VERSION "HINBNNNYNNNNNNNNNNNNNNNNNNNNNNNNNNNNNNNNNN/4/%%%/4/'%**4NNN///"

NS_ :

BS_:

BU_: dummy ZBE VVT1 VGSG SZL_LWS SM_FA SM_BF SHD RDC PGS PDC MRSZ LDM Kombi JBBF IHx FZD FRMFA_ALC FRMFA FFP EPS EKP EHC EGS_SSG Diagnosetool_PT_CAN Diagnosetool_K_CAN_System DWA DSC_DXC DME1_DDE1 CVM_V CID_V CCC_MASK_RAD CAS BMW_Tester1 AHM AFS_RP AFS ACC_Sensor RDU EBS RP_ECU_TVB
VAL_TABLE_ Wertetabelle_ST_GR_GRB 12 "8. Gang" 11 "7. Gang" 10 "6. Gang" 9 "5. Gang" 8 "4. Gang" 7 "3. Gang" 6 "2. Gang" 5 "1. Gang" 4 "Reserve" 3 "P" 2 "R" 1 "N" 0 "Reserve" ;

BO_ 3221225472 VECTOR__INDEPENDENT_SIG_MSG: 0 Vector__XXX
 SG_ ST_MDRV_DSC : 0|3@1+ (1,0) [0|0] "" Vector__XXX
 SG_ NeuesSignal_870 : 0|8@1+ (1,0) [0|0] "" Vector__XXX
 SG_ ST_INFT_ECBA : 0|3@1+ (1,0) [0|0] "" Vector__XXX
 SG_ ST_RCPT_ECBA : 0|2@1+ (1,0) [0|0] "" Vector__XXX
 SG_ ST_ECBA_SWO : 0|2@1+ (1,0) [0|0] "" Vector__XXX

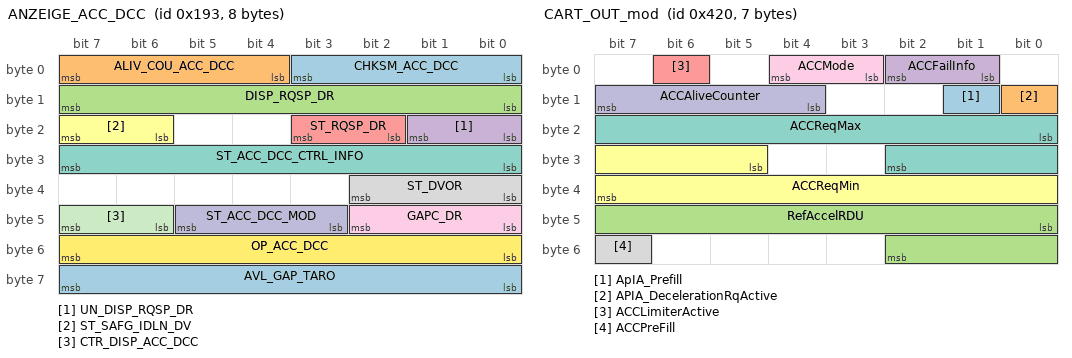
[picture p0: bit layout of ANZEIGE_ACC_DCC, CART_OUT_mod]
BO_ 403 ANZEIGE_ACC_DCC: 8 RDU
 SG_ CHKSM_ACC_DCC : 0|4@1+ (1,0) [0|0] "" Vector__XXX
 SG_ ALIV_COU_ACC_DCC : 4|4@1+ (1,0) [0|0] "" Vector__XXX
 SG_ DISP_RQSP_DR : 8|8@1+ (1,0) [0|250] "-" Vector__XXX
 SG_ UN_DISP_RQSP_DR : 16|2@1+ (1,0) [0|0] "" Vector__XXX
 SG_ ST_RQSP_DR : 18|2@1+ (1,0) [0|0] "" Vector__XXX
 SG_ ST_SAFG_IDLN_DV : 22|2@1+ (1,0) [0|0] "" Vector__XXX
 SG_ ST_ACC_DCC_CTRL_INFO : 24|8@1+ (1,0) [0|0] "" Vector__XXX
 SG_ ST_DVOR : 32|3@1+ (1,0) [0|0] "" Vector__XXX
 SG_ GAPC_DR : 40|3@1+ (1,0) [0|0] "" Vector__XXX
 SG_ ST_ACC_DCC_MOD : 43|3@1+ (1,0) [0|0] "" Vector__XXX
 SG_ CTR_DISP_ACC_DCC : 46|2@1+ (1,0) [0|0] "" Vector__XXX
 SG_ OP_ACC_DCC : 48|8@1+ (1,0) [0|0] "" Vector__XXX
 SG_ AVL_GAP_TARO : 56|8@1+ (1,0) [0|255] "" Vector__XXX

BO_ 1056 CART_OUT_mod: 7 RDU
 SG_ ApIA_Prefill : 9|1@0- (1,0) [0|0] "" Vector__XXX
 SG_ APIA_DecelerationRqActive : 8|1@0+ (1,0) [0|0] "" Vector__XXX
 SG_ RefAccelRDU : 40|11@1+ (0.01,-10.23) [-10.23|10.23] "m/s²" Vector__XXX
 SG_ ACCFailInfo : 1|2@1+ (1,0) [0|0] "" Vector__XXX
 SG_ ACCLimiterActive : 6|1@0+ (1,0) [0|1] "-" Vector__XXX
 SG_ ACCReqMin : 29|11@1+ (0.01,-10.23) [-10.23|10.23] "m/s²" Vector__XXX
 SG_ ACCReqMax : 16|11@1+ (0.01,-10.23) [-10.23|10.23] "m/s²" Vector__XXX
 SG_ ACCPreFill : 55|1@1+ (1,0) [0|1] "" Vector__XXX
 SG_ ACCMode : 3|2@1+ (1,0) [0|3] "" Vector__XXX
 SG_ ACCAliveCounter : 12|4@1+ (1,0) [0|15] "" Vector__XXX

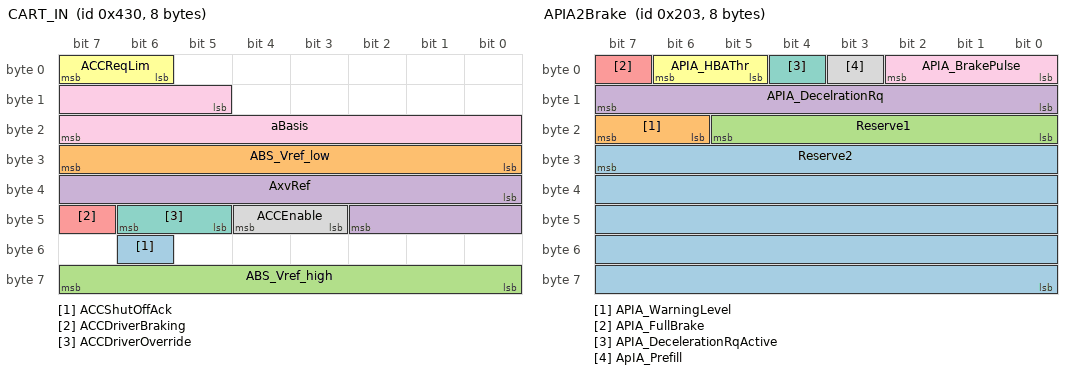
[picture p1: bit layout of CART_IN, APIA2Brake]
BO_ 1072 CART_IN: 8 EBS
 SG_ ACCShutOffAck : 54|1@1+ (1,0) [0|1] "" Vector__XXX
 SG_ ABS_Vref_low : 24|8@1+ (0.01,0) [0|0] "km/h" Vector__XXX
 SG_ ABS_Vref_high : 56|8@1- (0.01,0) [0|0] "km/h" Vector__XXX
 SG_ AxvRef : 32|11@1+ (0.01,-10.23) [-10.23|10.23] "m/s²"  RDU
 SG_ ACCDriverBraking : 47|1@1+ (1,0) [0|1] ""  RDU
 SG_ ACCReqLim : 6|2@1+ (1,0) [0|3] ""  RDU
 SG_ ACCDriverOverride : 45|2@1+ (1,0) [0|3] ""  RDU
 SG_ ACCEnable : 43|2@1+ (1,0) [0|3] ""  RDU
 SG_ aBasis : 13|11@1+ (0.01,-10.23) [-10.23|10.23] "m/s2"  RDU

BO_ 515 APIA2Brake: 8 RP_ECU_TVB
 SG_ Reserve2 : 31|40@0- (1,0) [0|0] "" Vector__XXX
 SG_ APIA_WarningLevel : 23|2@0+ (1,0) [0|0] "" Vector__XXX
 SG_ Reserve1 : 21|6@0- (1,0) [0|0] "" Vector__XXX
 SG_ APIA_DecelrationRq : 15|8@0+ (0.5,0) [0|127.5] "bar" Vector__XXX
 SG_ APIA_FullBrake : 7|1@0- (1,0) [0|0] "" Vector__XXX
 SG_ APIA_HBAThr : 6|2@0- (1,0) [0|0] "" Vector__XXX
 SG_ APIA_DecelerationRqActive : 4|1@0+ (1,0) [0|0] "" Vector__XXX
 SG_ ApIA_Prefill : 3|1@0- (1,0) [0|0] "" Vector__XXX
 SG_ APIA_BrakePulse : 2|3@0- (1,0) [0|0] "" Vector__XXX

BO_ 921 STAT_MDRIVE: 5 dummy
 SG_ ST_MDRV_DSC : 10|3@1+ (1,0) [0|0] "" Vector__XXX
 SG_ ST_MDRV : 8|2@1+ (1,0) [0|0] "" Vector__XXX
 SG_ ALIV_ST_MDRV : 4|4@1+ (1,0) [0|0] "" Vector__XXX
 SG_ CHKSM_ST_MDRV : 0|4@1+ (1,0) [0|0] "" Vector__XXX

BO_ 1777 Diag_Tester1: 8 BMW_Tester1
 SG_ TPCI : 8|8@1+ (1,0) [0|0] ""  VGSG,JBBF,FRMFA_ALC,EPS,EKP,EGS_SSG,DSC_DXC,DME1_DDE1,BMW_Tester1,AFS,ACC_Sensor
 SG_ TA : 0|8@1+ (1,0) [0|0] ""  VGSG,JBBF,FRMFA_ALC,EPS,EKP,EGS_SSG,DSC_DXC,DME1_DDE1,BMW_Tester1,AFS,ACC_Sensor
 SG_ Byte8 : 56|8@1+ (1,0) [0|0] ""  VGSG,JBBF,FRMFA_ALC,EPS,EKP,EGS_SSG,DSC_DXC,DME1_DDE1,BMW_Tester1,AFS,ACC_Sensor
 SG_ Byte7 : 48|8@1+ (1,0) [0|0] ""  VGSG,JBBF,FRMFA_ALC,EPS,EKP,EGS_SSG,DSC_DXC,DME1_DDE1,BMW_Tester1,AFS,ACC_Sensor
 SG_ Byte6 : 40|8@1+ (1,0) [0|0] ""  VGSG,JBBF,FRMFA_ALC,EPS,EKP,EGS_SSG,DSC_DXC,DME1_DDE1,BMW_Tester1,AFS,ACC_Sensor
 SG_ Byte5 : 32|8@1+ (1,0) [0|0] ""  VGSG,JBBF,FRMFA_ALC,EPS,EKP,EGS_SSG,DSC_DXC,DME1_DDE1,BMW_Tester1,AFS,ACC_Sensor
 SG_ Byte4 : 24|8@1+ (1,0) [0|0] ""  VGSG,JBBF,FRMFA_ALC,EPS,EKP,EGS_SSG,DSC_DXC,DME1_DDE1,BMW_Tester1,AFS,ACC_Sensor
 SG_ Byte3 : 16|8@1+ (1,0) [0|0] ""  VGSG,JBBF,FRMFA_ALC,EPS,EKP,EGS_SSG,DSC_DXC,DME1_DDE1,BMW_Tester1,AFS,ACC_Sensor

BO_ 1650 Diag_FRMFA_ALC: 8 FRMFA_ALC
 SG_ TPCI : 8|8@1+ (1,0) [0|0] ""  BMW_Tester1
 SG_ TA : 0|8@1+ (1,0) [0|0] ""  BMW_Tester1
 SG_ Byte8 : 56|8@1+ (1,0) [0|0] ""  BMW_Tester1
 SG_ Byte7 : 48|8@1+ (1,0) [0|0] ""  BMW_Tester1
 SG_ Byte6 : 40|8@1+ (1,0) [0|0] ""  BMW_Tester1
 SG_ Byte5 : 32|8@1+ (1,0) [0|0] ""  BMW_Tester1
 SG_ Byte4 : 24|8@1+ (1,0) [0|0] ""  BMW_Tester1
 SG_ Byte3 : 16|8@1+ (1,0) [0|0] ""  BMW_Tester1

BO_ 1584 Diag_EPS: 8 EPS
 SG_ TPCI : 8|8@1+ (1,0) [0|0] ""  BMW_Tester1
 SG_ TA : 0|8@1+ (1,0) [0|0] ""  BMW_Tester1
 SG_ Byte8 : 56|8@1+ (1,0) [0|0] ""  BMW_Tester1
 SG_ Byte7 : 48|8@1+ (1,0) [0|0] ""  BMW_Tester1
 SG_ Byte6 : 40|8@1+ (1,0) [0|0] ""  BMW_Tester1
 SG_ Byte5 : 32|8@1+ (1,0) [0|0] ""  BMW_Tester1
 SG_ Byte4 : 24|8@1+ (1,0) [0|0] ""  BMW_Tester1
 SG_ Byte3 : 16|8@1+ (1,0) [0|0] ""  BMW_Tester1

BO_ 1577 Diag_DSC_DXC: 8 DSC_DXC
 SG_ TPCI : 8|8@1+ (1,0) [0|0] ""  BMW_Tester1
 SG_ TA : 0|8@1+ (1,0) [0|0] ""  BMW_Tester1
 SG_ Byte8 : 56|8@1+ (1,0) [0|0] ""  BMW_Tester1
 SG_ Byte7 : 48|8@1+ (1,0) [0|0] ""  BMW_Tester1
 SG_ Byte6 : 40|8@1+ (1,0) [0|0] ""  BMW_Tester1
 SG_ Byte5 : 32|8@1+ (1,0) [0|0] ""  BMW_Tester1
 SG_ Byte4 : 24|8@1+ (1,0) [0|0] ""  BMW_Tester1
 SG_ Byte3 : 16|8@1+ (1,0) [0|0] ""  BMW_Tester1

BO_ 1569 Diag_ACC_Sensor: 8 ACC_Sensor
 SG_ TPCI : 8|8@1+ (1,0) [0|0] ""  BMW_Tester1
 SG_ TA : 0|8@1+ (1,0) [0|0] ""  BMW_Tester1
 SG_ Byte8 : 56|8@1+ (1,0) [0|0] ""  BMW_Tester1
 SG_ Byte7 : 48|8@1+ (1,0) [0|0] ""  BMW_Tester1
 SG_ Byte6 : 40|8@1+ (1,0) [0|0] ""  BMW_Tester1
 SG_ Byte5 : 32|8@1+ (1,0) [0|0] ""  BMW_Tester1
 SG_ Byte4 : 24|8@1+ (1,0) [0|0] ""  BMW_Tester1
 SG_ Byte3 : 16|8@1+ (1,0) [0|0] ""  BMW_Tester1

BO_ 1565 Diag_FFP: 8 FFP
 SG_ TPCI : 8|8@1+ (1,0) [0|0] ""  ACC_Sensor,AFS,BMW_Tester1,DME1_DDE1,DSC_DXC,EGS_SSG,EKP,EPS,FRMFA_ALC,JBBF,VGSG
 SG_ TA : 0|8@1+ (1,0) [0|0] ""  ACC_Sensor,AFS,BMW_Tester1,DME1_DDE1,DSC_DXC,EGS_SSG,EKP,EPS,FRMFA_ALC,JBBF,VGSG
 SG_ Byte8 : 56|8@1+ (1,0) [0|0] ""  ACC_Sensor,AFS,BMW_Tester1,DME1_DDE1,DSC_DXC,EGS_SSG,EKP,EPS,FRMFA_ALC,JBBF,VGSG
 SG_ Byte7 : 48|8@1+ (1,0) [0|0] ""  ACC_Sensor,AFS,BMW_Tester1,DME1_DDE1,DSC_DXC,EGS_SSG,EKP,EPS,FRMFA_ALC,JBBF,VGSG
 SG_ Byte6 : 40|8@1+ (1,0) [0|0] ""  ACC_Sensor,AFS,BMW_Tester1,DME1_DDE1,DSC_DXC,EGS_SSG,EKP,EPS,FRMFA_ALC,JBBF,VGSG
 SG_ Byte5 : 32|8@1+ (1,0) [0|0] ""  ACC_Sensor,AFS,BMW_Tester1,DME1_DDE1,DSC_DXC,EGS_SSG,EKP,EPS,FRMFA_ALC,JBBF,VGSG
 SG_ Byte4 : 24|8@1+ (1,0) [0|0] ""  ACC_Sensor,AFS,BMW_Tester1,DME1_DDE1,DSC_DXC,EGS_SSG,EKP,EPS,FRMFA_ALC,JBBF,VGSG
 SG_ Byte3 : 16|8@1+ (1,0) [0|0] ""  ACC_Sensor,AFS,BMW_Tester1,DME1_DDE1,DSC_DXC,EGS_SSG,EKP,EPS,FRMFA_ALC,JBBF,VGSG

BO_ 1564 Diag_LDM: 8 LDM
 SG_ TPCI : 8|8@1+ (1,0) [0|0] ""  VGSG,JBBF,FRMFA_ALC,EPS,EKP,EGS_SSG,DSC_DXC,DME1_DDE1,BMW_Tester1,AFS,ACC_Sensor
 SG_ TA : 0|8@1+ (1,0) [0|0] ""  VGSG,JBBF,FRMFA_ALC,EPS,EKP,EGS_SSG,DSC_DXC,DME1_DDE1,BMW_Tester1,AFS,ACC_Sensor
 SG_ Byte8 : 56|8@1+ (1,0) [0|0] ""  VGSG,JBBF,FRMFA_ALC,EPS,EKP,EGS_SSG,DSC_DXC,DME1_DDE1,BMW_Tester1,AFS,ACC_Sensor
 SG_ Byte7 : 48|8@1+ (1,0) [0|0] ""  VGSG,JBBF,FRMFA_ALC,EPS,EKP,EGS_SSG,DSC_DXC,DME1_DDE1,BMW_Tester1,AFS,ACC_Sensor
 SG_ Byte6 : 40|8@1+ (1,0) [0|0] ""  VGSG,JBBF,FRMFA_ALC,EPS,EKP,EGS_SSG,DSC_DXC,DME1_DDE1,BMW_Tester1,AFS,ACC_Sensor
 SG_ Byte5 : 32|8@1+ (1,0) [0|0] ""  VGSG,JBBF,FRMFA_ALC,EPS,EKP,EGS_SSG,DSC_DXC,DME1_DDE1,BMW_Tester1,AFS,ACC_Sensor
 SG_ Byte4 : 24|8@1+ (1,0) [0|0] ""  VGSG,JBBF,FRMFA_ALC,EPS,EKP,EGS_SSG,DSC_DXC,DME1_DDE1,BMW_Tester1,AFS,ACC_Sensor
 SG_ Byte3 : 16|8@1+ (1,0) [0|0] ""  VGSG,JBBF,FRMFA_ALC,EPS,EKP,EGS_SSG,DSC_DXC,DME1_DDE1,BMW_Tester1,AFS,ACC_Sensor

BO_ 1561 Diag_VGSG: 8 VGSG
 SG_ TPCI : 8|8@1+ (1,0) [0|0] ""  BMW_Tester1
 SG_ TA : 0|8@1+ (1,0) [0|0] ""  BMW_Tester1
 SG_ Byte8 : 56|8@1+ (1,0) [0|0] ""  BMW_Tester1
 SG_ Byte7 : 48|8@1+ (1,0) [0|0] ""  BMW_Tester1
 SG_ Byte6 : 40|8@1+ (1,0) [0|0] ""  BMW_Tester1
 SG_ Byte5 : 32|8@1+ (1,0) [0|0] ""  BMW_Tester1
 SG_ Byte4 : 24|8@1+ (1,0) [0|0] ""  BMW_Tester1
 SG_ Byte3 : 16|8@1+ (1,0) [0|0] ""  BMW_Tester1

BO_ 1560 Diag_EGS_SSG: 8 EGS_SSG
 SG_ TPCI : 8|8@1+ (1,0) [0|0] ""  BMW_Tester1
 SG_ TA : 0|8@1+ (1,0) [0|0] ""  BMW_Tester1
 SG_ Byte8 : 56|8@1+ (1,0) [0|0] ""  BMW_Tester1
 SG_ Byte7 : 48|8@1+ (1,0) [0|0] ""  BMW_Tester1
 SG_ Byte6 : 40|8@1+ (1,0) [0|0] ""  BMW_Tester1
 SG_ Byte5 : 32|8@1+ (1,0) [0|0] ""  BMW_Tester1
 SG_ Byte4 : 24|8@1+ (1,0) [0|0] ""  BMW_Tester1
 SG_ Byte3 : 16|8@1+ (1,0) [0|0] ""  BMW_Tester1

BO_ 1559 Diag_EKP: 8 EKP
 SG_ TPCI : 8|8@1+ (1,0) [0|0] ""  BMW_Tester1
 SG_ TA : 0|8@1+ (1,0) [0|0] ""  BMW_Tester1
 SG_ Byte8 : 56|8@1+ (1,0) [0|0] ""  BMW_Tester1
 SG_ Byte7 : 48|8@1+ (1,0) [0|0] ""  BMW_Tester1
 SG_ Byte6 : 40|8@1+ (1,0) [0|0] ""  BMW_Tester1
 SG_ Byte5 : 32|8@1+ (1,0) [0|0] ""  BMW_Tester1
 SG_ Byte4 : 24|8@1+ (1,0) [0|0] ""  BMW_Tester1
 SG_ Byte3 : 16|8@1+ (1,0) [0|0] ""  BMW_Tester1

BO_ 1558 Diag_AFS: 8 AFS
 SG_ TPCI : 8|8@1+ (1,0) [0|0] ""  BMW_Tester1
 SG_ TA : 0|8@1+ (1,0) [0|0] ""  BMW_Tester1
 SG_ Byte8 : 56|8@1+ (1,0) [0|0] ""  BMW_Tester1
 SG_ Byte7 : 48|8@1+ (1,0) [0|0] ""  BMW_Tester1
 SG_ Byte6 : 40|8@1+ (1,0) [0|0] ""  BMW_Tester1
 SG_ Byte5 : 32|8@1+ (1,0) [0|0] ""  BMW_Tester1
 SG_ Byte4 : 24|8@1+ (1,0) [0|0] ""  BMW_Tester1
 SG_ Byte3 : 16|8@1+ (1,0) [0|0] ""  BMW_Tester1

BO_ 1554 Diag_DME1_DDE1: 8 DME1_DDE1
 SG_ TPCI : 8|8@1+ (1,0) [0|0] ""  BMW_Tester1
 SG_ TA : 0|8@1+ (1,0) [0|0] ""  BMW_Tester1
 SG_ Byte8 : 56|8@1+ (1,0) [0|0] ""  BMW_Tester1
 SG_ Byte7 : 48|8@1+ (1,0) [0|0] ""  BMW_Tester1
 SG_ Byte6 : 40|8@1+ (1,0) [0|0] ""  BMW_Tester1
 SG_ Byte5 : 32|8@1+ (1,0) [0|0] ""  BMW_Tester1
 SG_ Byte4 : 24|8@1+ (1,0) [0|0] ""  BMW_Tester1
 SG_ Byte3 : 16|8@1+ (1,0) [0|0] ""  BMW_Tester1

BO_ 1536 Diag_JBBF: 8 JBBF
 SG_ TPCI : 8|8@1+ (1,0) [0|0] ""  VGSG,JBBF,FRMFA_ALC,EPS,EKP,EGS_SSG,DSC_DXC,DME1_DDE1,BMW_Tester1,AFS,ACC_Sensor
 SG_ TA : 0|8@1+ (1,0) [0|0] ""  VGSG,JBBF,FRMFA_ALC,EPS,EKP,EGS_SSG,DSC_DXC,DME1_DDE1,BMW_Tester1,AFS,ACC_Sensor
 SG_ Byte8 : 56|8@1+ (1,0) [0|0] ""  VGSG,JBBF,FRMFA_ALC,EPS,EKP,EGS_SSG,DSC_DXC,DME1_DDE1,BMW_Tester1,AFS,ACC_Sensor
 SG_ Byte7 : 48|8@1+ (1,0) [0|0] ""  VGSG,JBBF,FRMFA_ALC,EPS,EKP,EGS_SSG,DSC_DXC,DME1_DDE1,BMW_Tester1,AFS,ACC_Sensor
 SG_ Byte6 : 40|8@1+ (1,0) [0|0] ""  VGSG,JBBF,FRMFA_ALC,EPS,EKP,EGS_SSG,DSC_DXC,DME1_DDE1,BMW_Tester1,AFS,ACC_Sensor
 SG_ Byte5 : 32|8@1+ (1,0) [0|0] ""  VGSG,JBBF,FRMFA_ALC,EPS,EKP,EGS_SSG,DSC_DXC,DME1_DDE1,BMW_Tester1,AFS,ACC_Sensor
 SG_ Byte4 : 24|8@1+ (1,0) [0|0] ""  VGSG,JBBF,FRMFA_ALC,EPS,EKP,EGS_SSG,DSC_DXC,DME1_DDE1,BMW_Tester1,AFS,ACC_Sensor
 SG_ Byte3 : 16|8@1+ (1,0) [0|0] ""  VGSG,JBBF,FRMFA_ALC,EPS,EKP,EGS_SSG,DSC_DXC,DME1_DDE1,BMW_Tester1,AFS,ACC_Sensor

BO_ 1504 Rq_Test: 8 FRMFA_ALC
 SG_ ID2 : 0|8@1+ (1,0) [0|0] ""  VGSG,JBBF,EPS,EKP,EGS_SSG,DSC_DXC,DME1_DDE1,AFS,ACC_Sensor
 SG_ Byte7 : 56|8@1+ (1,0) [0|0] ""  VGSG,JBBF,EPS,EKP,EGS_SSG,DSC_DXC,DME1_DDE1,AFS,ACC_Sensor
 SG_ Byte6 : 48|8@1+ (1,0) [0|0] ""  VGSG,JBBF,EPS,EKP,EGS_SSG,DSC_DXC,DME1_DDE1,AFS,ACC_Sensor
 SG_ Byte5 : 40|8@1+ (1,0) [0|0] ""  VGSG,JBBF,EPS,EKP,EGS_SSG,DSC_DXC,DME1_DDE1,AFS,ACC_Sensor
 SG_ Byte4 : 32|8@1+ (1,0) [0|0] ""  VGSG,JBBF,EPS,EKP,EGS_SSG,DSC_DXC,DME1_DDE1,AFS,ACC_Sensor
 SG_ Byte3 : 24|8@1+ (1,0) [0|0] ""  VGSG,JBBF,EPS,EKP,EGS_SSG,DSC_DXC,DME1_DDE1,AFS,ACC_Sensor
 SG_ Byte2 : 16|8@1+ (1,0) [0|0] ""  VGSG,JBBF,EPS,EKP,EGS_SSG,DSC_DXC,DME1_DDE1,AFS,ACC_Sensor
 SG_ Byte1 : 8|8@1+ (1,0) [0|0] ""  VGSG,JBBF,EPS,EKP,EGS_SSG,DSC_DXC,DME1_DDE1,AFS,ACC_Sensor

BO_ 1456 Rq_EPS: 8 EPS
 SG_ ID2 : 0|8@1+ (1,0) [0|0] ""  VGSG,JBBF,FRMFA_ALC,EKP,EGS_SSG,DSC_DXC,DME1_DDE1,AFS,ACC_Sensor
 SG_ Byte7 : 56|8@1+ (1,0) [0|0] ""  VGSG,JBBF,FRMFA_ALC,EKP,EGS_SSG,DSC_DXC,DME1_DDE1,AFS,ACC_Sensor
 SG_ Byte6 : 48|8@1+ (1,0) [0|0] ""  VGSG,JBBF,FRMFA_ALC,EKP,EGS_SSG,DSC_DXC,DME1_DDE1,AFS,ACC_Sensor
 SG_ Byte5 : 40|8@1+ (1,0) [0|0] ""  VGSG,JBBF,FRMFA_ALC,EKP,EGS_SSG,DSC_DXC,DME1_DDE1,AFS,ACC_Sensor
 SG_ Byte4 : 32|8@1+ (1,0) [0|0] ""  VGSG,JBBF,FRMFA_ALC,EKP,EGS_SSG,DSC_DXC,DME1_DDE1,AFS,ACC_Sensor
 SG_ Byte3 : 24|8@1+ (1,0) [0|0] ""  VGSG,JBBF,FRMFA_ALC,EKP,EGS_SSG,DSC_DXC,DME1_DDE1,AFS,ACC_Sensor
 SG_ Byte2 : 16|8@1+ (1,0) [0|0] ""  VGSG,JBBF,FRMFA_ALC,EKP,EGS_SSG,DSC_DXC,DME1_DDE1,AFS,ACC_Sensor
 SG_ Byte1 : 8|8@1+ (1,0) [0|0] ""  VGSG,JBBF,FRMFA_ALC,EKP,EGS_SSG,DSC_DXC,DME1_DDE1,AFS,ACC_Sensor

BO_ 1449 Rq_DSC_DXC: 8 DSC_DXC
 SG_ ID2 : 0|8@1+ (1,0) [0|0] ""  VGSG,JBBF,FRMFA_ALC,EPS,EKP,EGS_SSG,DME1_DDE1,AFS,ACC_Sensor
 SG_ Byte7 : 56|8@1+ (1,0) [0|0] ""  VGSG,JBBF,FRMFA_ALC,EPS,EKP,EGS_SSG,DME1_DDE1,AFS,ACC_Sensor
 SG_ Byte6 : 48|8@1+ (1,0) [0|0] ""  VGSG,JBBF,FRMFA_ALC,EPS,EKP,EGS_SSG,DME1_DDE1,AFS,ACC_Sensor
 SG_ Byte5 : 40|8@1+ (1,0) [0|0] ""  VGSG,JBBF,FRMFA_ALC,EPS,EKP,EGS_SSG,DME1_DDE1,AFS,ACC_Sensor
 SG_ Byte4 : 32|8@1+ (1,0) [0|0] ""  VGSG,JBBF,FRMFA_ALC,EPS,EKP,EGS_SSG,DME1_DDE1,AFS,ACC_Sensor
 SG_ Byte3 : 24|8@1+ (1,0) [0|0] ""  VGSG,JBBF,FRMFA_ALC,EPS,EKP,EGS_SSG,DME1_DDE1,AFS,ACC_Sensor
 SG_ Byte2 : 16|8@1+ (1,0) [0|0] ""  VGSG,JBBF,FRMFA_ALC,EPS,EKP,EGS_SSG,DME1_DDE1,AFS,ACC_Sensor
 SG_ Byte1 : 8|8@1+ (1,0) [0|0] ""  VGSG,JBBF,FRMFA_ALC,EPS,EKP,EGS_SSG,DME1_DDE1,AFS,ACC_Sensor

BO_ 1441 Rq_ACC_Sensor: 8 ACC_Sensor
 SG_ ID2 : 0|8@1+ (1,0) [0|0] ""  VGSG,JBBF,FRMFA_ALC,EPS,EKP,EGS_SSG,DSC_DXC,DME1_DDE1,AFS
 SG_ Byte7 : 56|8@1+ (1,0) [0|0] ""  VGSG,JBBF,FRMFA_ALC,EPS,EKP,EGS_SSG,DSC_DXC,DME1_DDE1,AFS
 SG_ Byte6 : 48|8@1+ (1,0) [0|0] ""  VGSG,JBBF,FRMFA_ALC,EPS,EKP,EGS_SSG,DSC_DXC,DME1_DDE1,AFS
 SG_ Byte5 : 40|8@1+ (1,0) [0|0] ""  VGSG,JBBF,FRMFA_ALC,EPS,EKP,EGS_SSG,DSC_DXC,DME1_DDE1,AFS
 SG_ Byte4 : 32|8@1+ (1,0) [0|0] ""  VGSG,JBBF,FRMFA_ALC,EPS,EKP,EGS_SSG,DSC_DXC,DME1_DDE1,AFS
 SG_ Byte3 : 24|8@1+ (1,0) [0|0] ""  VGSG,JBBF,FRMFA_ALC,EPS,EKP,EGS_SSG,DSC_DXC,DME1_DDE1,AFS
 SG_ Byte2 : 16|8@1+ (1,0) [0|0] ""  VGSG,JBBF,FRMFA_ALC,EPS,EKP,EGS_SSG,DSC_DXC,DME1_DDE1,AFS
 SG_ Byte1 : 8|8@1+ (1,0) [0|0] ""  VGSG,JBBF,FRMFA_ALC,EPS,EKP,EGS_SSG,DSC_DXC,DME1_DDE1,AFS

BO_ 1437 Rq_FFP: 8 FFP
 SG_ ID2 : 0|8@1+ (1,0) [0|0] ""  ACC_Sensor,AFS,DME1_DDE1,DSC_DXC,EGS_SSG,EKP,EPS,FRMFA_ALC,JBBF,VGSG
 SG_ Byte7 : 56|8@1+ (1,0) [0|0] ""  ACC_Sensor,AFS,DME1_DDE1,DSC_DXC,EGS_SSG,EKP,EPS,FRMFA_ALC,JBBF,VGSG
 SG_ Byte6 : 48|8@1+ (1,0) [0|0] ""  ACC_Sensor,AFS,DME1_DDE1,DSC_DXC,EGS_SSG,EKP,EPS,FRMFA_ALC,JBBF,VGSG
 SG_ Byte5 : 40|8@1+ (1,0) [0|0] ""  ACC_Sensor,AFS,DME1_DDE1,DSC_DXC,EGS_SSG,EKP,EPS,FRMFA_ALC,JBBF,VGSG
 SG_ Byte4 : 32|8@1+ (1,0) [0|0] ""  ACC_Sensor,AFS,DME1_DDE1,DSC_DXC,EGS_SSG,EKP,EPS,FRMFA_ALC,JBBF,VGSG
 SG_ Byte3 : 24|8@1+ (1,0) [0|0] ""  ACC_Sensor,AFS,DME1_DDE1,DSC_DXC,EGS_SSG,EKP,EPS,FRMFA_ALC,JBBF,VGSG
 SG_ Byte2 : 16|8@1+ (1,0) [0|0] ""  ACC_Sensor,AFS,DME1_DDE1,DSC_DXC,EGS_SSG,EKP,EPS,FRMFA_ALC,JBBF,VGSG
 SG_ Byte1 : 8|8@1+ (1,0) [0|0] ""  ACC_Sensor,AFS,DME1_DDE1,DSC_DXC,EGS_SSG,EKP,EPS,FRMFA_ALC,JBBF,VGSG

BO_ 1436 Rq_LDM: 8 LDM
 SG_ ID2 : 0|8@1+ (1,0) [0|0] ""  VGSG,JBBF,FRMFA_ALC,EPS,EKP,EGS_SSG,DSC_DXC,DME1_DDE1,AFS,ACC_Sensor
 SG_ Byte7 : 56|8@1+ (1,0) [0|0] ""  VGSG,JBBF,FRMFA_ALC,EPS,EKP,EGS_SSG,DSC_DXC,DME1_DDE1,AFS,ACC_Sensor
 SG_ Byte6 : 48|8@1+ (1,0) [0|0] ""  VGSG,JBBF,FRMFA_ALC,EPS,EKP,EGS_SSG,DSC_DXC,DME1_DDE1,AFS,ACC_Sensor
 SG_ Byte5 : 40|8@1+ (1,0) [0|0] ""  VGSG,JBBF,FRMFA_ALC,EPS,EKP,EGS_SSG,DSC_DXC,DME1_DDE1,AFS,ACC_Sensor
 SG_ Byte4 : 32|8@1+ (1,0) [0|0] ""  VGSG,JBBF,FRMFA_ALC,EPS,EKP,EGS_SSG,DSC_DXC,DME1_DDE1,AFS,ACC_Sensor
 SG_ Byte3 : 24|8@1+ (1,0) [0|0] ""  VGSG,JBBF,FRMFA_ALC,EPS,EKP,EGS_SSG,DSC_DXC,DME1_DDE1,AFS,ACC_Sensor
 SG_ Byte2 : 16|8@1+ (1,0) [0|0] ""  VGSG,JBBF,FRMFA_ALC,EPS,EKP,EGS_SSG,DSC_DXC,DME1_DDE1,AFS,ACC_Sensor
 SG_ Byte1 : 8|8@1+ (1,0) [0|0] ""  VGSG,JBBF,FRMFA_ALC,EPS,EKP,EGS_SSG,DSC_DXC,DME1_DDE1,AFS,ACC_Sensor

BO_ 1433 Rq_VGSG: 8 VGSG
 SG_ ID2 : 0|8@1+ (1,0) [0|0] ""  JBBF,FRMFA_ALC,EPS,EKP,EGS_SSG,DSC_DXC,DME1_DDE1,AFS,ACC_Sensor
 SG_ Byte7 : 56|8@1+ (1,0) [0|0] ""  JBBF,FRMFA_ALC,EPS,EKP,EGS_SSG,DSC_DXC,DME1_DDE1,AFS,ACC_Sensor
 SG_ Byte6 : 48|8@1+ (1,0) [0|0] ""  JBBF,FRMFA_ALC,EPS,EKP,EGS_SSG,DSC_DXC,DME1_DDE1,AFS,ACC_Sensor
 SG_ Byte5 : 40|8@1+ (1,0) [0|0] ""  JBBF,FRMFA_ALC,EPS,EKP,EGS_SSG,DSC_DXC,DME1_DDE1,AFS,ACC_Sensor
 SG_ Byte4 : 32|8@1+ (1,0) [0|0] ""  JBBF,FRMFA_ALC,EPS,EKP,EGS_SSG,DSC_DXC,DME1_DDE1,AFS,ACC_Sensor
 SG_ Byte3 : 24|8@1+ (1,0) [0|0] ""  JBBF,FRMFA_ALC,EPS,EKP,EGS_SSG,DSC_DXC,DME1_DDE1,AFS,ACC_Sensor
 SG_ Byte2 : 16|8@1+ (1,0) [0|0] ""  JBBF,FRMFA_ALC,EPS,EKP,EGS_SSG,DSC_DXC,DME1_DDE1,AFS,ACC_Sensor
 SG_ Byte1 : 8|8@1+ (1,0) [0|0] ""  JBBF,FRMFA_ALC,EPS,EKP,EGS_SSG,DSC_DXC,DME1_DDE1,AFS,ACC_Sensor

BO_ 1432 Rq_EGS_SSG: 8 EGS_SSG
 SG_ ID2 : 0|8@1+ (1,0) [0|0] ""  VGSG,JBBF,FRMFA_ALC,EPS,EKP,DSC_DXC,DME1_DDE1,AFS,ACC_Sensor
 SG_ Byte7 : 56|8@1+ (1,0) [0|0] ""  VGSG,JBBF,FRMFA_ALC,EPS,EKP,DSC_DXC,DME1_DDE1,AFS,ACC_Sensor
 SG_ Byte6 : 48|8@1+ (1,0) [0|0] ""  VGSG,JBBF,FRMFA_ALC,EPS,EKP,DSC_DXC,DME1_DDE1,AFS,ACC_Sensor
 SG_ Byte5 : 40|8@1+ (1,0) [0|0] ""  VGSG,JBBF,FRMFA_ALC,EPS,EKP,DSC_DXC,DME1_DDE1,AFS,ACC_Sensor
 SG_ Byte4 : 32|8@1+ (1,0) [0|0] ""  VGSG,JBBF,FRMFA_ALC,EPS,EKP,DSC_DXC,DME1_DDE1,AFS,ACC_Sensor
 SG_ Byte3 : 24|8@1+ (1,0) [0|0] ""  VGSG,JBBF,FRMFA_ALC,EPS,EKP,DSC_DXC,DME1_DDE1,AFS,ACC_Sensor
 SG_ Byte2 : 16|8@1+ (1,0) [0|0] ""  VGSG,JBBF,FRMFA_ALC,EPS,EKP,DSC_DXC,DME1_DDE1,AFS,ACC_Sensor
 SG_ Byte1 : 8|8@1+ (1,0) [0|0] ""  VGSG,JBBF,FRMFA_ALC,EPS,EKP,DSC_DXC,DME1_DDE1,AFS,ACC_Sensor

BO_ 1431 Rq_EKP: 8 EKP
 SG_ ID2 : 0|8@1+ (1,0) [0|0] ""  VGSG,JBBF,FRMFA_ALC,EPS,EGS_SSG,DSC_DXC,DME1_DDE1,AFS,ACC_Sensor
 SG_ Byte7 : 56|8@1+ (1,0) [0|0] ""  VGSG,JBBF,FRMFA_ALC,EPS,EGS_SSG,DSC_DXC,DME1_DDE1,AFS,ACC_Sensor
 SG_ Byte6 : 48|8@1+ (1,0) [0|0] ""  VGSG,JBBF,FRMFA_ALC,EPS,EGS_SSG,DSC_DXC,DME1_DDE1,AFS,ACC_Sensor
 SG_ Byte5 : 40|8@1+ (1,0) [0|0] ""  VGSG,JBBF,FRMFA_ALC,EPS,EGS_SSG,DSC_DXC,DME1_DDE1,AFS,ACC_Sensor
 SG_ Byte4 : 32|8@1+ (1,0) [0|0] ""  VGSG,JBBF,FRMFA_ALC,EPS,EGS_SSG,DSC_DXC,DME1_DDE1,AFS,ACC_Sensor
 SG_ Byte3 : 24|8@1+ (1,0) [0|0] ""  VGSG,JBBF,FRMFA_ALC,EPS,EGS_SSG,DSC_DXC,DME1_DDE1,AFS,ACC_Sensor
 SG_ Byte2 : 16|8@1+ (1,0) [0|0] ""  VGSG,JBBF,FRMFA_ALC,EPS,EGS_SSG,DSC_DXC,DME1_DDE1,AFS,ACC_Sensor
 SG_ Byte1 : 8|8@1+ (1,0) [0|0] ""  VGSG,JBBF,FRMFA_ALC,EPS,EGS_SSG,DSC_DXC,DME1_DDE1,AFS,ACC_Sensor

BO_ 1430 Rq_AFS: 8 AFS
 SG_ ID2 : 0|8@1+ (1,0) [0|0] ""  VGSG,JBBF,FRMFA_ALC,EPS,EKP,EGS_SSG,DSC_DXC,DME1_DDE1,ACC_Sensor
 SG_ Byte7 : 56|8@1+ (1,0) [0|0] ""  VGSG,JBBF,FRMFA_ALC,EPS,EKP,EGS_SSG,DSC_DXC,DME1_DDE1,ACC_Sensor
 SG_ Byte6 : 48|8@1+ (1,0) [0|0] ""  VGSG,JBBF,FRMFA_ALC,EPS,EKP,EGS_SSG,DSC_DXC,DME1_DDE1,ACC_Sensor
 SG_ Byte5 : 40|8@1+ (1,0) [0|0] ""  VGSG,JBBF,FRMFA_ALC,EPS,EKP,EGS_SSG,DSC_DXC,DME1_DDE1,ACC_Sensor
 SG_ Byte4 : 32|8@1+ (1,0) [0|0] ""  VGSG,JBBF,FRMFA_ALC,EPS,EKP,EGS_SSG,DSC_DXC,DME1_DDE1,ACC_Sensor
 SG_ Byte3 : 24|8@1+ (1,0) [0|0] ""  VGSG,JBBF,FRMFA_ALC,EPS,EKP,EGS_SSG,DSC_DXC,DME1_DDE1,ACC_Sensor
 SG_ Byte2 : 16|8@1+ (1,0) [0|0] ""  VGSG,JBBF,FRMFA_ALC,EPS,EKP,EGS_SSG,DSC_DXC,DME1_DDE1,ACC_Sensor
 SG_ Byte1 : 8|8@1+ (1,0) [0|0] ""  VGSG,JBBF,FRMFA_ALC,EPS,EKP,EGS_SSG,DSC_DXC,DME1_DDE1,ACC_Sensor

BO_ 1426 Rq_DME1_DDE1: 8 DME1_DDE1
 SG_ ID2 : 0|8@1+ (1,0) [0|0] ""  VGSG,JBBF,FRMFA_ALC,EPS,EKP,EGS_SSG,DSC_DXC,AFS,ACC_Sensor
 SG_ Byte7 : 56|8@1+ (1,0) [0|0] ""  VGSG,JBBF,FRMFA_ALC,EPS,EKP,EGS_SSG,DSC_DXC,AFS,ACC_Sensor
 SG_ Byte6 : 48|8@1+ (1,0) [0|0] ""  VGSG,JBBF,FRMFA_ALC,EPS,EKP,EGS_SSG,DSC_DXC,AFS,ACC_Sensor
 SG_ Byte5 : 40|8@1+ (1,0) [0|0] ""  VGSG,JBBF,FRMFA_ALC,EPS,EKP,EGS_SSG,DSC_DXC,AFS,ACC_Sensor
 SG_ Byte4 : 32|8@1+ (1,0) [0|0] ""  VGSG,JBBF,FRMFA_ALC,EPS,EKP,EGS_SSG,DSC_DXC,AFS,ACC_Sensor
 SG_ Byte3 : 24|8@1+ (1,0) [0|0] ""  VGSG,JBBF,FRMFA_ALC,EPS,EKP,EGS_SSG,DSC_DXC,AFS,ACC_Sensor
 SG_ Byte2 : 16|8@1+ (1,0) [0|0] ""  VGSG,JBBF,FRMFA_ALC,EPS,EKP,EGS_SSG,DSC_DXC,AFS,ACC_Sensor
 SG_ Byte1 : 8|8@1+ (1,0) [0|0] ""  VGSG,JBBF,FRMFA_ALC,EPS,EKP,EGS_SSG,DSC_DXC,AFS,ACC_Sensor

BO_ 1408 Rq_JBBF: 8 JBBF
 SG_ ID2 : 0|8@1+ (1,0) [0|0] ""  VGSG,JBBF,FRMFA_ALC,EPS,EKP,EGS_SSG,DSC_DXC,DME1_DDE1,AFS,ACC_Sensor
 SG_ Byte7 : 56|8@1+ (1,0) [0|0] ""  VGSG,JBBF,FRMFA_ALC,EPS,EKP,EGS_SSG,DSC_DXC,DME1_DDE1,AFS,ACC_Sensor
 SG_ Byte6 : 48|8@1+ (1,0) [0|0] ""  VGSG,JBBF,FRMFA_ALC,EPS,EKP,EGS_SSG,DSC_DXC,DME1_DDE1,AFS,ACC_Sensor
 SG_ Byte5 : 40|8@1+ (1,0) [0|0] ""  VGSG,JBBF,FRMFA_ALC,EPS,EKP,EGS_SSG,DSC_DXC,DME1_DDE1,AFS,ACC_Sensor
 SG_ Byte4 : 32|8@1+ (1,0) [0|0] ""  VGSG,JBBF,FRMFA_ALC,EPS,EKP,EGS_SSG,DSC_DXC,DME1_DDE1,AFS,ACC_Sensor
 SG_ Byte3 : 24|8@1+ (1,0) [0|0] ""  VGSG,JBBF,FRMFA_ALC,EPS,EKP,EGS_SSG,DSC_DXC,DME1_DDE1,AFS,ACC_Sensor
 SG_ Byte2 : 16|8@1+ (1,0) [0|0] ""  VGSG,JBBF,FRMFA_ALC,EPS,EKP,EGS_SSG,DSC_DXC,DME1_DDE1,AFS,ACC_Sensor
 SG_ Byte1 : 8|8@1+ (1,0) [0|0] ""  VGSG,JBBF,FRMFA_ALC,EPS,EKP,EGS_SSG,DSC_DXC,DME1_DDE1,AFS,ACC_Sensor

BO_ 1266 NM_FRMFA_ALC: 8 FRMFA_ALC
 SG_ NMPDU : 8|8@1+ (1,0) [0|0] ""  ACC_Sensor,AFS,DME1_DDE1,DSC_DXC,EGS_SSG,EKP,EPS,JBBF,VGSG
 SG_ Destination : 0|6@1+ (1,0) [0|0] ""  ACC_Sensor,AFS,DME1_DDE1,DSC_DXC,EGS_SSG,EKP,EPS,JBBF,VGSG
 SG_ Byte4 : 24|8@1+ (1,0) [0|0] ""  ACC_Sensor,AFS,DME1_DDE1,DSC_DXC,EGS_SSG,EKP,EPS,JBBF,VGSG
 SG_ Byte3 : 16|8@1+ (1,0) [0|0] ""  ACC_Sensor,AFS,DME1_DDE1,DSC_DXC,EGS_SSG,EKP,EPS,JBBF,VGSG

BO_ 1200 NM_EPS: 8 EPS
 SG_ NMPDU : 8|8@1+ (1,0) [0|0] ""  ACC_Sensor,AFS,DME1_DDE1,DSC_DXC,EGS_SSG,EKP,FRMFA_ALC,JBBF,VGSG
 SG_ Destination : 0|6@1+ (1,0) [0|0] ""  ACC_Sensor,AFS,DME1_DDE1,DSC_DXC,EGS_SSG,EKP,FRMFA_ALC,JBBF,VGSG
 SG_ Byte4 : 24|8@1+ (1,0) [0|0] ""  ACC_Sensor,AFS,DME1_DDE1,DSC_DXC,EGS_SSG,EKP,FRMFA_ALC,JBBF,VGSG
 SG_ Byte3 : 16|8@1+ (1,0) [0|0] ""  ACC_Sensor,AFS,DME1_DDE1,DSC_DXC,EGS_SSG,EKP,FRMFA_ALC,JBBF,VGSG

BO_ 1193 NM_DSC_DXC: 8 DSC_DXC
 SG_ NMPDU : 8|8@1+ (1,0) [0|0] ""  ACC_Sensor,AFS,DME1_DDE1,EGS_SSG,EKP,EPS,FRMFA_ALC,JBBF,VGSG
 SG_ Destination : 0|6@1+ (1,0) [0|0] ""  ACC_Sensor,AFS,DME1_DDE1,EGS_SSG,EKP,EPS,FRMFA_ALC,JBBF,VGSG
 SG_ Byte4 : 24|8@1+ (1,0) [0|0] ""  ACC_Sensor,AFS,DME1_DDE1,EGS_SSG,EKP,EPS,FRMFA_ALC,JBBF,VGSG
 SG_ Byte3 : 16|8@1+ (1,0) [0|0] ""  ACC_Sensor,AFS,DME1_DDE1,EGS_SSG,EKP,EPS,FRMFA_ALC,JBBF,VGSG

BO_ 1185 NM_ACC_Sensor: 8 ACC_Sensor
 SG_ NMPDU : 8|8@1+ (1,0) [0|0] ""  AFS,DME1_DDE1,DSC_DXC,EGS_SSG,EKP,EPS,FRMFA_ALC,JBBF,VGSG
 SG_ Destination : 0|6@1+ (1,0) [0|0] ""  AFS,DME1_DDE1,DSC_DXC,EGS_SSG,EKP,EPS,FRMFA_ALC,JBBF,VGSG
 SG_ Byte4 : 24|8@1+ (1,0) [0|0] ""  AFS,DME1_DDE1,DSC_DXC,EGS_SSG,EKP,EPS,FRMFA_ALC,JBBF,VGSG
 SG_ Byte3 : 16|8@1+ (1,0) [0|0] ""  AFS,DME1_DDE1,DSC_DXC,EGS_SSG,EKP,EPS,FRMFA_ALC,JBBF,VGSG

BO_ 1181 NM_FFP: 8 FFP
 SG_ NMPDU : 8|8@1+ (1,0) [0|0] ""  ACC_Sensor,AFS,DME1_DDE1,DSC_DXC,EGS_SSG,EKP,EPS,FRMFA_ALC,JBBF,VGSG
 SG_ Destination : 0|6@1+ (1,0) [0|0] ""  ACC_Sensor,AFS,DME1_DDE1,DSC_DXC,EGS_SSG,EKP,EPS,FRMFA_ALC,JBBF,VGSG
 SG_ Byte4 : 24|8@1+ (1,0) [0|0] ""  ACC_Sensor,AFS,DME1_DDE1,DSC_DXC,EGS_SSG,EKP,EPS,FRMFA_ALC,JBBF,VGSG
 SG_ Byte3 : 16|8@1+ (1,0) [0|0] ""  ACC_Sensor,AFS,DME1_DDE1,DSC_DXC,EGS_SSG,EKP,EPS,FRMFA_ALC,JBBF,VGSG

BO_ 1180 NM_LDM: 8 LDM
 SG_ NMPDU : 8|8@1+ (1,0) [0|0] ""  VGSG,JBBF,FRMFA_ALC,EPS,EKP,EGS_SSG,DSC_DXC,DME1_DDE1,AFS,ACC_Sensor
 SG_ Destination : 0|6@1+ (1,0) [0|0] ""  VGSG,JBBF,FRMFA_ALC,EPS,EKP,EGS_SSG,DSC_DXC,DME1_DDE1,AFS,ACC_Sensor
 SG_ Byte4 : 24|8@1+ (1,0) [0|0] ""  VGSG,JBBF,FRMFA_ALC,EPS,EKP,EGS_SSG,DSC_DXC,DME1_DDE1,AFS,ACC_Sensor
 SG_ Byte3 : 16|8@1+ (1,0) [0|0] ""  VGSG,JBBF,FRMFA_ALC,EPS,EKP,EGS_SSG,DSC_DXC,DME1_DDE1,AFS,ACC_Sensor

BO_ 1177 NM_VGSG: 8 VGSG
 SG_ NMPDU : 8|8@1+ (1,0) [0|0] ""  ACC_Sensor,AFS,DME1_DDE1,DSC_DXC,EGS_SSG,EKP,EPS,FRMFA_ALC,JBBF
 SG_ Destination : 0|6@1+ (1,0) [0|0] ""  ACC_Sensor,AFS,DME1_DDE1,DSC_DXC,EGS_SSG,EKP,EPS,FRMFA_ALC,JBBF
 SG_ Byte4 : 24|8@1+ (1,0) [0|0] ""  ACC_Sensor,AFS,DME1_DDE1,DSC_DXC,EGS_SSG,EKP,EPS,FRMFA_ALC,JBBF
 SG_ Byte3 : 16|8@1+ (1,0) [0|0] ""  ACC_Sensor,AFS,DME1_DDE1,DSC_DXC,EGS_SSG,EKP,EPS,FRMFA_ALC,JBBF

BO_ 1176 NM_EGS_SSG: 8 EGS_SSG
 SG_ NMPDU : 8|8@1+ (1,0) [0|0] ""  ACC_Sensor,AFS,DME1_DDE1,DSC_DXC,EKP,EPS,FRMFA_ALC,JBBF,VGSG
 SG_ Destination : 0|6@1+ (1,0) [0|0] ""  ACC_Sensor,AFS,DME1_DDE1,DSC_DXC,EKP,EPS,FRMFA_ALC,JBBF,VGSG
 SG_ Byte4 : 24|8@1+ (1,0) [0|0] ""  ACC_Sensor,AFS,DME1_DDE1,DSC_DXC,EKP,EPS,FRMFA_ALC,JBBF,VGSG
 SG_ Byte3 : 16|8@1+ (1,0) [0|0] ""  ACC_Sensor,AFS,DME1_DDE1,DSC_DXC,EKP,EPS,FRMFA_ALC,JBBF,VGSG

BO_ 1175 NM_EKP: 8 EKP
 SG_ NMPDU : 8|8@1+ (1,0) [0|0] ""  ACC_Sensor,AFS,DME1_DDE1,DSC_DXC,EGS_SSG,EPS,FRMFA_ALC,JBBF,VGSG
 SG_ Destination : 0|6@1+ (1,0) [0|0] ""  ACC_Sensor,AFS,DME1_DDE1,DSC_DXC,EGS_SSG,EPS,FRMFA_ALC,JBBF,VGSG
 SG_ Byte4 : 24|8@1+ (1,0) [0|0] ""  ACC_Sensor,AFS,DME1_DDE1,DSC_DXC,EGS_SSG,EPS,FRMFA_ALC,JBBF,VGSG
 SG_ Byte3 : 16|8@1+ (1,0) [0|0] ""  ACC_Sensor,AFS,DME1_DDE1,DSC_DXC,EGS_SSG,EPS,FRMFA_ALC,JBBF,VGSG

BO_ 1174 NM_AFS: 8 AFS
 SG_ NMPDU : 8|8@1+ (1,0) [0|0] ""  ACC_Sensor,DME1_DDE1,DSC_DXC,EGS_SSG,EKP,EPS,FRMFA_ALC,JBBF,VGSG
 SG_ Destination : 0|6@1+ (1,0) [0|0] ""  ACC_Sensor,DME1_DDE1,DSC_DXC,EGS_SSG,EKP,EPS,FRMFA_ALC,JBBF,VGSG
 SG_ Byte4 : 24|8@1+ (1,0) [0|0] ""  ACC_Sensor,DME1_DDE1,DSC_DXC,EGS_SSG,EKP,EPS,FRMFA_ALC,JBBF,VGSG
 SG_ Byte3 : 16|8@1+ (1,0) [0|0] ""  ACC_Sensor,DME1_DDE1,DSC_DXC,EGS_SSG,EKP,EPS,FRMFA_ALC,JBBF,VGSG

BO_ 1170 NM_DME1_DDE1: 8 DME1_DDE1
 SG_ NMPDU : 8|8@1+ (1,0) [0|0] ""  ACC_Sensor,AFS,DSC_DXC,EGS_SSG,EKP,EPS,FRMFA_ALC,JBBF,VGSG
 SG_ Destination : 0|6@1+ (1,0) [0|0] ""  ACC_Sensor,AFS,DSC_DXC,EGS_SSG,EKP,EPS,FRMFA_ALC,JBBF,VGSG
 SG_ Byte4 : 24|8@1+ (1,0) [0|0] ""  ACC_Sensor,AFS,DSC_DXC,EGS_SSG,EKP,EPS,FRMFA_ALC,JBBF,VGSG
 SG_ Byte3 : 16|8@1+ (1,0) [0|0] ""  ACC_Sensor,AFS,DSC_DXC,EGS_SSG,EKP,EPS,FRMFA_ALC,JBBF,VGSG

BO_ 1152 NM_JBBF: 8 JBBF
 SG_ NMPDU : 8|8@1+ (1,0) [0|0] ""  ACC_Sensor,AFS,DME1_DDE1,DSC_DXC,EGS_SSG,EKP,EPS,FRMFA_ALC,JBBF,VGSG
 SG_ Destination : 0|6@1+ (1,0) [0|0] ""  ACC_Sensor,AFS,DME1_DDE1,DSC_DXC,EGS_SSG,EKP,EPS,FRMFA_ALC,JBBF,VGSG
 SG_ Byte4 : 24|8@1+ (1,0) [0|0] ""  ACC_Sensor,AFS,DME1_DDE1,DSC_DXC,EGS_SSG,EKP,EPS,FRMFA_ALC,JBBF,VGSG
 SG_ Byte3 : 16|8@1+ (1,0) [0|0] ""  ACC_Sensor,AFS,DME1_DDE1,DSC_DXC,EGS_SSG,EKP,EPS,FRMFA_ALC,JBBF,VGSG

BO_ 1003 MRKR_3: 8 Diagnosetool_PT_CAN
 SG_ ST_MRK_3 : 24|4@1+ (1,0) [0|0] ""  Diagnosetool_K_CAN_System
 SG_ NO_MRK_3 : 0|16@1+ (1,0) [0|0] ""  Diagnosetool_K_CAN_System
 SG_ MUX_3 : 28|4@1+ (1,0) [0|0] ""  Diagnosetool_K_CAN_System
 SG_ IDX_MRK_3 : 16|8@1+ (1,0) [0|0] ""  Diagnosetool_K_CAN_System
 SG_ CAN_ID_3 : 32|16@1+ (1,0) [0|0] ""  Diagnosetool_K_CAN_System

BO_ 1002 MRKR_2: 8 Diagnosetool_K_CAN_System
 SG_ ST_MRK_2 : 24|4@1+ (1,0) [0|0] ""  Diagnosetool_PT_CAN
 SG_ NO_TAB_GW : 40|24@1+ (1,0) [0|0] ""  Diagnosetool_PT_CAN
 SG_ NO_MRK_2 : 0|16@1+ (1,0) [0|0] ""  Diagnosetool_PT_CAN
 SG_ MULT : 28|4@1+ (1,0) [0|0] ""  Diagnosetool_PT_CAN
 SG_ IDX_MRK_2 : 16|8@1+ (1,0) [0|0] ""  Diagnosetool_PT_CAN
 SG_ CAN_ID_2 : 40|16@1+ (1,0) [0|0] ""  Diagnosetool_PT_CAN

BO_ 1001 MRKR: 8 dummy
 SG_ ST_MRK_1 : 24|4@1+ (1,0) [0|0] ""  Diagnosetool_PT_CAN,Diagnosetool_K_CAN_System
 SG_ NO_MRK_1 : 0|16@1+ (1,0) [0|0] ""  Diagnosetool_PT_CAN,Diagnosetool_K_CAN_System
 SG_ MUX_1 : 28|4@1+ (1,0) [0|0] ""  Diagnosetool_PT_CAN,Diagnosetool_K_CAN_System
 SG_ IDX_MRK_1 : 16|8@1+ (1,0) [0|0] ""  Diagnosetool_PT_CAN,Diagnosetool_K_CAN_System
 SG_ CAN_ID_1 : 32|16@1+ (1,0) [0|0] ""  Diagnosetool_PT_CAN,Diagnosetool_K_CAN_System

BO_ 987 ST_MEM_POS_CKM: 2 SM_FA
 SG_ ST_AD_SEAT_STCO_EXMI_CKM : 0|3@1+ (1,0) [0|0] ""  CCC_MASK_RAD

BO_ 958 FLLUPT_GPWSUP: 2 CAS
 SG_ FLLUPT_GPWSUP : 0|12@1+ (10,0) [0|0] "s"  JBBF,IHx,CID_V,CCC_MASK_RAD

BO_ 957 STAT_COS_SWO: 2 FRMFA
 SG_ ST_KL_VA : 0|2@1+ (1,0) [0|0] ""  FZD,FRMFA,CID_V

BO_ 949 STAT_WV: 2 JBBF
 SG_ ST_WV : 0|4@1+ (1,0) [0|0] ""  DME1_DDE1
 SG_ ST_APE_WV : 4|4@1+ (10,0) [0|0] "%"  DME1_DDE1

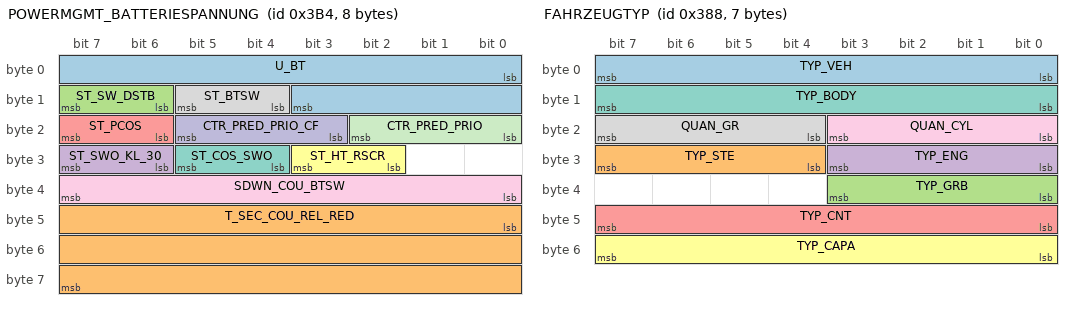
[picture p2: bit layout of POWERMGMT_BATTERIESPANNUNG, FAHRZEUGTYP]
BO_ 948 POWERMGMT_BATTERIESPANNUNG: 8 DME1_DDE1
 SG_ U_BT : 0|12@1+ (15,0) [0|0] "mV"  PGS,PDC,MRSZ,Kombi,JBBF,IHx,FRMFA,CID_V,CCC_MASK_RAD,CAS,AHM
 SG_ T_SEC_COU_REL_RED : 40|24@1+ (1,0) [0|0] "s"  ZBE,DME1_DDE1,CID_V
 SG_ ST_SW_DSTB : 14|2@1+ (1,0) [0|0] ""  Kombi,DWA,CID_V,CAS
 SG_ ST_SWO_KL_30 : 30|2@1+ (1,0) [0|0] ""  DME1_DDE1,CID_V
 SG_ ST_PCOS : 22|2@1+ (1,0) [0|0] ""  FRMFA,CCC_MASK_RAD,AHM
 SG_ ST_HT_RSCR : 26|2@1+ (1,0) [0|0] "" Vector__XXX
 SG_ ST_COS_SWO : 28|2@1+ (1,0) [0|0] "" Vector__XXX
 SG_ ST_BTSW : 12|2@1+ (1,0) [0|0] ""  Kombi,EHC,DWA,DME1_DDE1,CID_V,CAS
 SG_ SDWN_COU_BTSW : 32|8@1+ (1,0) [0|0] "s"  DME1_DDE1,CID_V,CAS
 SG_ CTR_PRED_PRIO_CF : 19|3@1+ (1,0) [0|0] "" Vector__XXX
 SG_ CTR_PRED_PRIO : 16|3@1+ (1,0) [0|0] ""  JBBF

BO_ 947 POWERMGMT_CTR_COS: 6 DME1_DDE1
 SG_ ULEV : 0|4@1+ (1,0) [0|0] "" Vector__XXX
 SG_ SLCTN_SPCOS : 4|4@1+ (1,0) [0|0] ""  IHx
 SG_ RQ_PCOS : 40|2@1+ (1,0) [0|0] ""  IHx,FRMFA,DWA,CCC_MASK_RAD,AHM
 SG_ CTR_PWR_SPCOS : 8|8@1+ (0.5,0) [0|0] "%"  IHx
 SG_ CTR_PWR_COS : 16|16@1+ (1,0) [0|0] ""  SM_FA,SM_BF,JBBF,IHx,FRMFA
 SG_ CTR_PCOS : 42|2@1+ (1,0) [0|0] ""  JBBF,IHx,CCC_MASK_RAD
 SG_ CTR_CBR : 32|8@1+ (1,0) [0|0] ""  CAS

BO_ 944 STAT_GANG_RUECKWAERTS: 2 FRMFA
 SG_ ST_GR_BAC : 0|2@1+ (1,0) [0|0] ""  PDC,LDM,JBBF,FZD,FRMFA,DSC_DXC,DME1_DDE1,CCC_MASK_RAD

BO_ 924 EBA_REQUEST: 8 CCC_MASK_RAD
 SG_ ST_EBA_MOD : 8|2@1+ (1,0) [0|0] ""  SHD,PDC,FZD,CAS
 SG_ ID2_EBA_DT_RQ : 0|8@1+ (1,0) [0|0] ""  SHD,PDC,FZD,CAS

BO_ 920 BEDIENUNG_FAHRWERK: 2 CCC_MASK_RAD
 SG_ OP_TPCT : 4|2@1+ (1,0) [0|0] ""  RDC,LDM,DSC_DXC
 SG_ OP_RADA_ACC : 8|2@1+ (1,0) [0|0] ""  LDM
 SG_ OP_MOD_TRCT_DSC : 10|3@1+ (1,0) [0|0] ""  LDM,DSC_DXC
 SG_ OP_EDCK_PRG_CFSP : 2|2@1+ (1,0) [0|0] ""  LDM
 SG_ OP_CFFU_EMF : 6|2@1+ (1,0) [0|0] ""  LDM

BO_ 917 CODIERUNG_PM: 5 CAS
 SG_ QC_VEH : 8|8@1+ (1,0) [0|0] "mA"  DME1_DDE1
 SG_ I_SC_MIN_VEH : 16|8@1+ (10,0) [0|0] "A"  DME1_DDE1
 SG_ I_SC_MAX_VEH : 24|8@1+ (10,0) [0|0] "A"  DME1_DDE1
 SG_ CLAS_BT : 0|8@1+ (1,0) [0|0] ""  DME1_DDE1

BO_ 910 RPM_STA: 2 DME1_DDE1
 SG_ RPM_ENG_STA : 0|16@1+ (0.25,0) [0|0] "1/min" Vector__XXX

BO_ 904 FAHRZEUGTYP: 7 CAS
 SG_ TYP_VEH : 0|8@1+ (1,0) [0|0] ""  RDC,LDM,Kombi,DWA,DSC_DXC,CCC_MASK_RAD
 SG_ TYP_STE : 28|4@1+ (1,0) [0|0] ""  SM_FA,SM_BF,LDM,Kombi,IHx,CCC_MASK_RAD
 SG_ TYP_GRB : 32|4@1+ (1,0) [0|0] ""  LDM,Kombi,DSC_DXC,CCC_MASK_RAD
 SG_ TYP_ENG : 24|4@1+ (1,0) [0|0] ""  LDM,Kombi,DSC_DXC,CCC_MASK_RAD
 SG_ TYP_CNT : 40|8@1+ (1,0) [0|0] ""  RDC,LDM,Kombi,DSC_DXC,CCC_MASK_RAD
 SG_ TYP_CAPA : 48|8@1+ (100,0) [0|0] "ccm"  LDM,DSC_DXC,CCC_MASK_RAD
 SG_ TYP_BODY : 8|8@1+ (1,0) [0|0] ""  LDM,Kombi,DWA,DSC_DXC,CCC_MASK_RAD
 SG_ QUAN_GR : 20|4@1+ (1,0) [0|0] ""  LDM,Kombi,DSC_DXC,CCC_MASK_RAD
 SG_ QUAN_CYL : 16|4@1+ (1,0) [0|0] ""  LDM,Kombi,DSC_DXC,CCC_MASK_RAD

BO_ 897 ELKTR_M_OEL_MESS: 2 DME1_DDE1
 SG_ RECM_RFLV_EOI : 8|4@1+ (1,0) [0|0] ""  Kombi
 SG_ FLLV_EOI : 0|8@1+ (1,0) [0|0] "-"  Kombi

BO_ 896 FAHRGESTELLNUMMER: 7 CAS
 SG_ NO_VECH_7 : 48|8@1+ (1,0) [0|0] ""  VGSG,LDM,Kombi,IHx,DSC_DXC,AFS
 SG_ NO_VECH_6 : 40|8@1+ (1,0) [0|0] ""  VGSG,LDM,Kombi,IHx,DSC_DXC,AFS
 SG_ NO_VECH_5 : 32|8@1+ (1,0) [0|0] ""  VGSG,LDM,Kombi,IHx,DSC_DXC,AFS
 SG_ NO_VECH_4 : 24|8@1+ (1,0) [0|0] ""  VGSG,LDM,Kombi,IHx,DSC_DXC,AFS
 SG_ NO_VECH_3 : 16|8@1+ (1,0) [0|0] ""  VGSG,LDM,Kombi,IHx,DSC_DXC,AFS
 SG_ NO_VECH_2 : 8|8@1+ (1,0) [0|0] ""  VGSG,LDM,Kombi,IHx,DSC_DXC,AFS
 SG_ NO_VECH_1 : 0|8@1+ (1,0) [0|0] ""  VGSG,LDM,Kombi,IHx,DSC_DXC,AFS

BO_ 886 ST_WEAR_DISK: 8 VGSG
 SG_ ST_WEAR_DISK_CLAS_3 : 32|16@1+ (0.01,0) [0|0] "kWh"  DSC_DXC
 SG_ ST_WEAR_DISK_CLAS_2 : 16|16@1+ (0.01,0) [0|0] "kWh"  DSC_DXC
 SG_ ST_WEAR_DISK_CLAS_1 : 0|16@1+ (0.01,0) [0|0] "kWh"  DSC_DXC
 SG_ ST_WEAR_CHAIN : 48|16@1+ (0.1,0) [0|0] "kWh"  DSC_DXC

BO_ 884 RAD_TOLERANZ: 5 DSC_DXC
 SG_ TOMA_WHL_RRH : 24|8@1- (0.1,0) [0|0] "%"  SZL_LWS,LDM,EGS_SSG,DSC_DXC,AFS,ACC_Sensor
 SG_ TOMA_WHL_RLH : 16|8@1- (0.1,0) [0|0] "%"  SZL_LWS,LDM,EGS_SSG,DSC_DXC,AFS,ACC_Sensor
 SG_ TOMA_WHL_FRH : 8|8@1- (0.1,0) [0|0] "%"  SZL_LWS,LDM,EGS_SSG,DSC_DXC,AFS,ACC_Sensor
 SG_ TOMA_WHL_FLH : 0|8@1- (0.1,0) [0|0] "%"  SZL_LWS,LDM,EGS_SSG,DSC_DXC,AFS,ACC_Sensor
 SG_ ST_TOMA : 32|2@1+ (1,0) [0|0] ""  SZL_LWS,LDM,EGS_SSG,DSC_DXC,AFS,ACC_Sensor

BO_ 847 STAT_CT_HABR: 2 JBBF
 SG_ ST_CT_HABR : 0|2@1+ (1,0) [0|0] ""  Kombi,DSC_DXC,CAS

BO_ 846 NAV_SYS_INF: 8 CCC_MASK_RAD
 SG_ ST_VRS_SFTW_NAVI : 24|8@1+ (1,0) [0|0] "" Vector__XXX
 SG_ ST_VRS_MAP_NAVI_MANU : 45|3@1+ (1,0) [0|0] "" Vector__XXX
 SG_ ST_VRS_MAP_NAVI : 40|5@1+ (1,0) [0|0] "" Vector__XXX
 SG_ ST_VRS_HW_NAVI_MANU : 37|3@1+ (1,0) [0|0] "" Vector__XXX
 SG_ ST_VRS_HW_NAVI : 32|5@1+ (1,0) [0|0] "" Vector__XXX
 SG_ ST_OPET_NAVI : 0|24@1+ (10,0) [0|0] "ms" Vector__XXX
 SG_ ST_CNCD_NAVI : 48|16@1+ (1,0) [0|0] "" Vector__XXX

BO_ 844 NAV_GPS2: 8 CCC_MASK_RAD
 SG_ ST_V_HRZTL : 16|16@1- (0.036,0) [0|0] "km/h"  FRMFA
 SG_ ST_QUAL_PO : 40|12@1+ (1,0) [0|0] ""  FRMFA
 SG_ ST_QUAL_GPS : 56|8@1+ (0.5,0) [0|0] "%"  FRMFA
 SG_ ST_HG_NAVI : 0|16@1- (1,0) [0|0] "m"  FRMFA
 SG_ ST_HDG_HRZTL_ABSL : 32|8@1+ (1.5,0) [0|0] "°"  FRMFA

BO_ 842 NAV_GPS1: 8 CCC_MASK_RAD
 SG_ ST_LONG_NAVI : 0|32@1- (1.67638E-007,0) [0|0] "°"  FRMFA
 SG_ ST_LAT_NAVI : 32|32@1- (1.67638E-007,0) [0|0] "°"  FRMFA

BO_ 840 NAV_GRAPH_MATCH: 8 CCC_MASK_RAD
 SG_ ST_MTCH_UNIQ_PO : 24|8@1+ (0.5,0) [0|0] "%" Vector__XXX
 SG_ ST_MTCH_TSTMP : 40|16@1+ (1,0) [0|0] "ms" Vector__XXX
 SG_ ST_MTCH_QUAL : 56|8@1+ (0.5,0) [0|0] "%" Vector__XXX
 SG_ ST_MTCH_PO_REL : 8|8@1+ (1,0) [0|0] "m" Vector__XXX
 SG_ ST_MTCH_IDX_SEG : 16|8@1+ (1,0) [0|0] "" Vector__XXX
 SG_ ST_MTCH_HDG_HRZTL : 0|8@1+ (1.5,0) [0|0] "°" Vector__XXX
 SG_ ST_MTCH_ERR_XPO : 32|8@1+ (1,0) [0|0] "m" Vector__XXX

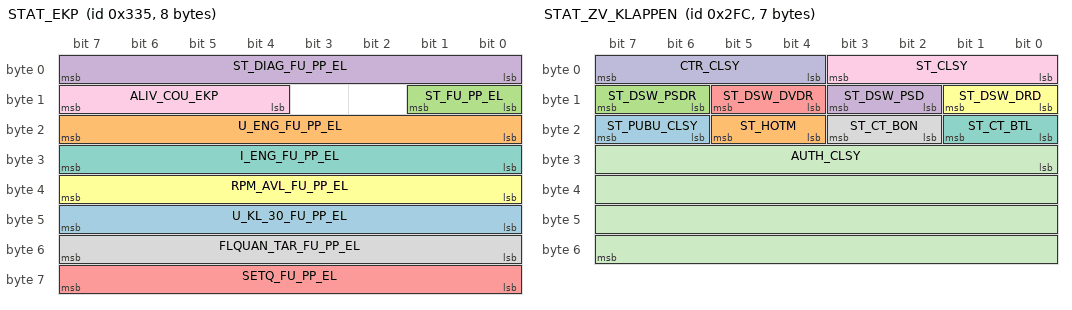
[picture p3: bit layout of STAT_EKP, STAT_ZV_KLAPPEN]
BO_ 821 STAT_EKP: 8 EKP
 SG_ U_KL_30_FU_PP_EL : 40|8@1+ (0.1,0) [0|0] "V"  DME1_DDE1
 SG_ U_ENG_FU_PP_EL : 16|8@1+ (0.1,0) [0|0] "V"  DME1_DDE1
 SG_ ST_FU_PP_EL : 8|2@1+ (1,0) [0|0] ""  DME1_DDE1
 SG_ ST_DIAG_FU_PP_EL : 0|8@1+ (1,0) [0|0] ""  DME1_DDE1
 SG_ SETQ_FU_PP_EL : 56|8@1+ (1,0) [0|0] "%"  DME1_DDE1
 SG_ RPM_AVL_FU_PP_EL : 32|8@1+ (50,0) [0|0] "1/min"  DME1_DDE1
 SG_ I_ENG_FU_PP_EL : 24|8@1+ (0.1,0) [0|0] "A"  DME1_DDE1
 SG_ FLQUAN_TAR_FU_PP_EL : 48|8@1+ (1,0) [0|0] "l/h"  DME1_DDE1
 SG_ ALIV_COU_EKP : 12|4@1+ (1,0) [0|0] ""  Kombi

BO_ 820 POWERMGMT_LADESPANNUNG: 3 dummy
 SG_ TEMP_BT : 16|8@1+ (1,-48) [0|0] "°C"  DME1_DDE1
 SG_ RPM_IDLG_SPEC : 8|2@1+ (1,0) [0|0] ""  DME1_DDE1
 SG_ CTR_GEN_U_TAR : 0|8@1+ (0.025,10.6) [0|0] "V"  DME1_DDE1

BO_ 818 ENGINE_RPM: 2 DME1_DDE1
 SG_ RPM_TEMP_DOM_2 : 8|8@1+ (50,0) [0|0] "1/min"  Kombi
 SG_ RPM_TEMP_DOM_1 : 0|8@1+ (50,0) [0|0] "1/min"  Kombi

BO_ 817 PRGG_CCTR: 5 CCC_MASK_RAD
 SG_ V_PRGG_CCTR_IDX_NO_3 : 28|12@1+ (0.1,0) [0|0] "km/h"  DME1_DDE1
 SG_ V_PRGG_CCTR_IDX_NO_2 : 16|12@1+ (0.1,0) [0|0] "km/h"  DME1_DDE1
 SG_ V_PRGG_CCTR_IDX_NO_1 : 4|12@1+ (0.1,0) [0|0] "km/h"  DME1_DDE1
 SG_ IDX_NO_PRGG_CCTR : 0|4@1+ (1,0) [0|0] ""  DME1_DDE1

BO_ 816 KILOMETERSTAND: 8 Kombi
 SG_ ST_FLLV_FUTA_SPAR : 48|2@1+ (1,0) [0|0] ""  DME1_DDE1,CCC_MASK_RAD
 SG_ ST_FLLV_COL_SPAR : 50|2@1+ (1,0) [0|0] ""  CCC_MASK_RAD
 SG_ RNG : 52|12@1+ (1,0) [0|0] "km"  IHx,DME1_DDE1,CCC_MASK_RAD
 SG_ MILE_KM : 0|24@1+ (1,0) [0|0] "km"  ZBE,VGSG,SM_FA,SM_BF,SHD,RDC,PGS,PDC,MRSZ,LDM,JBBF,IHx,FZD,FRMFA,FFP,EPS,EKP,EHC,EGS_SSG,DWA,DSC_DXC,DME1_DDE1,CVM_V,CID_V,CCC_MASK_RAD,CAS,AHM,AFS,ACC_Sensor
 SG_ FLLV_FUTA_RH : 40|8@1+ (0.5,0) [0|0] "l"  EKP,DME1_DDE1,CCC_MASK_RAD
 SG_ FLLV_FUTA_LH : 32|8@1+ (0.5,0) [0|0] "l"  EKP,DME1_DDE1,CCC_MASK_RAD
 SG_ FLLV_FUTA : 24|8@1+ (1,0) [0|0] "l"  PGS,IHx,DME1_DDE1,CCC_MASK_RAD,CAS

BO_ 813 ANZEIGE_HDC: 3 DSC_DXC
 SG_ V_TAR_HDC : 4|12@1+ (0.1,0) [0|0] "km/h"  Kombi
 SG_ CTR_DISP_V_TAR_HDC : 2|2@1+ (1,0) [0|0] ""  Kombi
 SG_ CTR_DISP_HDC : 0|2@1+ (1,0) [0|0] ""  Kombi,IHx

BO_ 806 DAEMPFERPROGRAMM: 2 dummy
 SG_ ST_EDCK_PRG_CFSP : 0|3@1+ (1,0) [0|0] "" Vector__XXX

BO_ 797 STAT_RPA: 2 DSC_DXC
 SG_ ST_TFIN : 0|3@1+ (1,0) [0|0] ""  LDM,CCC_MASK_RAD
 SG_ ST_BDOW_TYR_TFIN : 3|5@1+ (1,0) [0|0] ""  LDM,CCC_MASK_RAD
 SG_ RCPT_RPA_SET : 8|2@1+ (1,0) [0|0] ""  LDM,Kombi,CCC_MASK_RAD

BO_ 794 BEDIENUNG_HDC: 2 IHx
 SG_ OP_PUBU_HDC : 0|2@1+ (1,0) [0|0] ""  DSC_DXC

BO_ 793 BEDIENUNG_RDC: 2 Kombi
 SG_ OP_PUBU_TPCT : 0|2@1+ (1,0) [0|0] ""  RDC,DSC_DXC

BO_ 790 BEDIENUNG_DSC: 2 JBBF
 SG_ OP_PUBU_DSC : 0|2@1+ (1,0) [0|0] ""  DSC_DXC

BO_ 789 VEH_MOD: 2 dummy
 SG_ MOD_VEH : 8|4@1+ (1,0) [0|0] ""  LDM,Kombi,EGS_SSG,DSC_DXC,DME1_DDE1
 SG_ CHKSM_MOD_VEH : 0|4@1+ (1,0) [0|0] ""  LDM,EGS_SSG,DSC_DXC,DME1_DDE1
 SG_ ALIV_MOD_VEH : 4|4@1+ (1,0) [0|0] ""  LDM,EGS_SSG,DSC_DXC,DME1_DDE1

BO_ 785 REFUELING_VOLUME: 2 Kombi
 SG_ RFV : 0|12@1+ (0.1,0) [0|0] "l"  DME1_DDE1

BO_ 784 A_TEMP_RELATIVZEIT: 7 Kombi
 SG_ T_SEC_COU_REL : 8|32@1+ (1,0) [0|0] "s"  ZBE,VGSG,SM_FA,SM_BF,LDM,JBBF,IHx,FZD,FRMFA,FFP,EPS,EHC,EGS_SSG,DSC_DXC,DME1_DDE1,CID_V,AFS
 SG_ T_DAY_COU_ABSL : 40|16@1+ (1,0) [0|0] ""  JBBF,IHx,FRMFA,DSC_DXC,DME1_DDE1,CAS
 SG_ TEMP_EX : 0|8@1+ (0.5,-40) [0|0] "°C"  ZBE,VGSG,SM_FA,SM_BF,SHD,RDC,PGS,PDC,MRSZ,LDM,Kombi,JBBF,IHx,FZD,FRMFA,FFP,EPS,EKP,EGS_SSG,DWA,DSC_DXC,DME1_DDE1,CVM_V,CID_V,CCC_MASK_RAD,CAS,AFS,ACC_Sensor

BO_ 764 STAT_ZV_KLAPPEN: 7 CAS
 SG_ ST_PUBU_CLSY : 22|2@1+ (1,0) [0|0] ""  PGS
 SG_ ST_HOTM : 20|2@1+ (1,0) [0|0] ""  JBBF,DWA
 SG_ ST_DSW_PSDR : 14|2@1+ (1,0) [0|0] ""  SM_FA,SM_BF,Kombi,JBBF,FRMFA,EHC,DWA
 SG_ ST_DSW_PSD : 10|2@1+ (1,0) [0|0] ""  SM_FA,SM_BF,Kombi,JBBF,FRMFA,EHC,DWA
 SG_ ST_DSW_DVDR : 12|2@1+ (1,0) [0|0] ""  SM_FA,SM_BF,Kombi,JBBF,FRMFA,EHC,DWA
 SG_ ST_DSW_DRD : 8|2@1+ (1,0) [0|0] ""  SM_FA,SM_BF,PGS,Kombi,JBBF,FRMFA,EHC,EGS_SSG,DWA
 SG_ ST_CT_BTL : 16|2@1+ (1,0) [0|0] ""  Kombi,JBBF,IHx,FRMFA,EHC,DWA,CVM_V
 SG_ ST_CT_BON : 18|2@1+ (1,0) [0|0] ""  FRMFA,DWA
 SG_ ST_CLSY : 0|4@1+ (1,0) [0|0] ""  SHD,RDC,Kombi,JBBF,IHx,FZD,FRMFA,EHC,DWA,CCC_MASK_RAD,CAS
 SG_ CTR_CLSY : 4|4@1+ (1,0) [0|0] ""  Kombi,FRMFA,DWA
 SG_ AUTH_CLSY : 24|32@1+ (1,0) [0|0] ""  DWA

BO_ 762 STAT_SITZBELEGUNG_GURT: 5 dummy
 SG_ SW_BLTB_DR : 0|2@1+ (1,0) [0|0] ""  DME1_DDE1
 SG_ CLAS_WGH_SEAT_RRH : 34|3@1+ (1,0) [0|0] ""  CAS
 SG_ CLAS_WGH_SEAT_RLH : 18|3@1+ (1,0) [0|0] ""  CAS
 SG_ CLAS_WGH_SEAT_PS : 10|3@1+ (1,0) [0|0] ""  SM_BF,JBBF,CCC_MASK_RAD,CAS
 SG_ CLAS_WGH_SEAT_DR : 2|3@1+ (1,0) [0|0] ""  SM_FA,LDM,JBBF,DME1_DDE1,CCC_MASK_RAD,CAS

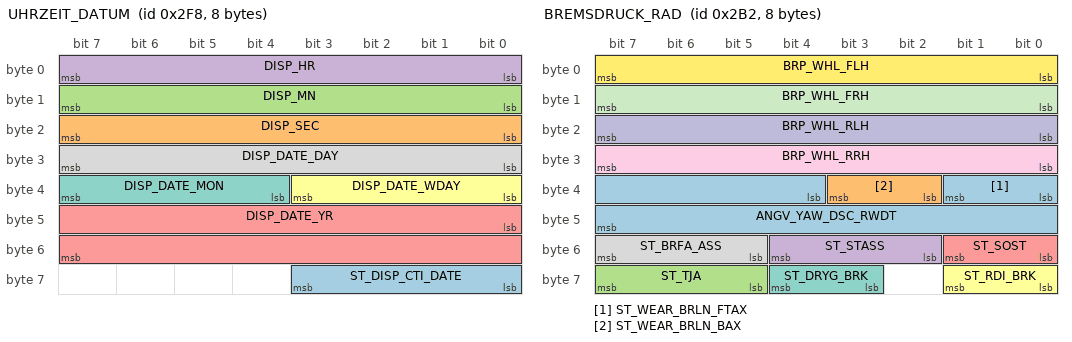
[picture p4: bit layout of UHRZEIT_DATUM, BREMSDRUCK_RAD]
BO_ 760 UHRZEIT_DATUM: 8 Kombi
 SG_ ST_DISP_CTI_DATE : 56|4@1+ (1,0) [0|0] ""  SM_FA,SM_BF,MRSZ,DME1_DDE1,CCC_MASK_RAD
 SG_ DISP_SEC : 16|8@1+ (1,0) [0|0] "s"  SM_FA,SM_BF,MRSZ,DME1_DDE1,CCC_MASK_RAD
 SG_ DISP_MN : 8|8@1+ (1,0) [0|0] "min"  SM_FA,SM_BF,PGS,MRSZ,DWA,DME1_DDE1,CCC_MASK_RAD,CAS
 SG_ DISP_HR : 0|8@1+ (1,0) [0|0] "h"  SM_FA,SM_BF,PGS,MRSZ,DWA,DME1_DDE1,CCC_MASK_RAD,CAS
 SG_ DISP_DATE_YR : 40|16@1+ (1,0) [0|0] ""  SM_FA,SM_BF,PGS,MRSZ,JBBF,DWA,DSC_DXC,DME1_DDE1,CCC_MASK_RAD,CAS
 SG_ DISP_DATE_WDAY : 32|4@1+ (1,0) [0|0] ""  SM_FA,SM_BF,MRSZ,DME1_DDE1,CCC_MASK_RAD
 SG_ DISP_DATE_MON : 36|4@1+ (1,0) [0|0] ""  SM_FA,SM_BF,PGS,MRSZ,JBBF,DWA,DSC_DXC,DME1_DDE1,CCC_MASK_RAD,CAS
 SG_ DISP_DATE_DAY : 24|8@1+ (1,0) [0|0] ""  SM_FA,SM_BF,PGS,MRSZ,JBBF,DWA,DSC_DXC,DME1_DDE1,CCC_MASK_RAD,CAS

BO_ 758 CTR_LICHT: 2 FRMFA
 SG_ CTR_ITLI : 2|2@1+ (1,0) [0|0] ""  FZD,FRMFA,DME1_DDE1
 SG_ CTR_ILUM_PFIE : 0|2@1+ (1,0) [0|0] ""  FRMFA
 SG_ CTR_DIM_ITLI : 10|2@1+ (1,0) [0|0] ""  FZD
 SG_ CTR_DIM_ILUM_PFIE : 8|2@1+ (1,0) [0|0] ""  FRMFA

BO_ 740 STAT_ANHAENGER: 2 AHM
 SG_ ST_TRAI : 0|2@1+ (1,0) [0|0] ""  PDC,LDM,Kombi,FRMFA,EGS_SSG,DSC_DXC,DME1_DDE1,AFS
 SG_ ST_DI_DF_TRAI : 2|3@1+ (1,0) [0|0] ""  FRMFA

BO_ 690 BREMSDRUCK_RAD: 8 DSC_DXC
 SG_ ST_WEAR_BRLN_FTAX : 32|2@1+ (1,0) [0|0] ""  DSC_DXC
 SG_ ST_WEAR_BRLN_BAX : 34|2@1+ (1,0) [0|0] ""  DSC_DXC
 SG_ ST_TJA : 61|3@1+ (1,0) [0|0] ""  LDM,EGS_SSG,DME1_DDE1
 SG_ ST_STASS : 50|3@1+ (1,0) [0|0] ""  LDM,EGS_SSG,DME1_DDE1
 SG_ ST_SOST : 48|2@1+ (1,0) [0|0] ""  LDM,EGS_SSG,DME1_DDE1
 SG_ ST_RDI_BRK : 56|2@1+ (1,0) [0|0] ""  LDM
 SG_ ST_DRYG_BRK : 59|2@1+ (1,0) [0|0] ""  LDM
 SG_ ST_BRFA_ASS : 53|3@1+ (1,0) [0|0] ""  LDM,EGS_SSG,DME1_DDE1
 SG_ BRP_WHL_RRH : 24|8@1+ (1,0) [0|0] "bar"  DSC_DXC,ACC_Sensor
 SG_ BRP_WHL_RLH : 16|8@1+ (1,0) [0|0] "bar"  DSC_DXC,ACC_Sensor
 SG_ BRP_WHL_FRH : 8|8@1+ (1,0) [0|0] "bar"  DSC_DXC,ACC_Sensor
 SG_ BRP_WHL_FLH : 0|8@1+ (1,0) [0|0] "bar"  DSC_DXC,ACC_Sensor
 SG_ ANGV_YAW_DSC_RWDT : 36|12@1- (0.2,0) [0|0] "°/s"  DSC_DXC,ACC_Sensor

BO_ 678 BEDIENUNG_WISCHER: 2 SZL_LWS
 SG_ OP_WISW : 0|8@1+ (1,0) [0|0] ""  JBBF,FZD,FRMFA,CCC_MASK_RAD
 SG_ OP_WIPO : 8|3@1+ (1,0) [0|0] ""  JBBF,FZD

BO_ 634 NAV_GRAPH_SYNC: 8 CCC_MASK_RAD
 SG_ ST_QUAN_PCKGS : 0|8@1+ (1,0) [0|0] "" Vector__XXX
 SG_ MOD_TRNSM_NAVGRPH_SYNC : 32|8@1+ (1,0) [0|0] "" Vector__XXX
 SG_ IDX_SEG_DEL_NAVGRPH : 40|8@1+ (1,0) [0|0] "" Vector__XXX
 SG_ CTR_DEL_NAVGRPH : 48|3@1+ (1,0) [0|0] "" Vector__XXX
 SG_ CRC16_NAVGRPH_SYNC : 16|16@1+ (1,0) [0|0] "" Vector__XXX
 SG_ COU_NAVGRPH_SYNC : 8|8@1+ (1,0) [0|0] "" Vector__XXX

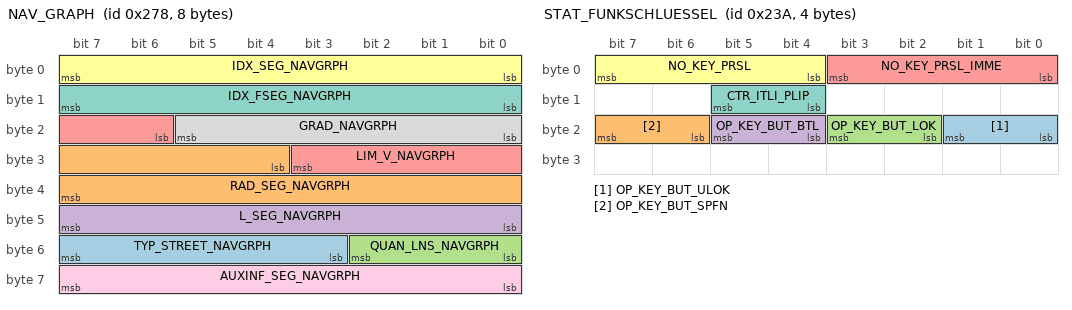
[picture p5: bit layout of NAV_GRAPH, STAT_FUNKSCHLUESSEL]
BO_ 632 NAV_GRAPH: 8 CCC_MASK_RAD
 SG_ TYP_STREET_NAVGRPH : 51|5@1+ (1,0) [0|0] "" Vector__XXX
 SG_ RAD_SEG_NAVGRPH : 28|12@1+ (1,0) [0|0] "" Vector__XXX
 SG_ QUAN_LNS_NAVGRPH : 48|3@1+ (1,0) [0|0] "" Vector__XXX
 SG_ L_SEG_NAVGRPH : 40|8@1+ (1,0) [0|0] "m" Vector__XXX
 SG_ LIM_V_NAVGRPH : 22|6@1+ (1,0) [0|0] "" Vector__XXX
 SG_ IDX_SEG_NAVGRPH : 0|8@1+ (1,0) [0|0] "" Vector__XXX
 SG_ IDX_FSEG_NAVGRPH : 8|8@1+ (1,0) [0|0] "" Vector__XXX
 SG_ GRAD_NAVGRPH : 16|6@1+ (1,0) [0|0] "" Vector__XXX
 SG_ AUXINF_SEG_NAVGRPH : 56|8@1+ (1,0) [0|0] "" Vector__XXX

BO_ 594 STAT_WISCHER: 2 JBBF
 SG_ ST_WI : 4|2@1+ (1,0) [0|0] ""  FZD,DME1_DDE1
 SG_ PO_WIBL : 0|4@1+ (1,0) [0|0] ""  IHx,FZD,DME1_DDE1

BO_ 586 STAT_PDC: 2 PDC
 SG_ ST_PDC_ERR : 2|2@1+ (1,0) [0|0] ""  IHx,CCC_MASK_RAD
 SG_ ST_PDC : 0|2@1+ (1,0) [0|0] ""  IHx,CCC_MASK_RAD
 SG_ ST_ID_FN_ACTVN_PDC : 4|4@1+ (1,0) [0|0] "" Vector__XXX

BO_ 570 STAT_FUNKSCHLUESSEL: 4 CAS
 SG_ OP_KEY_BUT_ULOK : 16|2@1+ (1,0) [0|0] ""  SM_FA,FRMFA,DWA
 SG_ OP_KEY_BUT_SPFN : 22|2@1+ (1,0) [0|0] ""  FRMFA,DWA,CCC_MASK_RAD
 SG_ OP_KEY_BUT_LOK : 18|2@1+ (1,0) [0|0] ""  SM_FA,FRMFA,DWA
 SG_ OP_KEY_BUT_BTL : 20|2@1+ (1,0) [0|0] ""  JBBF,DWA
 SG_ NO_KEY_PRSL_IMME : 0|4@1+ (1,0) [0|0] ""  SM_FA,Kombi,IHx,FZD,FRMFA,DWA,CID_V,CCC_MASK_RAD
 SG_ NO_KEY_PRSL : 4|4@1+ (1,0) [0|0] ""  SM_FA,Kombi,IHx,FZD,FRMFA,DWA,CID_V,CCC_MASK_RAD
 SG_ CTR_ITLI_PLIP : 12|2@1+ (1,0) [0|0] ""  FRMFA

BO_ 550 WISCHERGESCHWINDIGKEIT: 5 FZD
 SG_ V_WI : 24|4@1+ (2,33) [0|0] "Wischhübe/min"  JBBF,DSC_DXC,CCC_MASK_RAD
 SG_ ST_RNSE : 28|4@1+ (1,0) [0|0] ""  JBBF,DSC_DXC
 SG_ INT_RN : 0|8@1+ (0.5,0) [0|0] "%"  SHD,IHx,FZD,DSC_DXC,CCC_MASK_RAD
 SG_ INTM_T : 8|16@1+ (100,0) [0|0] "ms"  JBBF,DSC_DXC
 SG_ CTR_WI_SNS : 34|2@1+ (1,0) [0|0] ""  DSC_DXC

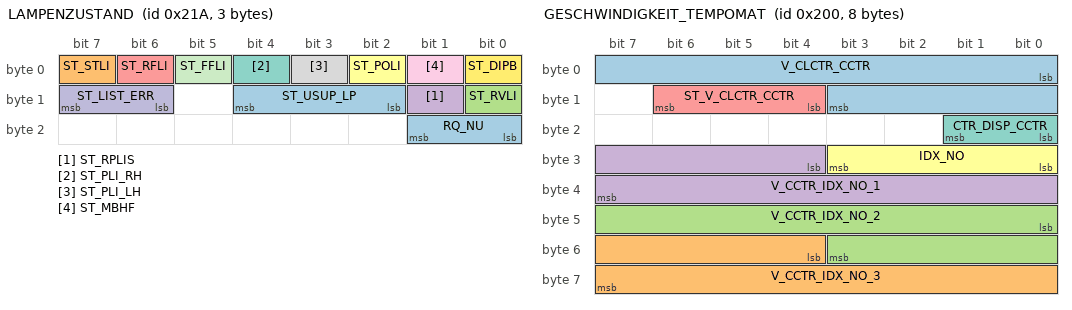
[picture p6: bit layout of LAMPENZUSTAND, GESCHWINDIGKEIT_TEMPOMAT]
BO_ 538 LAMPENZUSTAND: 3 FRMFA
 SG_ ST_USUP_LP : 10|3@1+ (1,0) [0|0] "" Vector__XXX
 SG_ ST_STLI : 7|1@1+ (1,0) [0|0] "" Vector__XXX
 SG_ ST_RVLI : 8|1@1+ (1,0) [0|0] ""  AHM
 SG_ ST_RPLIS : 9|1@1+ (1,0) [0|0] ""  AHM
 SG_ ST_RFLI : 6|1@1+ (1,0) [0|0] ""  Kombi,CCC_MASK_RAD,AHM
 SG_ ST_POLI : 2|1@1+ (1,0) [0|0] ""  Kombi,JBBF,CCC_MASK_RAD,AHM
 SG_ ST_PLI_RH : 4|1@1+ (1,0) [0|0] ""  AHM
 SG_ ST_PLI_LH : 3|1@1+ (1,0) [0|0] ""  AHM
 SG_ ST_MBHF : 1|1@1+ (1,0) [0|0] ""  Kombi,FRMFA,CCC_MASK_RAD
 SG_ ST_LIST_ERR : 14|2@1+ (1,0) [0|0] ""  CCC_MASK_RAD
 SG_ ST_FFLI : 5|1@1+ (1,0) [0|0] ""  Kombi,FRMFA,CCC_MASK_RAD
 SG_ ST_DIPB : 0|1@1+ (1,0) [0|0] ""  FRMFA,DME1_DDE1,CID_V,CCC_MASK_RAD
 SG_ RQ_NU : 16|2@1+ (1,0) [0|0] "" Vector__XXX

BO_ 512 GESCHWINDIGKEIT_TEMPOMAT: 8 DME1_DDE1
 SG_ V_CLCTR_CCTR : 0|12@1+ (0.1,0) [0|0] "km/h"  Kombi,EGS_SSG,CCC_MASK_RAD
 SG_ V_CCTR_IDX_NO_3 : 52|12@1+ (0.1,0) [0|0] "km/h"  Kombi,CCC_MASK_RAD
 SG_ V_CCTR_IDX_NO_2 : 40|12@1+ (0.1,0) [0|0] "km/h"  Kombi,CCC_MASK_RAD
 SG_ V_CCTR_IDX_NO_1 : 28|12@1+ (0.1,0) [0|0] "km/h"  Kombi,CCC_MASK_RAD
 SG_ ST_V_CLCTR_CCTR : 12|3@1+ (1,0) [0|0] ""  Kombi,EGS_SSG,CCC_MASK_RAD
 SG_ IDX_NO : 24|4@1+ (1,0) [0|0] ""  Kombi,CCC_MASK_RAD
 SG_ CTR_DISP_CCTR : 16|2@1+ (1,0) [0|0] ""  Kombi,CCC_MASK_RAD

BO_ 508 STAT_AFS: 2 AFS
 SG_ ST_FN_AFS : 4|4@1+ (1,0) [0|0] ""  DSC_DXC,AFS_RP
 SG_ ALIV_COU_AFS : 0|4@1+ (1,0) [0|0] ""  Kombi,DSC_DXC

BO_ 507 STAT_EPS: 2 EPS
 SG_ ALIV_COU_EPS : 0|4@1+ (1,0) [0|0] ""  Kombi

BO_ 502 BLINKEN: 2 FRMFA
 SG_ ST_IDC_STOP : 8|2@1+ (1,0) [0|0] ""  Kombi,AHM
 SG_ ST_IDC_KI : 10|2@1+ (1,0) [0|0] ""  Kombi
 SG_ ST_IDC : 4|3@1+ (1,0) [0|0] ""  LDM,Kombi,CCC_MASK_RAD,AHM
 SG_ CCLK_IDC : 0|4@1+ (1,0) [0|0] ""  Kombi,AHM

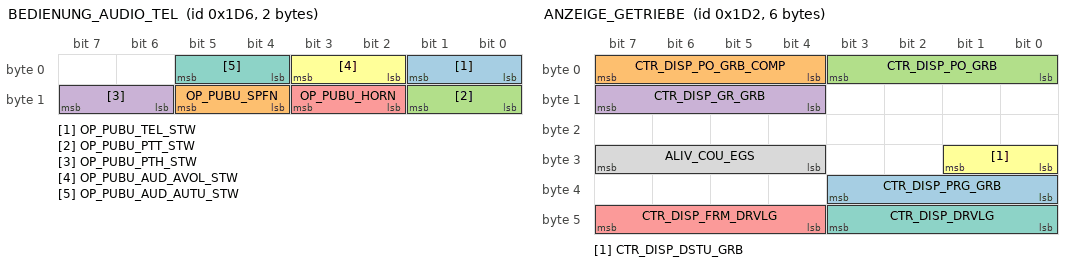
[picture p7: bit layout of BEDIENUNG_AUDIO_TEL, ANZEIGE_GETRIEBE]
BO_ 470 BEDIENUNG_AUDIO_TEL: 2 SZL_LWS
 SG_ OP_PUBU_TEL_STW : 0|2@1+ (1,0) [0|0] ""  Diagnosetool_PT_CAN,Diagnosetool_K_CAN_System,CCC_MASK_RAD
 SG_ OP_PUBU_SPFN : 12|2@1+ (1,0) [0|0] ""  Diagnosetool_PT_CAN,Diagnosetool_K_CAN_System,CCC_MASK_RAD
 SG_ OP_PUBU_PTT_STW : 8|2@1+ (1,0) [0|0] ""  Diagnosetool_PT_CAN,Diagnosetool_K_CAN_System,CCC_MASK_RAD
 SG_ OP_PUBU_PTH_STW : 14|2@1+ (1,0) [0|0] ""  Diagnosetool_PT_CAN,Diagnosetool_K_CAN_System,CCC_MASK_RAD
 SG_ OP_PUBU_HORN : 10|2@1+ (1,0) [0|0] ""  Diagnosetool_PT_CAN,Diagnosetool_K_CAN_System
 SG_ OP_PUBU_AUD_AVOL_STW : 2|2@1+ (1,0) [0|0] ""  Diagnosetool_PT_CAN,Diagnosetool_K_CAN_System,CCC_MASK_RAD
 SG_ OP_PUBU_AUD_AUTU_STW : 4|2@1+ (1,0) [0|0] ""  Diagnosetool_PT_CAN,Diagnosetool_K_CAN_System,CCC_MASK_RAD

BO_ 466 ANZEIGE_GETRIEBE: 6 EGS_SSG
 SG_ CTR_DISP_PRG_GRB : 32|4@1+ (1,0) [0|0] ""  Kombi
 SG_ CTR_DISP_PO_GRB_COMP : 4|4@1+ (1,0) [0|0] ""  Kombi
 SG_ CTR_DISP_PO_GRB : 0|4@1+ (1,0) [0|0] ""  Kombi
 SG_ CTR_DISP_GR_GRB : 12|4@1+ (1,0) [0|0] ""  Kombi
 SG_ CTR_DISP_FRM_DRVLG : 44|4@1+ (1,0) [0|0] "" Vector__XXX
 SG_ CTR_DISP_DSTU_GRB : 24|2@1+ (1,0) [0|0] ""  LDM
 SG_ CTR_DISP_DRVLG : 40|4@1+ (1,0) [0|0] "" Vector__XXX
 SG_ ALIV_COU_EGS : 28|4@1+ (1,0) [0|0] ""  Kombi

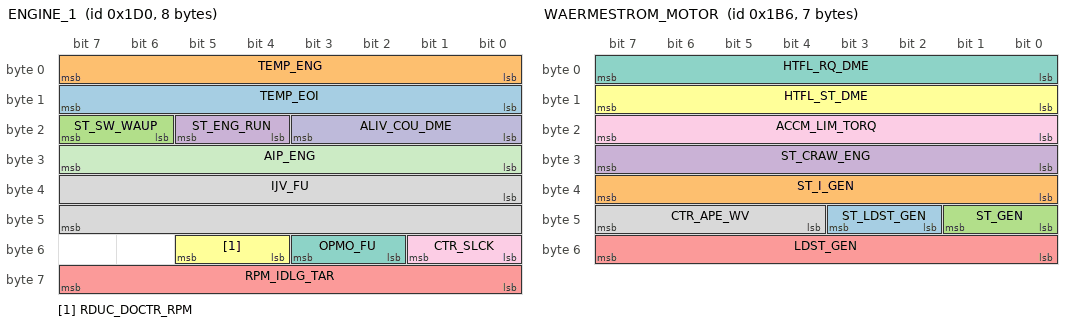
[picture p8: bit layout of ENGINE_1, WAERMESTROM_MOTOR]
BO_ 464 ENGINE_1: 8 DME1_DDE1
 SG_ TEMP_EOI : 8|8@1+ (1,-48) [0|0] "°C"  Kombi,EGS_SSG
 SG_ TEMP_ENG : 0|8@1+ (1,-48) [0|0] "°C"  PGS,Kombi,IHx,EGS_SSG,CAS
 SG_ ST_SW_WAUP : 22|2@1+ (1,0) [0|0] ""  EGS_SSG
 SG_ ST_ENG_RUN : 20|2@1+ (1,0) [0|0] ""  RDC,Kombi,JBBF,IHx,FRMFA,EPS,EHC,DWA,DME1_DDE1,CCC_MASK_RAD,CAS,AFS
 SG_ RPM_IDLG_TAR : 56|8@1+ (5,0) [0|0] "1/min"  EGS_SSG
 SG_ RDUC_DOCTR_RPM : 52|2@1+ (1,0) [0|0] ""  EGS_SSG
 SG_ OPMO_FU : 50|2@1+ (1,0) [0|0] "" Vector__XXX
 SG_ IJV_FU : 32|16@1+ (1,0) [0|0] "µl"  Kombi
 SG_ CTR_SLCK : 48|2@1+ (1,0) [0|0] ""  EGS_SSG
 SG_ ALIV_COU_DME : 16|4@1+ (1,0) [0|0] ""  Kombi,AFS
 SG_ AIP_ENG : 24|8@1+ (2,598) [0|0] "hPa"  EGS_SSG

BO_ 438 WAERMESTROM_MOTOR: 7 DME1_DDE1
 SG_ ST_LDST_GEN : 42|2@1+ (1,0) [0|0] ""  IHx
 SG_ ST_I_GEN : 32|8@1+ (1,0) [0|0] "A"  IHx
 SG_ ST_GEN : 40|2@1+ (1,0) [0|0] ""  IHx
 SG_ ST_CRAW_ENG : 24|8@1+ (1,0) [0|0] "A" Vector__XXX
 SG_ LDST_GEN : 48|8@1+ (1,0) [0|0] "%"  IHx
 SG_ HTFL_ST_DME : 8|8@1+ (1,0) [0|0] ""  IHx
 SG_ HTFL_RQ_DME : 0|8@1+ (1,0) [0|0] ""  IHx
 SG_ CTR_APE_WV : 44|4@1+ (10,0) [0|0] "%"  JBBF,IHx
 SG_ ACCM_LIM_TORQ : 16|8@1+ (0.5,0) [0|0] "Nm"  IHx

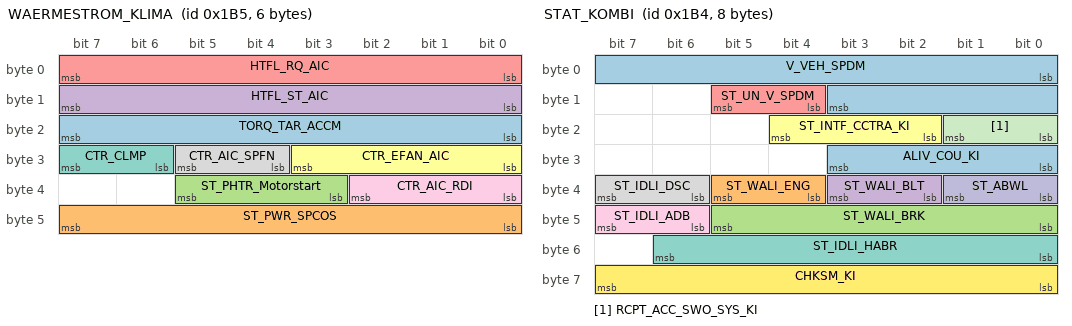
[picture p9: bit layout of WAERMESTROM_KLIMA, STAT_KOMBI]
BO_ 437 WAERMESTROM_KLIMA: 6 IHx
 SG_ TORQ_TAR_ACCM : 16|8@1+ (0.5,0) [0|0] "Nm"  DME1_DDE1
 SG_ ST_PWR_SPCOS : 40|8@1+ (0.5,0) [0|0] "%"  DME1_DDE1
 SG_ ST_PHTR_Motorstart : 35|3@1+ (1,0) [0|0] ""  DME1_DDE1
 SG_ HTFL_ST_AIC : 8|8@1+ (1,0) [0|0] ""  DME1_DDE1
 SG_ HTFL_RQ_AIC : 0|8@1+ (0.5,0) [0|0] "%"  DME1_DDE1
 SG_ CTR_EFAN_AIC : 24|4@1+ (1,0) [0|0] ""  DME1_DDE1
 SG_ CTR_CLMP : 30|2@1+ (1,0) [0|0] ""  DME1_DDE1
 SG_ CTR_AIC_SPFN : 28|2@1+ (1,0) [0|0] ""  DME1_DDE1
 SG_ CTR_AIC_RDI : 32|3@1+ (1,0) [0|0] ""  DME1_DDE1

BO_ 436 STAT_KOMBI: 8 Kombi
 SG_ V_VEH_SPDM : 0|12@1+ (0.1,0) [0|0] "km/h"  LDM,EGS_SSG,DME1_DDE1
 SG_ ST_WALI_ENG : 36|2@1+ (1,0) [0|0] ""  DME1_DDE1
 SG_ ST_WALI_BRK : 40|6@1+ (1,0) [0|0] "" Vector__XXX
 SG_ ST_WALI_BLT : 34|2@1+ (1,0) [0|0] "" Vector__XXX
 SG_ ST_UN_V_SPDM : 12|2@1+ (1,0) [0|0] ""  LDM,DME1_DDE1,CCC_MASK_RAD
 SG_ ST_INTF_CCTRA_KI : 18|3@1+ (1,0) [0|0] ""  LDM,DME1_DDE1
 SG_ ST_IDLI_HABR : 48|7@1+ (1,0) [0|0] ""  LDM,EGS_SSG,DSC_DXC
 SG_ ST_IDLI_DSC : 38|2@1+ (1,0) [0|0] "" Vector__XXX
 SG_ ST_IDLI_ADB : 46|2@1+ (1,0) [0|0] "" Vector__XXX
 SG_ ST_ABWL : 32|2@1+ (1,0) [0|0] ""  MRSZ
 SG_ RCPT_ACC_SWO_SYS_KI : 16|2@1+ (1,0) [0|0] ""  LDM
 SG_ CHKSM_KI : 56|8@1+ (1,0) [0|0] ""  LDM,DSC_DXC
 SG_ ALIV_COU_KI : 24|4@1+ (1,0) [0|0] ""  LDM,DSC_DXC,DME1_DDE1

BO_ 431 ST_HDC: 2 DSC_DXC
 SG_ ST_HDC_FN : 0|4@1+ (1,0) [0|0] ""  LDM,EGS_SSG
 SG_ RQ_SHAF_HDC : 4|3@1+ (1,0) [0|0] ""  LDM,EGS_SSG

BO_ 428 STAT_ARS: 4 dummy
 SG_ TORQ_TAR_ARS : 16|8@1+ (0.5,0) [0|0] "Nm"  DME1_DDE1
 SG_ TORQ_AVL_ARS : 24|8@1+ (0.5,0) [0|0] "Nm"  DME1_DDE1
 SG_ ST_CLCTR_ARS : 12|2@1+ (1,0) [0|0] ""  DME1_DDE1
 SG_ ST_ARS : 0|8@1+ (1,0) [0|0] ""  DSC_DXC
 SG_ ALIV_COU_ARS : 8|4@1+ (1,0) [0|0] ""  DSC_DXC,DME1_DDE1

BO_ 422 WEGSTRECKE: 8 DSC_DXC
 SG_ MILE_INTM_TOMSRM : 48|12@1+ (0.25,0) [0|0] "ms"  Kombi,CCC_MASK_RAD
 SG_ MILE_FRH : 32|16@1+ (1,0) [0|0] ""  CCC_MASK_RAD
 SG_ MILE_FLH : 16|16@1+ (1,0) [0|0] ""  CCC_MASK_RAD
 SG_ MILE : 0|16@1+ (1,0) [0|0] ""  PDC,Kombi,DSC_DXC,CCC_MASK_RAD

BO_ 419 RWDT_LN_ACLN: 2 EGS_SSG
 SG_ RWDT_ACLN_VEH_LN : 0|12@1- (0.00625,0) [0|0] "g" Vector__XXX

BO_ 418 GETRIEBEDATEN_2: 4 EGS_SSG
 SG_ ST_STCLT : 24|3@1+ (1,0) [0|0] ""  DME1_DDE1
 SG_ RQ_BST_RPM_IDLG : 16|8@1+ (8,0) [0|0] "1/min"  DME1_DDE1
 SG_ RPM_GRB_TURB : 0|16@1+ (0.125,0) [0|0] "1/min"  DSC_DXC,DME1_DDE1

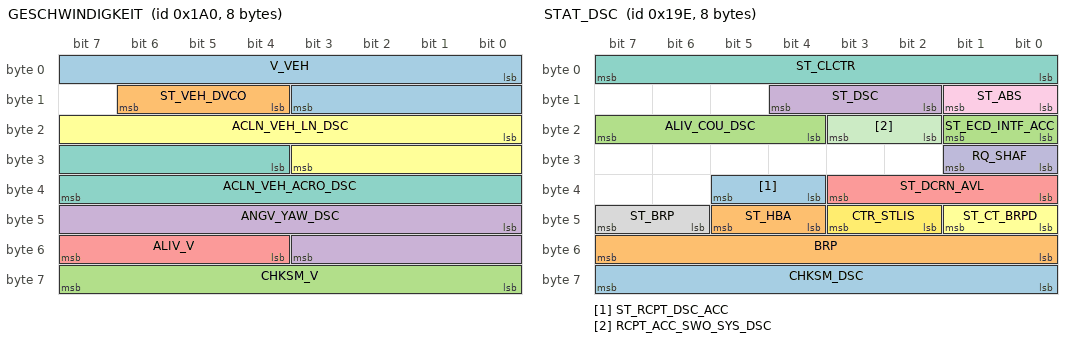
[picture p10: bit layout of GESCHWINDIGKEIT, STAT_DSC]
BO_ 416 GESCHWINDIGKEIT: 8 DSC_DXC
 SG_ V_VEH : 0|12@1+ (0.1,0) [0|0] "km/h"  SM_FA,SM_BF,SHD,RDC,PGS,PDC,MRSZ,LDM,Kombi,JBBF,IHx,FZD,FRMFA_ALC,FRMFA,EPS,EKP,EHC,DSC_DXC,DME1_DDE1,CVM_V,CCC_MASK_RAD,CAS,ACC_Sensor
 SG_ ST_VEH_DVCO : 12|3@1+ (1,0) [0|0] ""  SHD,PDC,MRSZ,LDM,Kombi,JBBF,FZD,FRMFA,EKP,EGS_SSG,DSC_DXC,DME1_DDE1,CVM_V,CCC_MASK_RAD,CAS,AFS,ACC_Sensor
 SG_ CHKSM_V : 56|8@1+ (1,0) [0|0] ""  LDM,DSC_DXC,CCC_MASK_RAD,AFS,ACC_Sensor
 SG_ ANGV_YAW_DSC : 40|12@1- (0.05,0) [0|0] "°/s"  LDM,FRMFA_ALC,EGS_SSG,DSC_DXC,CCC_MASK_RAD,ACC_Sensor
 SG_ ALIV_V : 52|4@1+ (1,0) [0|0] ""  LDM,DSC_DXC,CCC_MASK_RAD,ACC_Sensor
 SG_ ACLN_VEH_LN_DSC : 16|12@1- (0.025,0) [0|0] "m/s²"  LDM,FRMFA,EGS_SSG,DSC_DXC,DME1_DDE1,CCC_MASK_RAD,ACC_Sensor
 SG_ ACLN_VEH_ACRO_DSC : 28|12@1- (0.025,0) [0|0] "m/s²"  SM_FA,SM_BF,LDM,EHC,EGS_SSG,DSC_DXC,DME1_DDE1,CCC_MASK_RAD,ACC_Sensor

BO_ 414 STAT_DSC: 8 DSC_DXC
 SG_ ST_RCPT_DSC_ACC : 36|2@1+ (1,0) [0|0] ""  LDM,DSC_DXC,ACC_Sensor
 SG_ ST_HBA : 44|2@1+ (1,0) [0|0] "" Vector__XXX
 SG_ ST_ECD_INTF_ACC : 16|2@1+ (1,0) [0|0] ""  LDM,ACC_Sensor
 SG_ ST_DSC : 10|3@1+ (1,0) [0|0] ""  LDM,EGS_SSG,DSC_DXC,DME1_DDE1,AFS,ACC_Sensor
 SG_ ST_DCRN_AVL : 32|4@1+ (1,0) [0|0] ""  LDM,DME1_DDE1,ACC_Sensor
 SG_ ST_CT_BRPD : 40|2@1+ (1,0) [0|0] ""  LDM,FRMFA,DSC_DXC,CCC_MASK_RAD,CAS,AHM,AFS,ACC_Sensor
 SG_ ST_CLCTR : 0|8@1+ (1,0) [0|0] ""  LDM,FRMFA,EGS_SSG,DME1_DDE1,CCC_MASK_RAD,AFS,ACC_Sensor
 SG_ ST_BRP : 46|2@1+ (1,0) [0|0] ""  LDM,DSC_DXC,DME1_DDE1,CAS,AFS,ACC_Sensor
 SG_ ST_ABS : 8|2@1+ (1,0) [0|0] ""  DSC_DXC,AFS
 SG_ RQ_SHAF : 24|2@1+ (1,0) [0|0] ""  EGS_SSG
 SG_ RCPT_ACC_SWO_SYS_DSC : 18|2@1+ (1,0) [0|0] ""  DSC_DXC,ACC_Sensor
 SG_ CTR_STLIS : 42|2@1+ (1,0) [0|0] ""  FRMFA
 SG_ CHKSM_DSC : 56|8@1+ (1,0) [0|0] ""  LDM,DSC_DXC,ACC_Sensor
 SG_ BRP : 48|8@1+ (1,0) [0|0] "bar"  EGS_SSG,DSC_DXC,DME1_DDE1,CCC_MASK_RAD,CAS,AFS
 SG_ ALIV_COU_DSC : 20|4@1+ (1,0) [0|0] ""  LDM,Kombi,ACC_Sensor

BO_ 412 CHALLENGE_DME1_CAS: 8 dummy
 SG_ TYP_CHRP_DME1 : 59|3@1+ (1,0) [0|0] ""  CAS
 SG_ ST_ENB_ENG_STA_DME1 : 56|3@1+ (1,0) [0|0] ""  CAS
 SG_ ST_CHRP_DME1C : 48|4@1+ (1,0) [0|0] ""  CAS
 SG_ CTR_CHRP_DME1C : 52|2@1+ (1,0) [0|0] ""  CAS
 SG_ CHRP_DME1C : 0|48@1+ (1,0) [0|0] ""  CAS

BO_ 404 BEDIENUNG_TEMPOMAT: 4 SZL_LWS
 SG_ OP_PUBU_CCTR_ACC : 16|8@1+ (1,0) [0|0] ""  LDM,DME1_DDE1
 SG_ OP_MOD_CHO_CCCA : 26|2@1+ (1,0) [0|0] ""  LDM
 SG_ OP_GAPC_ACC : 24|2@1+ (1,0) [0|0] ""  LDM
 SG_ CHKSM_CCTR : 0|8@1+ (1,0) [0|0] ""  LDM,DME1_DDE1
 SG_ ALIV_CCTR : 8|4@1+ (1,0) [0|0] ""  LDM,DME1_DDE1

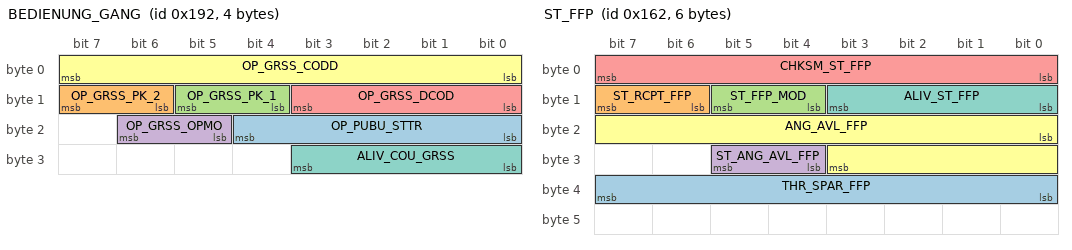
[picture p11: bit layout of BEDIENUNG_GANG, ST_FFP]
BO_ 402 BEDIENUNG_GANG: 4 dummy
 SG_ OP_PUBU_STTR : 16|5@1+ (1,0) [0|0] ""  EGS_SSG
 SG_ OP_GRSS_PK_2 : 14|2@1+ (1,0) [0|0] "" Vector__XXX
 SG_ OP_GRSS_PK_1 : 12|2@1+ (1,0) [0|0] "" Vector__XXX
 SG_ OP_GRSS_OPMO : 21|2@1+ (1,0) [0|0] ""  EGS_SSG
 SG_ OP_GRSS_DCOD : 8|4@1+ (1,0) [0|0] ""  EGS_SSG
 SG_ OP_GRSS_CODD : 0|8@1+ (1,0) [0|0] ""  EGS_SSG
 SG_ ALIV_COU_GRSS : 24|4@1+ (1,0) [0|0] ""  EGS_SSG

BO_ 400 ANZEIGE_ACC: 8 LDM
 SG_ ST_RADA_ACC : 16|2@1+ (1,0) [0|0] ""  CCC_MASK_RAD
 SG_ ST_DISP_OBJ_CAP : 48|3@1+ (1,0) [0|0] ""  Kombi
 SG_ ST_DISP_DVOR : 42|4@1+ (1,0) [0|0] ""  Kombi
 SG_ ST_DISP_DR_RQSP : 12|4@1+ (1,0) [0|0] ""  Kombi
 SG_ ST_DISP_DR_GAPC : 54|2@1+ (1,0) [0|0] ""  Kombi
 SG_ ST_ACC_SWO_SYS : 22|2@1+ (1,0) [0|0] ""  Kombi
 SG_ ST_ACC_MOD : 19|3@1+ (1,0) [0|0] ""  Kombi
 SG_ RCPT_ACTVN_DR : 30|2@1+ (1,0) [0|0] ""  Kombi
 SG_ GAP_AVL_TARO : 32|8@1+ (1,0) [0|0] "m"  Kombi
 SG_ DISP_SEN_DRT : 56|2@1+ (1,0) [0|0] ""  Kombi
 SG_ DISP_RECW : 28|2@1+ (1,0) [0|0] ""  Kombi
 SG_ DISP_OBJ_CAP : 46|2@1+ (1,0) [0|0] ""  Kombi
 SG_ DISP_GRQ : 58|2@1+ (1,0) [0|0] ""  Kombi
 SG_ DISP_DVOR : 40|2@1+ (1,0) [0|0] ""  Kombi
 SG_ DISP_DR_RQSP : 0|12@1+ (0.1,0) [0|0] "km/h"  Kombi
 SG_ DISP_DR_GAPC : 51|3@1+ (1,0) [0|0] ""  Kombi
 SG_ CHKSM_ACC : 60|4@1+ (1,0) [0|0] ""  Kombi
 SG_ ALIV_COU_ACC : 24|4@1+ (1,0) [0|0] ""  Kombi

BO_ 372 CHALLENGE_CAS_DME: 8 CAS
 SG_ TYP_CHRP_CASD : 59|4@1+ (1,0) [0|0] "" Vector__XXX
 SG_ ST_ENG_STA_CAS : 56|3@1+ (1,0) [0|0] "" Vector__XXX
 SG_ ST_CASD : 48|4@1+ (1,0) [0|0] "" Vector__XXX
 SG_ RQ_ST_DME : 52|3@1+ (1,0) [0|0] "" Vector__XXX
 SG_ CHRP_CASD : 0|48@1+ (1,0) [0|0] "" Vector__XXX

BO_ 354 ST_FFP: 6 FFP
 SG_ THR_SPAR_FFP : 32|8@1+ (0.4,0) [0|0] "%"  LDM
 SG_ ST_RCPT_FFP : 14|2@1+ (1,0) [0|0] ""  LDM
 SG_ ST_FFP_MOD : 12|2@1+ (1,0) [0|0] ""  LDM
 SG_ ST_ANG_AVL_FFP : 28|2@1+ (1,0) [0|0] ""  LDM
 SG_ CHKSM_ST_FFP : 0|8@1+ (1,0) [0|0] ""  LDM
 SG_ ANG_AVL_FFP : 16|12@1+ (0.025,0) [0|0] "%"  LDM
 SG_ ALIV_ST_FFP : 8|4@1+ (1,0) [0|0] ""  LDM

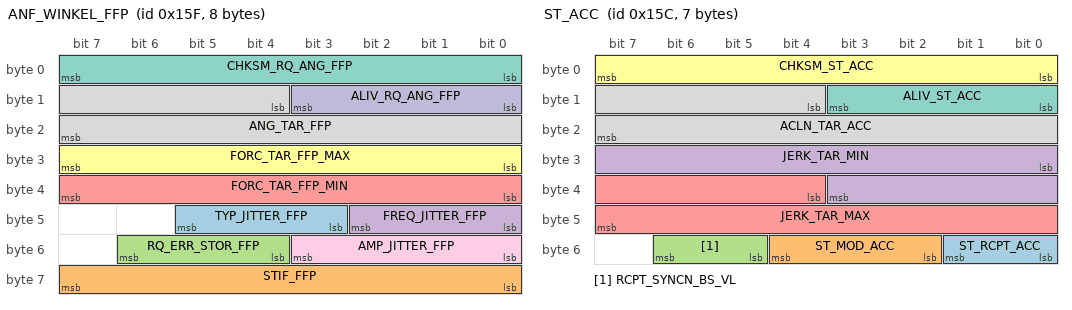
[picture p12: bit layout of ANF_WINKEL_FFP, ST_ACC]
BO_ 351 ANF_WINKEL_FFP: 8 LDM
 SG_ TYP_JITTER_FFP : 43|3@1+ (1,0) [0|0] ""  FFP
 SG_ STIF_FFP : 56|8@1+ (0.4,0) [0|0] "%"  FFP
 SG_ RQ_ERR_STOR_FFP : 52|3@1+ (1,0) [0|0] ""  FFP
 SG_ FREQ_JITTER_FFP : 40|3@1+ (1,0) [0|0] ""  FFP
 SG_ FORC_TAR_FFP_MIN : 32|8@1+ (0.4,0) [0|0] "%"  FFP
 SG_ FORC_TAR_FFP_MAX : 24|8@1+ (0.4,0) [0|0] "%"  FFP
 SG_ CHKSM_RQ_ANG_FFP : 0|8@1+ (1,0) [0|0] ""  FFP
 SG_ ANG_TAR_FFP : 12|12@1+ (0.025,0) [0|0] "%"  FFP
 SG_ AMP_JITTER_FFP : 48|4@1+ (1,0) [0|0] ""  FFP
 SG_ ALIV_RQ_ANG_FFP : 8|4@1+ (1,0) [0|0] ""  FFP

BO_ 348 ST_ACC: 7 ACC_Sensor
 SG_ ST_RCPT_ACC : 48|2@1+ (1,0) [0|0] ""  LDM
 SG_ ST_MOD_ACC : 50|3@1+ (1,0) [0|0] ""  LDM
 SG_ RCPT_SYNCN_BS_VL : 53|2@1+ (1,0) [0|0] ""  LDM
 SG_ JERK_TAR_MIN : 24|12@1+ (0.0039056,-7) [0|0] "m/s³"  LDM
 SG_ JERK_TAR_MAX : 36|12@1+ (0.0039056,-7) [0|0] "m/s³"  LDM
 SG_ CHKSM_ST_ACC : 0|8@1+ (1,0) [0|0] ""  LDM
 SG_ ALIV_ST_ACC : 8|4@1+ (1,0) [0|0] ""  LDM
 SG_ ACLN_TAR_ACC : 12|12@1+ (0.0625,-12) [0|0] "m/s²"  LDM

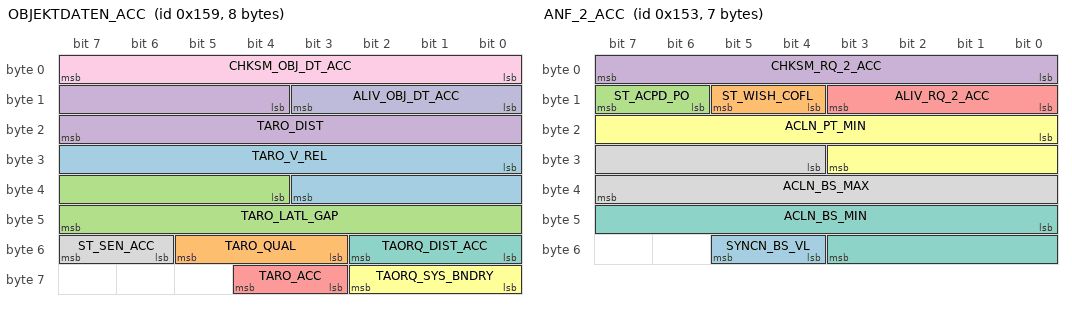
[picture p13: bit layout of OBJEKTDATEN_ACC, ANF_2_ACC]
BO_ 345 OBJEKTDATEN_ACC: 8 ACC_Sensor
 SG_ TARO_V_REL : 24|12@1+ (0.125,-250) [0|0] "km/h"  LDM
 SG_ TARO_QUAL : 51|3@1+ (20,0) [0|0] "%"  LDM
 SG_ TARO_LATL_GAP : 36|12@1+ (0.0625,-20) [0|0] "m"  LDM
 SG_ TARO_DIST : 12|12@1+ (0.125,0) [0|0] "m"  LDM
 SG_ TARO_ACC : 59|2@1+ (1,0) [0|0] ""  LDM
 SG_ TAORQ_SYS_BNDRY : 56|3@1+ (1,0) [0|0] ""  LDM
 SG_ TAORQ_DIST_ACC : 48|3@1+ (1,0) [0|0] ""  LDM
 SG_ ST_SEN_ACC : 54|2@1+ (1,0) [0|0] ""  LDM
 SG_ CHKSM_OBJ_DT_ACC : 0|8@1+ (1,0) [0|0] ""  LDM
 SG_ ALIV_OBJ_DT_ACC : 8|4@1+ (1,0) [0|0] ""  LDM

BO_ 339 ANF_2_ACC: 7 LDM
 SG_ SYNCN_BS_VL : 52|2@1+ (1,0) [0|0] ""  ACC_Sensor
 SG_ ST_WISH_COFL : 12|2@1+ (1,0) [0|0] ""  ACC_Sensor
 SG_ ST_ACPD_PO : 14|2@1+ (1,0) [0|0] ""  ACC_Sensor
 SG_ CHKSM_RQ_2_ACC : 0|8@1+ (1,0) [0|0] ""  ACC_Sensor
 SG_ ALIV_RQ_2_ACC : 8|4@1+ (1,0) [0|0] ""  ACC_Sensor
 SG_ ACLN_PT_MIN : 16|12@1+ (0.0625,-12) [0|0] "m/s²"  ACC_Sensor
 SG_ ACLN_BS_MIN : 40|12@1+ (0.0625,-12) [0|0] "m/s²"  ACC_Sensor
 SG_ ACLN_BS_MAX : 28|12@1+ (0.0625,-12) [0|0] "m/s²"  ACC_Sensor

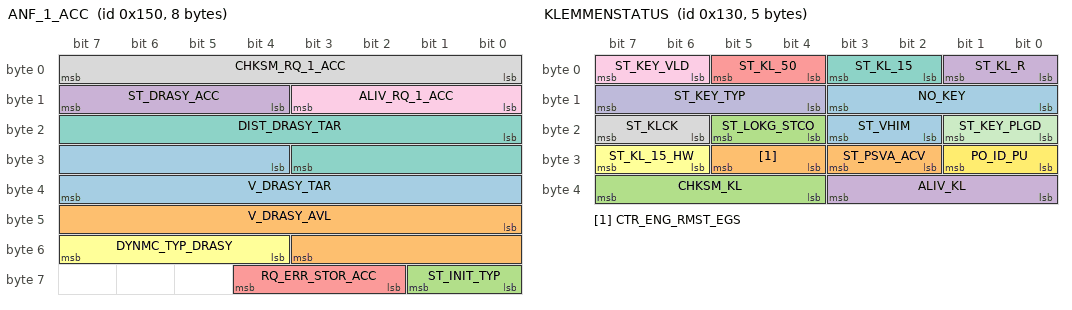
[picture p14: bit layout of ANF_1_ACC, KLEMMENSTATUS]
BO_ 336 ANF_1_ACC: 8 LDM
 SG_ V_DRASY_TAR : 28|12@1+ (0.125,0) [0|0] "km/h"  ACC_Sensor
 SG_ V_DRASY_AVL : 40|12@1+ (0.125,0) [0|0] "km/h"  ACC_Sensor
 SG_ ST_INIT_TYP : 56|2@1+ (1,0) [0|0] ""  ACC_Sensor
 SG_ ST_DRASY_ACC : 12|4@1+ (1,0) [0|0] ""  ACC_Sensor
 SG_ RQ_ERR_STOR_ACC : 58|3@1+ (1,0) [0|0] ""  ACC_Sensor
 SG_ DYNMC_TYP_DRASY : 52|4@1+ (1,0) [0|0] ""  ACC_Sensor
 SG_ DIST_DRASY_TAR : 16|12@1+ (0.125,0) [0|0] "m"  ACC_Sensor
 SG_ CHKSM_RQ_1_ACC : 0|8@1+ (1,0) [0|0] ""  ACC_Sensor
 SG_ ALIV_RQ_1_ACC : 8|4@1+ (1,0) [0|0] ""  ACC_Sensor

BO_ 309 CTR_CRASH_SWO_EKP: 2 MRSZ
 SG_ CTR_CR_SWO_EKP : 0|4@1+ (1,0) [0|0] ""  EKP,DME1_DDE1

BO_ 304 KLEMMENSTATUS: 5 CAS
 SG_ ST_VHIM : 18|2@1+ (1,0) [0|0] "" Vector__XXX
 SG_ ST_PSVA_ACV : 26|2@1+ (1,0) [0|0] "" Vector__XXX
 SG_ ST_LOKG_STCO : 20|2@1+ (1,0) [0|0] "" Vector__XXX
 SG_ ST_KL_R : 0|2@1+ (1,0) [0|0] ""  ZBE,SZL_LWS,SM_FA,SM_BF,SHD,RDC,MRSZ,LDM,Kombi,JBBF,IHx,FZD,FRMFA,EKP,EHC,DWA,DSC_DXC,DME1_DDE1,CVM_V,CID_V,CCC_MASK_RAD,CAS,AHM,AFS,ACC_Sensor
 SG_ ST_KL_50 : 4|2@1+ (1,0) [0|0] ""  SZL_LWS,SHD,Kombi,JBBF,IHx,FZD,FRMFA,DSC_DXC,DME1_DDE1,CCC_MASK_RAD,CAS,AFS
 SG_ ST_KL_15_HW : 30|2@1+ (1,0) [0|0] "" Vector__XXX
 SG_ ST_KL_15 : 2|2@1+ (1,0) [0|0] ""  ZBE,VVT1,VGSG,SZL_LWS,SM_FA,SM_BF,SHD,RDC,PGS,PDC,MRSZ,LDM,Kombi,JBBF,IHx,FZD,FRMFA,EPS,EKP,EHC,EGS_SSG,DWA,DSC_DXC,DME1_DDE1,CVM_V,CID_V,CCC_MASK_RAD,AHM,AFS,ACC_Sensor
 SG_ ST_KLCK : 22|2@1+ (1,0) [0|0] "" Vector__XXX
 SG_ ST_KEY_VLD : 6|2@1+ (1,0) [0|0] ""  FRMFA,DWA,DME1_DDE1,CCC_MASK_RAD
 SG_ ST_KEY_TYP : 12|4@1+ (1,0) [0|0] "" Vector__XXX
 SG_ ST_KEY_PLGD : 16|2@1+ (1,0) [0|0] ""  ZBE,SZL_LWS,SM_FA,PGS,Kombi,FRMFA,DWA,CCC_MASK_RAD,CAS
 SG_ PO_ID_PU : 24|2@1+ (1,0) [0|0] "" Vector__XXX
 SG_ NO_KEY : 8|4@1+ (1,0) [0|0] ""  DWA,DME1_DDE1,CCC_MASK_RAD,CAS
 SG_ CTR_ENG_RMST_EGS : 28|2@1+ (1,0) [0|0] "" Vector__XXX
 SG_ CHKSM_KL : 36|4@1+ (1,0) [0|0] ""  LDM,EGS_SSG,DME1_DDE1,ACC_Sensor
 SG_ ALIV_KL : 32|4@1+ (1,0) [0|0] ""  LDM,EGS_SSG,DSC_DXC,DME1_DDE1,ACC_Sensor

BO_ 224 STAT_LENKUNTERSTUETZUNG: 2 dummy
 SG_ ST_SGM : 8|2@1+ (1,0) [0|0] ""  AFS
 SG_ ST_EPAS : 0|4@1+ (1,0) [0|0] ""  AFS
 SG_ ST_ECO : 4|4@1+ (1,0) [0|0] ""  AFS

BO_ 225 RADMOM_BREMSE: 6 DSC_DXC
 SG_ ST_ECBA_TEMP : 42|3@1+ (1,0) [0|0] "" Vector__XXX
 SG_ ST_INTF_ECBA : 45|3@1+ (1,0) [0|0] "" Vector__XXX
 SG_ ST_DR_ACTVN_BRK : 40|2@1+ (1,0) [0|0] "" Vector__XXX
 SG_ WMOM_BRK_DIFF_AVL : 12|12@1+ (0.0625,-100) [0|0] "%"  LDM
 SG_ WMOM_BRK_AVL : 24|16@1+ (1,-32000) [0|0] "Nm"  LDM
 SG_ CHKSM_WMOM_BRK : 0|8@1+ (1,0) [0|0] ""  LDM
 SG_ ALIV_WMOM_BRK : 8|4@1+ (1,0) [0|0] ""  LDM

BO_ 213 ANF_RADMOM_BREMSE: 8 LDM
 SG_ tmp : 48|16@1+ (1,0) [0|0] "" Vector__XXX
 SG_ ERR_TR_LDM : 42|2@1+ (1,0) [0|0] "" Vector__XXX
 SG_ WMOM_ECBA_ENB : 40|2@1+ (1,0) [0|0] "" Vector__XXX
 SG_ WMOM_BRK_TAR : 24|16@1+ (1,0) [0|0] "Nm"  DSC_DXC
 SG_ WMOM_BRK_DIFF_TAR : 12|12@1+ (0.0625,-100) [0|0] "%"  DSC_DXC
 SG_ CHKSM_RQ_WMOM_BRK : 0|8@1+ (1,0) [0|0] ""  DSC_DXC
 SG_ ALIV_RQ_WMOM_BRK : 8|4@1+ (1,0) [0|0] ""  DSC_DXC

BO_ 206 GESCHWINDIGKEIT_RAD: 8 DSC_DXC
 SG_ V_WHL_RRH : 48|16@1- (0.0625,0) [0|0] "km/h"  VGSG,SZL_LWS,LDM,EGS_SSG,DSC_DXC,DME1_DDE1,CCC_MASK_RAD,AFS,ACC_Sensor
 SG_ V_WHL_RLH : 32|16@1- (0.0625,0) [0|0] "km/h"  VGSG,SZL_LWS,LDM,EGS_SSG,DSC_DXC,DME1_DDE1,CCC_MASK_RAD,AFS,ACC_Sensor
 SG_ V_WHL_FRH : 16|16@1- (0.0625,0) [0|0] "km/h"  VGSG,SZL_LWS,LDM,EGS_SSG,DSC_DXC,DME1_DDE1,CCC_MASK_RAD,AFS,ACC_Sensor
 SG_ V_WHL_FLH : 0|16@1- (0.0625,0) [0|0] "km/h"  VGSG,SZL_LWS,LDM,EGS_SSG,DSC_DXC,DME1_DDE1,CCC_MASK_RAD,AFS,ACC_Sensor

BO_ 203 YAW_ANSWER: 6 dummy
 SG_ RWDT_V_YAW : 0|48@1+ (1,0) [0|0] ""  DSC_DXC

BO_ 202 YAW_REQUEST: 2 DSC_DXC
 SG_ RQ_RWDT_V_YAW : 0|16@1+ (1,0) [0|0] "" Vector__XXX

BO_ 200 LENKRADWINKEL_OBEN: 6 SZL_LWS
 SG_ STWA_TOP_V : 24|16@1- (0.04395,0) [0|0] "°/s"  FRMFA,EPS,DSC_DXC,AFS
 SG_ STWA_TOP_ERR : 16|2@1+ (1,0) [0|0] ""  FRMFA,EPS,DSC_DXC,AFS
 SG_ STWA_TOP : 0|16@1- (0.04395,0) [0|0] "°"  FRMFA,EPS,DSC_DXC,CAS,AFS
 SG_ SI_SYST_0_SZL_STWA : 40|8@1+ (250,0) [0|0] "µs"  FRMFA,EPS,DSC_DXC
 SG_ ALIV_COU_STWA_TOP : 20|4@1+ (1,0) [0|0] ""  AFS

BO_ 196 LENKRADWINKEL: 7 DSC_DXC
 SG_ TYP_STWA : 48|2@1+ (1,0) [0|0] ""  CCC_MASK_RAD
 SG_ STWA_V : 24|16@1- (0.04395,0) [0|0] "°/s"  VGSG,LDM,DSC_DXC,DME1_DDE1,CCC_MASK_RAD
 SG_ STWA_ERR : 16|2@1+ (1,0) [0|0] ""  LDM,FRMFA_ALC,FRMFA,EGS_SSG,DSC_DXC,DME1_DDE1,CCC_MASK_RAD,ACC_Sensor
 SG_ STWA : 0|16@1- (0.04395,0) [0|0] "°"  VGSG,FRMFA_ALC,FRMFA,EGS_SSG,DSC_DXC,DME1_DDE1,CCC_MASK_RAD,ACC_Sensor
 SG_ SRC_STWA : 50|2@1+ (1,0) [0|0] "" Vector__XXX
 SG_ SI_SYST_0_SZL_STEA : 40|8@1+ (250,0) [0|0] "µs"  DSC_DXC

BO_ 191 ANF_RADMOM_PT: 5 LDM
 SG_ WMOM_PT_TAR : 16|16@1+ (1,-32000) [0|0] "Nm"  EGS_SSG,DME1_DDE1
 SG_ ST_DRASY_PT : 32|4@1+ (1,0) [0|0] ""  EGS_SSG,DME1_DDE1
 SG_ RQ_PREV_INFS : 36|2@1+ (1,0) [0|0] ""  DME1_DDE1
 SG_ FOLDYN_WMOM_PT_TAR : 12|4@1+ (1,0) [0|0] ""  EGS_SSG,DME1_DDE1
 SG_ CHKSM_RQ_WMOM_PT : 0|8@1+ (1,0) [0|0] ""  EGS_SSG,DME1_DDE1
 SG_ ALIV_RQ_WMOM_PT : 8|4@1+ (1,0) [0|0] ""  EGS_SSG,DME1_DDE1

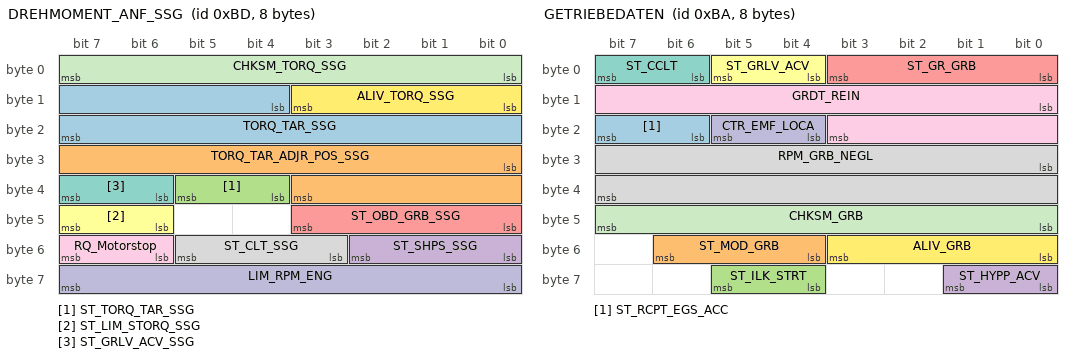
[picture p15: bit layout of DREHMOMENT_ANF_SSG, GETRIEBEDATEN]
BO_ 189 DREHMOMENT_ANF_SSG: 8 EGS_SSG
 SG_ TORQ_TAR_SSG : 12|12@1- (0.5,0) [0|0] "Nm"  DME1_DDE1
 SG_ TORQ_TAR_ADJR_POS_SSG : 24|12@1- (0.5,0) [0|0] "Nm"  DME1_DDE1
 SG_ ST_TORQ_TAR_SSG : 36|2@1+ (1,0) [0|0] ""  DME1_DDE1
 SG_ ST_SHPS_SSG : 48|3@1+ (1,0) [0|0] ""  DSC_DXC,DME1_DDE1
 SG_ ST_OBD_GRB_SSG : 40|4@1+ (1,0) [0|0] ""  DME1_DDE1
 SG_ ST_LIM_STORQ_SSG : 46|2@1+ (1,0) [0|0] ""  DME1_DDE1
 SG_ ST_GRLV_ACV_SSG : 38|2@1+ (1,0) [0|0] ""  DSC_DXC,DME1_DDE1
 SG_ ST_CLT_SSG : 51|3@1+ (1,0) [0|0] ""  DSC_DXC,DME1_DDE1
 SG_ RQ_Motorstop : 54|2@1+ (1,0) [0|0] ""  DME1_DDE1
 SG_ LIM_RPM_ENG : 56|8@1+ (29.4118,0) [0|0] "1/min"  DME1_DDE1
 SG_ CHKSM_TORQ_SSG : 0|8@1+ (1,0) [0|0] ""  DSC_DXC,DME1_DDE1
 SG_ ALIV_TORQ_SSG : 8|4@1+ (1,0) [0|0] ""  DSC_DXC,DME1_DDE1

BO_ 188 STAT_SOLL_MOM_UMSETZUNG: 7 VGSG
 SG_ THR_STRS_E_MOT : 24|8@1+ (1,0) [0|0] "%"  DSC_DXC
 SG_ THR_STRS_CLT : 16|8@1+ (1,0) [0|0] "%"  DSC_DXC
 SG_ TEMP_OIL_TXU : 8|8@1+ (1,-40) [0|0] "C"  DSC_DXC
 SG_ TEMP_ENG_TXU : 0|8@1+ (1,-40) [0|0] "C"  VGSG,DSC_DXC
 SG_ ST_TXU_ERR : 36|4@1+ (1,0) [0|0] ""  DSC_DXC
 SG_ ST_TXU_CLT : 32|4@1+ (1,0) [0|0] ""  DSC_DXC
 SG_ AVL_TAR_MOM_FTAX : 40|16@1+ (0.0390625,0) [0|0] "Nm"  DSC_DXC

BO_ 187 SOLL_MOM_ANF: 3 DSC_DXC
 SG_ TAR_MOM_FTAX : 0|16@1+ (0.0390625,0) [0|0] "Nm"  VGSG
 SG_ RQ_FNT : 20|2@1+ (1,0) [0|0] ""  VGSG
 SG_ EMMOD_OPN : 22|2@1+ (1,0) [0|0] ""  VGSG
 SG_ DYNMC_DXC : 18|2@1+ (1,0) [0|0] ""  VGSG
 SG_ ACV_OPN : 16|2@1+ (1,0) [0|0] ""  VGSG

BO_ 186 GETRIEBEDATEN: 8 EGS_SSG
 SG_ ST_RCPT_EGS_ACC : 22|2@1+ (1,0) [0|0] ""  LDM
 SG_ ST_MOD_GRB : 52|3@1+ (1,0) [0|0] ""  DME1_DDE1
 SG_ ST_ILK_STRT : 60|2@1+ (1,0) [0|0] ""  CAS
 SG_ ST_HYPP_ACV : 56|2@1+ (1,0) [0|0] ""  DME1_DDE1
 SG_ ST_GR_GRB : 0|4@1+ (1,0) [0|0] ""  PDC,LDM,JBBF,FZD,FRMFA_ALC,FRMFA,DSC_DXC,DME1_DDE1,CCC_MASK_RAD,CAS
 SG_ ST_GRLV_ACV : 4|2@1+ (1,0) [0|0] ""  LDM,DSC_DXC,DME1_DDE1
 SG_ ST_CCLT : 6|2@1+ (1,0) [0|0] ""  DSC_DXC,DME1_DDE1
 SG_ RPM_GRB_NEGL : 24|16@1+ (0.125,0) [0|0] "1/min"  DSC_DXC
 SG_ GRDT_REIN : 8|12@1+ (0.125,0) [0|0] "1/m"  LDM,DSC_DXC,DME1_DDE1
 SG_ CTR_EMF_LOCA : 20|2@1+ (1,0) [0|0] "" Vector__XXX
 SG_ CHKSM_GRB : 40|8@1+ (1,0) [0|0] ""  LDM,DSC_DXC
 SG_ ALIV_GRB : 48|4@1+ (1,0) [0|0] ""  LDM,DSC_DXC

BO_ 185 DREHMOMENT_ANF_AFS: 6 AFS
 SG_ TORQ_TAR_AFS : 24|12@1- (0.5,0) [0|0] "Nm"  DME1_DDE1
 SG_ TORQ_AVL_AFS : 12|12@1- (0.5,0) [0|0] "Nm"  DME1_DDE1
 SG_ ST_TORQ_TAR_AFS : 36|2@1+ (1,0) [0|0] ""  DME1_DDE1
 SG_ ST_RQ_TORQ_AFS_ERR : 40|4@1+ (1,0) [0|0] ""  DME1_DDE1
 SG_ CHKSM_TORQ_AFS : 0|8@1+ (1,0) [0|0] ""  DME1_DDE1
 SG_ ALIV_TORQ_AFS : 8|4@1+ (1,0) [0|0] ""  DME1_DDE1

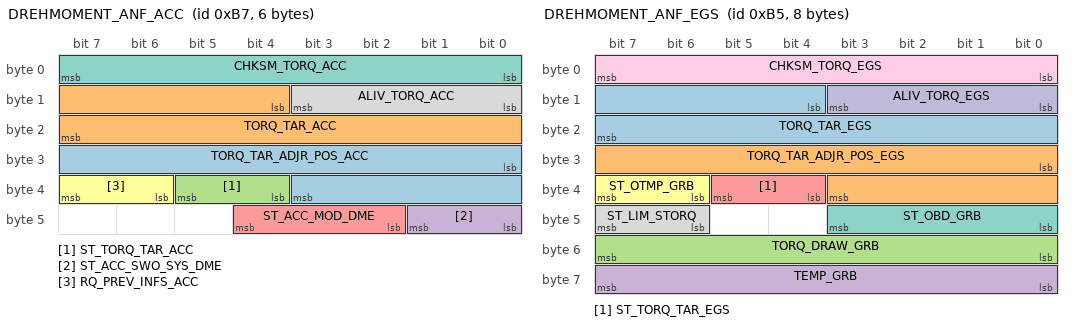
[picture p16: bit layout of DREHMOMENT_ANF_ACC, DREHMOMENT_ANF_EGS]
BO_ 183 DREHMOMENT_ANF_ACC: 6 LDM
 SG_ TORQ_TAR_ADJR_POS_ACC : 24|12@1- (0.5,0) [0|0] "Nm"  DME1_DDE1
 SG_ TORQ_TAR_ACC : 12|12@1- (0.5,0) [0|0] "Nm"  EGS_SSG,DME1_DDE1
 SG_ ST_TORQ_TAR_ACC : 36|2@1+ (1,0) [0|0] ""  EGS_SSG,DME1_DDE1
 SG_ ST_ACC_SWO_SYS_DME : 40|2@1+ (1,0) [0|0] ""  EGS_SSG,DME1_DDE1
 SG_ ST_ACC_MOD_DME : 42|3@1+ (1,0) [0|0] ""  EGS_SSG,DME1_DDE1
 SG_ RQ_PREV_INFS_ACC : 38|2@1+ (1,0) [0|0] ""  DME1_DDE1
 SG_ CHKSM_TORQ_ACC : 0|8@1+ (1,0) [0|0] ""  EGS_SSG,DME1_DDE1
 SG_ ALIV_TORQ_ACC : 8|4@1+ (1,0) [0|0] ""  EGS_SSG,DME1_DDE1

BO_ 182 DREHMOMENT_ANF_DSC: 5 DSC_DXC
 SG_ TORQ_TAR_DSC : 12|12@1- (0.5,0) [0|0] "Nm"  EGS_SSG,DME1_DDE1
 SG_ TORQ_TAR_ADJR_POS_DSC : 24|12@1- (0.5,0) [0|0] "Nm"  DME1_DDE1
 SG_ ST_TORQ_TAR_DSC : 36|2@1+ (1,0) [0|0] ""  EGS_SSG,DME1_DDE1
 SG_ CHKSM_TORQ_DSC : 0|8@1+ (1,0) [0|0] ""  DSC_DXC,DME1_DDE1
 SG_ ALIV_TORQ_DSC : 8|4@1+ (1,0) [0|0] ""  DSC_DXC,DME1_DDE1

BO_ 181 DREHMOMENT_ANF_EGS: 8 EGS_SSG
 SG_ TORQ_TAR_EGS : 12|12@1- (0.5,0) [0|0] "Nm"  DME1_DDE1
 SG_ TORQ_TAR_ADJR_POS_EGS : 24|12@1- (0.5,0) [0|0] "Nm"  DME1_DDE1
 SG_ TORQ_DRAW_GRB : 48|8@1+ (0.5,0) [0|0] "Nm"  DME1_DDE1
 SG_ TEMP_GRB : 56|8@1+ (1,-40) [0|0] "°C"  DME1_DDE1
 SG_ ST_TORQ_TAR_EGS : 36|2@1+ (1,0) [0|0] ""  DME1_DDE1
 SG_ ST_OTMP_GRB : 38|2@1+ (1,0) [0|0] ""  DME1_DDE1
 SG_ ST_OBD_GRB : 40|4@1+ (1,0) [0|0] ""  DME1_DDE1
 SG_ ST_LIM_STORQ : 46|2@1+ (1,0) [0|0] ""  DME1_DDE1
 SG_ CHKSM_TORQ_EGS : 0|8@1+ (1,0) [0|0] ""  DME1_DDE1
 SG_ ALIV_TORQ_EGS : 8|4@1+ (1,0) [0|0] ""  DME1_DDE1

BO_ 179 CTR_LENKUNTERSTUETZUNG: 4 AFS
 SG_ CTR_EPAS_AFS : 0|12@1+ (1,0) [0|0] "mA" Vector__XXX
 SG_ CTR_ECO_AFS : 12|12@1+ (1,0) [0|0] "mA" Vector__XXX
 SG_ ALIV_ASS_STE_AFS : 24|4@1+ (1,0) [0|0] ""  Kombi

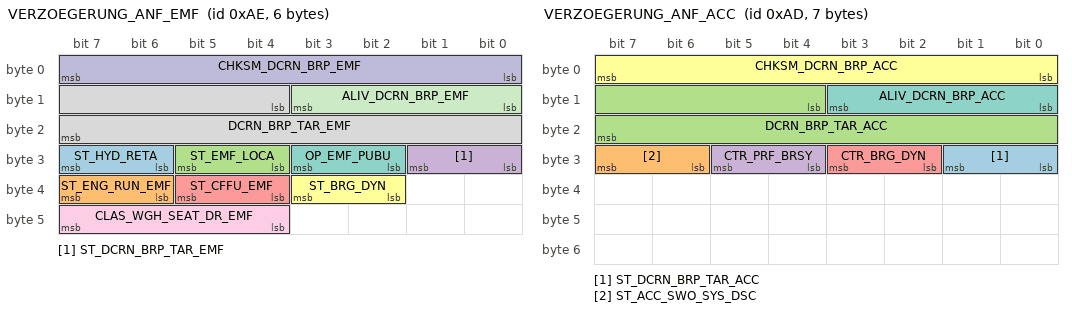
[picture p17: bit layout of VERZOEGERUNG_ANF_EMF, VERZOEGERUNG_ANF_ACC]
BO_ 174 VERZOEGERUNG_ANF_EMF: 6 dummy
 SG_ ST_HYD_RETA : 30|2@1+ (1,0) [0|0] ""  EGS_SSG,CCC_MASK_RAD
 SG_ ST_ENG_RUN_EMF : 38|2@1+ (1,0) [0|0] ""  DSC_DXC
 SG_ ST_EMF_LOCA : 28|2@1+ (1,0) [0|0] ""  DSC_DXC,CCC_MASK_RAD
 SG_ ST_DCRN_BRP_TAR_EMF : 24|2@1+ (1,0) [0|0] ""  DSC_DXC
 SG_ ST_CFFU_EMF : 36|2@1+ (1,0) [0|0] ""  DSC_DXC
 SG_ ST_BRG_DYN : 34|2@1+ (1,0) [0|0] "" Vector__XXX
 SG_ OP_EMF_PUBU : 26|2@1+ (1,0) [0|0] ""  DSC_DXC
 SG_ DCRN_BRP_TAR_EMF : 12|12@1- (0.01,0) [0|0] "m/s²"  DSC_DXC
 SG_ CLAS_WGH_SEAT_DR_EMF : 44|4@1+ (1,0) [0|0] ""  DSC_DXC
 SG_ CHKSM_DCRN_BRP_EMF : 0|8@1+ (1,0) [0|0] ""  DSC_DXC
 SG_ ALIV_DCRN_BRP_EMF : 8|4@1+ (1,0) [0|0] ""  DSC_DXC

BO_ 173 VERZOEGERUNG_ANF_ACC: 7 LDM
 SG_ ST_DCRN_BRP_TAR_ACC : 24|2@1+ (1,0) [0|0] ""  DSC_DXC
 SG_ ST_ACC_SWO_SYS_DSC : 30|2@1+ (1,0) [0|0] ""  DSC_DXC
 SG_ DCRN_BRP_TAR_ACC : 12|12@1- (0.01,0) [0|0] "m/s²"  DSC_DXC
 SG_ CTR_PRF_BRSY : 28|2@1+ (1,0) [0|0] ""  DSC_DXC
 SG_ CTR_BRG_DYN : 26|2@1+ (1,0) [0|0] ""  DSC_DXC
 SG_ CHKSM_DCRN_BRP_ACC : 0|8@1+ (1,0) [0|0] ""  DSC_DXC
 SG_ ALIV_DCRN_BRP_ACC : 8|4@1+ (1,0) [0|0] ""  DSC_DXC

BO_ 172 RADMOM_PT_2: 8 DME1_DDE1
 SG_ WMOM_PT_MIN_LOW : 32|16@1+ (1,-32000) [0|0] "Nm"  LDM
 SG_ WMOM_PT_MIN_HIGH : 16|16@1+ (1,-32000) [0|0] "Nm"  LDM
 SG_ WMOM_PT_MAX : 48|16@1+ (1,-32000) [0|0] "Nm"  LDM
 SG_ ST_PT_INIT : 12|2@1+ (1,0) [0|0] ""  LDM
 SG_ CHKSM_WMOM_PT_2 : 0|8@1+ (1,0) [0|0] ""  LDM
 SG_ ALIV_WMOM_PT_2 : 8|4@1+ (1,0) [0|0] ""  LDM

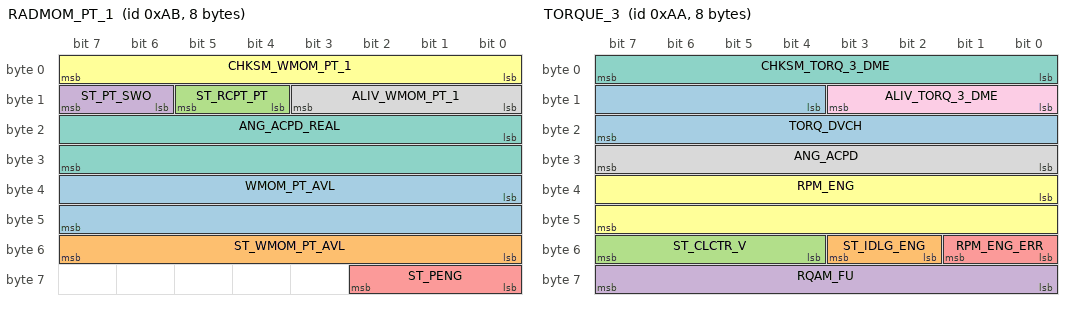
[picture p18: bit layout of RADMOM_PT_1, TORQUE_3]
BO_ 171 RADMOM_PT_1: 8 DME1_DDE1
 SG_ WMOM_PT_AVL : 32|16@1+ (1,-32000) [0|0] "Nm"  LDM
 SG_ ST_WMOM_PT_AVL : 48|8@1+ (1,0) [0|0] ""  LDM
 SG_ ST_RCPT_PT : 12|2@1+ (1,0) [0|0] ""  LDM
 SG_ ST_PT_SWO : 14|2@1+ (1,0) [0|0] ""  LDM
 SG_ ST_PENG : 56|3@1+ (1,0) [0|0] ""  LDM
 SG_ CHKSM_WMOM_PT_1 : 0|8@1+ (1,0) [0|0] ""  LDM
 SG_ ANG_ACPD_REAL : 16|16@1+ (0.0016,0) [0|0] "%"  LDM
 SG_ ALIV_WMOM_PT_1 : 8|4@1+ (1,0) [0|0] ""  LDM

BO_ 170 TORQUE_3: 8 DME1_DDE1
 SG_ TORQ_DVCH : 12|12@1- (0.5,0) [0|0] "Nm"  LDM,EGS_SSG,DSC_DXC
 SG_ ST_IDLG_ENG : 50|2@1+ (1,0) [0|0] ""  LDM,Kombi,EGS_SSG,DSC_DXC
 SG_ ST_CLCTR_V : 52|4@1+ (1,0) [0|0] ""  LDM,EGS_SSG,DSC_DXC
 SG_ RQAM_FU : 56|8@1+ (1,0) [0|0] "l/h"  JBBF,EKP
 SG_ RPM_ENG_ERR : 48|2@1+ (1,0) [0|0] ""  LDM,EPS,EKP,EGS_SSG,DSC_DXC,AFS
 SG_ RPM_ENG : 32|16@1+ (0.25,0) [0|0] "1/min"  VVT1,VGSG,LDM,Kombi,IHx,EPS,EKP,EGS_SSG,DSC_DXC,CAS,AFS
 SG_ CHKSM_TORQ_3_DME : 0|8@1+ (1,0) [0|0] ""  LDM,EGS_SSG,DSC_DXC
 SG_ ANG_ACPD : 24|8@1+ (0.39063,0) [0|0] "%"  VGSG,LDM,EGS_SSG,DSC_DXC,CCC_MASK_RAD,AFS
 SG_ ALIV_TORQ_3_DME : 8|4@1+ (1,0) [0|0] ""  LDM,EGS_SSG,DSC_DXC

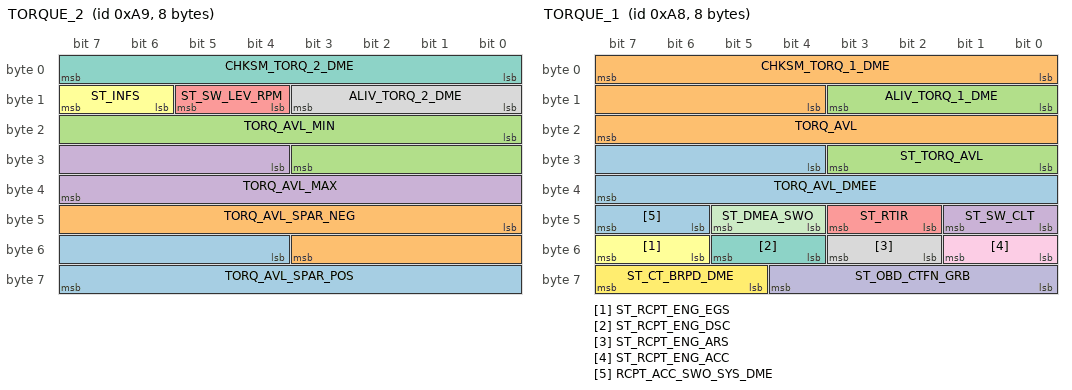
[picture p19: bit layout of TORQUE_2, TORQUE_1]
BO_ 169 TORQUE_2: 8 DME1_DDE1
 SG_ TORQ_AVL_SPAR_POS : 52|12@1- (0.5,0) [0|0] "Nm"  LDM,EGS_SSG,DSC_DXC
 SG_ TORQ_AVL_SPAR_NEG : 40|12@1- (0.5,0) [0|0] "Nm"  LDM,EGS_SSG,DSC_DXC
 SG_ TORQ_AVL_MIN : 16|12@1- (0.5,0) [0|0] "Nm"  LDM,EGS_SSG,DSC_DXC
 SG_ TORQ_AVL_MAX : 28|12@1- (0.5,0) [0|0] "Nm"  LDM,EGS_SSG,DSC_DXC
 SG_ ST_SW_LEV_RPM : 12|2@1+ (1,0) [0|0] ""  EGS_SSG
 SG_ ST_INFS : 14|2@1+ (1,0) [0|0] ""  LDM,DSC_DXC
 SG_ CHKSM_TORQ_2_DME : 0|8@1+ (1,0) [0|0] ""  LDM,EGS_SSG,DSC_DXC
 SG_ ALIV_TORQ_2_DME : 8|4@1+ (1,0) [0|0] ""  LDM,EGS_SSG,DSC_DXC

BO_ 168 TORQUE_1: 8 DME1_DDE1
 SG_ TORQ_AVL_DMEE : 28|12@1- (0.5,0) [0|0] "Nm"  EGS_SSG
 SG_ TORQ_AVL : 12|12@1- (0.5,0) [0|0] "Nm"  LDM,EGS_SSG,DSC_DXC
 SG_ ST_TORQ_AVL : 24|4@1+ (1,0) [0|0] ""  LDM,EGS_SSG,DSC_DXC
 SG_ ST_SW_CLT : 40|2@1+ (1,0) [0|0] ""  LDM,DSC_DXC,CAS
 SG_ ST_RTIR : 42|2@1+ (1,0) [0|0] ""  EGS_SSG
 SG_ ST_RCPT_ENG_EGS : 54|2@1+ (1,0) [0|0] ""  EGS_SSG
 SG_ ST_RCPT_ENG_DSC : 52|2@1+ (1,0) [0|0] ""  DSC_DXC
 SG_ ST_RCPT_ENG_ARS : 50|2@1+ (1,0) [0|0] "" Vector__XXX
 SG_ ST_RCPT_ENG_ACC : 48|2@1+ (1,0) [0|0] ""  LDM
 SG_ ST_OBD_CTFN_GRB : 56|5@1+ (1,0) [0|0] ""  EGS_SSG
 SG_ ST_DMEA_SWO : 44|2@1+ (1,0) [0|0] ""  LDM
 SG_ ST_CT_BRPD_DME : 61|3@1+ (1,0) [0|0] ""  LDM,EGS_SSG,DSC_DXC,AFS
 SG_ RCPT_ACC_SWO_SYS_DME : 46|2@1+ (1,0) [0|0] ""  LDM
 SG_ CHKSM_TORQ_1_DME : 0|8@1+ (1,0) [0|0] ""  LDM,EGS_SSG,DSC_DXC
 SG_ ALIV_TORQ_1_DME : 8|4@1+ (1,0) [0|0] ""  LDM,EGS_SSG,DSC_DXC

CM_ BU_ VGSG "Zentrales Gateway - ersetzt alle Knoten des Pt-CAN
Identisch mit SIM?";
CM_ BU_ JBBF "Zentrales Gateway - ersetzt alle Knoten des Pt-CAN
Identisch mit SIM?";
CM_ BU_ EPS "Zentrales Gateway - ersetzt alle Knoten des Pt-CAN
Identisch mit SIM?";
CM_ BU_ EKP "Zentrales Gateway - ersetzt alle Knoten des Pt-CAN
Identisch mit SIM?";
CM_ BO_ 3221225472 "This is a message for not used signals, created by Vector CANdb++ DBC OLE DB Provider.";
CM_ BO_ 1003 "<P>Mit dieser Nachricht wird vor dem Start und nach Beendigung des Tests eine entsprechende Testnummer gesendet, um in Log-Files immer den (die) laufenden Test(s) mitzuprotokollieren. Diese könnte auch zur intelligenten Steuerung der Auswertung benutzt werden oder als Marker eines auftretenden Ereignisses.</P>
";
CM_ BO_ 1002 "<P>Mit dieser Nachricht wird vor dem Start und nach Beendigung des Tests eine entsprechende Testnummer gesendet, um in Log-Files immer den (die) laufenden Test(s) mitzuprotokollieren. Diese kann zur intelligenten Steuerung der Auswertung benutzt werden. Dabei können Informationen an die Testauswertung übermittelt werden. Die Nachricht kann auch zur Anzeige spezieller Ereignisse im Logfile verwendet werden.</P>
";
CM_ BO_ 1001 "<P>Mit dieser Nachricht wird vor dem Start und nach Beendigung des Tests eine entsprechende Testnummer gesendet, um in Log-Files immer den (die) laufenden Test(s) mitzuprotokollieren. Diese könnte auch zur intelligenten Steuerung der Auswertung benutzt werden oder als Marker eines auftretenden Ereignisses.</P>
";
CM_ BO_ 987 "<P>HINWEIS E6x:
Im E60/61 wird die Nachricht \"Status Memorypositionen CKM\" vom SM_FA versandt.
Im E63/64 sendet das SZM_MIT_KBUS diese Nachricht, da die Sitzmodule hinter dem SZM am K-Bus verbaut sind.
Die automatisch generierten CANdbs unterstützen nur einen Sender der Nachricht. Es muß also kontrolliert werden, ob der jeweils \"richtige Sender\" in der CANdb eingetragen ist. Wenn nicht, muß der Sender in der CANdb von Hand geändert werden.</P>
";
CM_ BO_ 958 "<P>Die Schaltfunktion der Stromversorgung (Klemme 30g) wird im Steuergerät CAS implementiert. Eine redundante Ansteuerung (HW-Pfad) erfolgt bei der Zündschlossstellung 'Klemme_15'.

Sie enthält eine applizierbare Nachlaufzeit. Optional, derzeit jedoch nur vorgehalten, ist die Nachlaufzeit im Kundendienst über einen Diagnosebefehl bis zu einem definierten Maximalwert verlängerbar. Eine dynamische, durch andere Bordnetzteilnehmer programmierbare Weckfunktion im Steuergerät CAS ist nicht realisiert.

Weit";
CM_ BO_ 957 "<P>Diese Nachricht enthält das Signal Status_Klemme_VA.</P>
";
CM_ BO_ 949 "<P>Übermittelt den aktuellen Status und Öffnungsgrad des Wasserventils.
PL2: Die JBBF steuert und kontrolliert über eine HW-Leitung das Wasserventil</P>
";
CM_ BO_ 948 "<P>ACHTUNG: Alle Signale, die im E60 und in der PL2 nicht vom Powermanagement zur Verfügung gestellt werden können, werden mit der Ungültigkeitskennung gesendet.
Es handelt sich um die Signale Status_Batteriehauptschalter, Status_Schalter_Distribution, Status_Heizung_Heckscheibe, Status_Verbraucher_Abschaltung, Status_Abschaltung_Klemme_30, Shutdown_Zähler_Batteriehauptschalter und Zeit_Sekunde_Zähler_Relativ_Redundant.</P>
";
CM_ BO_ 947 "<P>Diese Nachricht enthält einige Informationen der bisherigen Nachricht Powermanagement Batteriespannung. Das Signal Steuerung_Standverbraucher ist eine 1:1-Abbildung des bekannten Signals Status_Standverbraucher. Das Signal Steuerung_Leistung_Verbraucher soll zukünftig die beiden bekannten Signale Steuerung_Spitzenreduzierung_Priorität und Steuerung_Spitzenreduzierung_Priorität_Komfort ersetzen.
Alle, die Gleichteile zum E65 haben, können weiterhin die genannten Signale aus der Nachricht Powermanagement";
CM_ BO_ 944 "<P>Diese Nachricht wird nur bei E60 mit Handschalter versendet! Enthält den aktuellen Status Rückwärtsgang eingelegt / nicht eingelegt.</P>
";
CM_ BO_ 924 "<P>Mit dieser speziellen Nachricht wird jeder Teilnehmer in den sogenannten EBA-Modus versetzt. Zur Zeit verwendet das MMI-GT diese Nachricht immer dann, wenn der Benutzer den elektronischen Bedienassistenten (EBA) im Bordmonitor aktiviert bzw. deaktiviert.</P>
";
CM_ BO_ 917 "<P>Diese Nachricht dient dazu, dem Powermanagement fahrzeugspezifische Daten bzgl. Batterieklasse, Ruhestrom und Kurzschlußstrom zu senden. Die Daten sind abhängig von der Fahrzeugausstattung und sind im CAS codiert.</P>
";
CM_ BO_ 910 "<P>Hinweis: Die Aufstartzeit der DME liegt zwischen 0 und 300 ms.</P>
";
CM_ BO_ 897 "<P>Diese Nachricht übermittelt den Ölstand von der DME an das Kombi. Dort werden diese Informationen dann angezeigt. Die Versendung dieser Nachricht erfolgt nur auf Anfrage.

Bisher nur entschieden für die PL2</P>
";
CM_ BO_ 896 "<P>Diese Nachricht enthält die letzten sieben Stellen der Fahrgestellnummer, jede Stelle einzeln innerhalb eines 8-Bit-Signals in ASCII-Zeichen codiert.
Beispiel:
Fahrgestellnummer: WBAGL41000HB01108 (die letzten sieben Stellen: HB01108)
Signal Nummer_Fahrgestell_1: H (siebtletzte Stelle der Fahrgestellnummer)
Signal Nummer_Fahrgestell_2: B (sechstletzte Stelle der Fahrgestellnummer)
...
Signal Nummer_Fahrgestell_6: 0 (vorletzte Stelle der Fahrgestellnummer)
Signal Nummer_Fahrgestell_7: 8 (letzte St";
CM_ BO_ 886 "<P>Reibarbeit der Lamelle der naßlaufenden Lamellenkupplung (DXC)</P>
";
CM_ BO_ 884 "<P>Wird beim E6x nicht auf dem F-CAN gesendet.</P>
";
CM_ BO_ 847 "<P>Diese Nachricht übermittelt den Zustand des Handbremskontaktes an das Kombi</P>
";
CM_ BO_ 846 "<P>Diese Nachricht enthält allgemeine Navigations-System-Informationen. Zum Beispiel, seit wann das NAVI-Steuergerät in Betrieb ist, welche Software-/Hardware-/Karten-Version verwendet wird und welche Ländercodierung aktuell eingestellt ist.

Aktiv- und Sendebedingungen müssen noch kontrolliert werden!</P>
";
CM_ BO_ 844 "<P>Aktiv- und Sendebedingungen müssen noch kontrolliert werden!</P>
";
CM_ BO_ 842 "<P>Nachricht für die Funktionalität ACC+NAVI Kopplung: Die Nachricht enthält die durch GPS übermittelte absolute horizontale und vertikale Position des Fahrzeugs.

Aktiv- und Sendebedingungen müssen noch festgelegt werden!</P>
";
CM_ BO_ 840 "<P>Diese Nachricht enthält Informationen über die relative Position des Fahrzeugs innerhalb des berechneten NAV_GRAPHen.

Aktiv- und Sendebedingungen müssen noch kontrolliert werden!</P>
";
CM_ BO_ 821 "<P>Statusrückmeldung der geregelten elektronischen Kraftstoffpumpe.

Statusrückmeldung der geregelten elektronischen Kraftstoffpumpe (für M56 mit MS45 und S54 mit MSS54HP im E85) (von Nachricht Status EKP)</P>
";
CM_ BO_ 820 "<P>Diese Nachricht dient zur Ansteuerung der Ausgangsspanung des Generators.

ACHTUNG: Diese Nachricht wird im E60 nicht versendet!</P>
";
CM_ BO_ 818 "<P>Hinweis: Die Aufstartzeit der DME liegt zwischen 0 und 300 ms.</P>
";
CM_ BO_ 806 "<P>Hinweis E60: Das EDCK-Modul wird AUSSCHLIESSLICH von der M-GmbH (Motorsport) eingesetzt!</P>
";
CM_ BO_ 797 "<P>Hinweis: Diese Nachricht wird vom DSC bzw. CIM nur dann verschickt, wenn RPA bzw. DWS auch aktiv codiert ist (kein RDC verbaut ist).</P>
";
CM_ BO_ 794 "<P>Übermittelt den Befehl zur De/Aktivierung an das DXC</P>
";
CM_ BO_ 793 "<P>Übermittlung des Bedienungssignals vom Taster an das RDC - Steuergerät</P>
";
CM_ BO_ 789 "<P>In dieser Nachricht wird der aktuell eingestellte Fahrzeugmodus übertragen. Aktuell gibt es den Komfort- und den Sportmodus. Als Defaultmodus gilt der Komfortmodus. Ab Klemme 15 AUS wird der Modus auf den Defaultmodus zurückgesetzt.

14.03.2003
Momentan nicht verwendet in der PL2</P>
";
CM_ BO_ 785 "<P>Diese Nachricht ist nur für die DDE relevant!</P>
";
CM_ BO_ 764 "<P>Diese Nachricht wird nur vom CAS auf den K-CAN System gelegt. Allerdings stammen einige der darin enthaltenen Informationen (Tür- und Heckklappenkontakt) von Teilnehmern auf dem Peripherie-CAN. Daher sind diese Steuergeräte auch als Sender der Nachricht aufgeführt.</P>
";
CM_ BO_ 760 "<P>Falls die Uhrzeit nach einem Power-Up des Kombis nicht gestellt wird, läuft sie auch nicht von alleine los. In diesem Fall stehen die Signale  Anzeige_Stunde, Anzeige_Minute und Anzeige_Sekunde im E65 auf \"Signal ungültig\", im E60 und der PL2 hingegen auf \"--\". Dieser Zustand wird durch das Signal Status_Anzeige_Uhrzeit_Datum mit der Codierung \"Daten nicht gültig\" (---0b) angezeigt.

Analog zur Vorgehensweise bei der Uhrzeit wird beim E65 - bei nicht gestelltem Datum - in den entsprechenden Datums-Sig";
CM_ BO_ 634 "<P>Aktiv- und Sendebedingungen müssen noch kontrolliert werden!</P>
";
CM_ BO_ 632 "<P>Aktiv- und Sendebedingungen müssen noch kontrolliert werden!</P>
";
CM_ BO_ 512 "<P>Diese Nachricht wird nur versandt, wenn kein ACC erkannt wurde.

HINWEISE:
- Laufzeitverhalten und Ablauf der Benutzersteuerung müssen noch bewertet werden!
- Die Aufstartzeit der DME liegt zwischen 0 und 300 ms.</P>
";
CM_ BO_ 508 "<P>Die Nachricht enthält AFS-Statussignale sowie den Alive-Zähler für die Überwachung des AFS durch das Kombi.</P>
";
CM_ BO_ 507 "<P>Diese Nachricht zeigt den aktuellen Status des EPS an und übermittelt den Alive - Zähler</P>
";
CM_ BO_ 502 "<P>Wenn bei Klemme 30 geblinkt werden soll, dann überprüft das LM folgende Bedingungen:
- Gibt es zur Zeit keinen Anhänger (Signal Status_Anhänger, Nachricht Status Anhänger) am Fahrzeug?
- Ist das Fahrzeug gesichert (Signal Status_Zentralverriegelung, Nachricht ZV und Klappenzustand)?
Wenn diese Bedingungen erfüllt sind, wird von dem Fall ausgegangen, daß der Fahrer das Fahrzeug verlassen hat um beispielsweise Hilfe zu holen. Um Strom zu sparen, wird das zyklische Senden am Bus eingestellt. Die Auswirk";
CM_ BO_ 466 "<P>EGS: Die Nachricht wird bei Ubatt größer 7V gesendet. Das Versenden beginnt spätestens 100 ms nach Aktivierung des Busses, d.h. nach \"High-Signal\" auf der Weckleitung.</P>
";
CM_ BO_ 464 "<P>Hinweis: Die Aufstartzeit der DME liegt zwischen 0 und 300 ms.</P>
";
CM_ BO_ 438 "<P>Diese Nachricht wird sowohl von der DME1 als auch von der DDE1 versandt.

Hinweis: Die Aufstartzeit der DME liegt zwischen 0 und 300 ms.</P>
";
CM_ BO_ 437 "<P>Diese Nachricht wird sowohl von der DME1 als auch von der DDE1 empfangen.</P>
";
CM_ BO_ 428 "<P>Diese Nachricht wird vom DSC-Modul ausgewertet.</P>
";
CM_ BO_ 422 "<P>DSC_CT:
Zugrunde gelegt wird für die Berechnung ein konstanter fahrzeugunabhängiger Abrollumfang der Räder.</P>
";
CM_ BO_ 419 "<P>In dieser Nachricht werden Rohdaten vom Längsbeschleunigungssensor übertragen.

Diese Nachricht wird AUSSCHLIESSLICH in M-Fahrzeugen genutzt!</P>
";
CM_ BO_ 418 "<P>03.08.2001: Diese Nachricht ist für die DDE und DME relevant!

EGS: Die Nachricht wird bei Ubatt größer 7V gesendet. Das Versenden beginnt spätestens 100 ms nach Aktivierung des Busses, d.h. nach \"High-Signal\" auf der Weckleitung.</P>
";
CM_ BO_ 412 "<P>Die Challenge/Response-Nachrichten zwischen DME1 und CAS finden beim E65 zunächst keine Verwendung, da sie erst ab EWS-Stufe 4 benötigt werden.</P>
";
CM_ BO_ 402 "<P>EGS: Nachricht ist nur für EGS_EL relevant.</P>
";
CM_ BO_ 372 "<P>Die Challenge/Response-Nachrichten zwischen DME1 und CAS finden beim E65 zunächst keine Verwendung, da sie erst ab EWS-Stufe 4 benötigt werden.</P>
";
CM_ BO_ 309 "<P>Diese Nachricht dient der Crashabschaltung der EKP sowie der Abschaltung des Generators.</P>
";
CM_ BO_ 203 "<P>Diese Nachricht ist die Antwort des Gierratensensors auf eine Anfrage des DSC-Moduls (E6x: DSC-Moduls/AFS) und enthält ausschließlich Informationen, die nur vom DSC (E6x: DSC/AFS) verwertet werden können.


Diese Nachricht wird im E6x/E81/E82/E87/E9x nicht auf dem PT-CAN versendet, sondern nur auf dem LoCanFahrwerk ( F-CAN ). Im E6x wird diese Nachricht nur in den Fahrzeugen mit AFS versandt.</P>
";
CM_ BO_ 202 "<P>Diese Nachricht enthält variable Daten vom DSC (E6x: DSC/AFS) zur Abfrage des Gierratensensors. Solche Abfragen dürfen ausschließlich vom DSC (E6x: DSC/AFS) durchgeführt werden. Der Versuch einer Abfrage durch ein anderes System wird von der DSC-Sicherheitsschaltung erkannt und führt zur sofortigen Systemabschaltung.

Diese Nachricht wird im E6x/E81/E82/E87/E9x nicht auf dem PT-CAN versendet, sondern nur auf dem LoCanFahrwerk ( F-CAN ). Im E6x wird diese Nachricht nur in den Fahrzeugen mit AFS versand";
CM_ BO_ 200 "<P>Diese Nachricht enthält den oberen Lenkradwinkel. Bei AFS-Verbau entspricht dies nicht der Räderstellung, bei Nicht-AFS-Verbau ist die Räderstellung (der untere Lenkradwinkel) gleich dem oberen Lenkradwinkel.</P>
";
CM_ BO_ 189 "<P>Die Nachricht wird bei Ubatt grösser 6V gesendet.
Kein Remote-Betrieb, keine Phasenbeziehung zu einer anderen Nachricht.
Die Latenzzeit (Alter der Signale in der Nachricht) ist kleiner 5 ms.
Das Versenden beginnt spätestens 140 ms nach Aktivierung des Busses, d.h. nach 'High-Signal' auf der Weckleitung. Empfangende Steuergeräte müssen schon nach 50 ms empfangsbereit sein.</P>
";
CM_ BO_ 186 "<P>EGS: Die Nachricht wird bei Ubatt größer 7V gesendet. Das Versenden beginnt spätestens 100 ms nach Aktivierung des Busses, d.h. nach \"High-Signal\" auf der Weckleitung.</P>
";
CM_ BO_ 185 "<P>Die Nachricht wird bei Ubatt grösser 6V gesendet.
Kein Remote-Betrieb, keine Phasenbeziehung zu einer anderen Nachricht.
Die Latenzzeit (Alter der Signale in der Nachricht) ist kleiner 5 ms.
Das Versenden beginnt spätestens 140 ms nach Aktivierung des Busses, d.h. nach 'High-Signal' auf der Weckleitung. Empfangende Steuergeräte müssen schon nach 50 ms empfangsbereit sein.</P>
";
CM_ BO_ 183 "<P>Die Nachricht wird bei Ubatt grösser 6V gesendet.
Kein Remote-Betrieb, keine Phasenbeziehung zu einer anderen Nachricht.
Die Latenzzeit (Alter der Signale in der Nachricht) ist kleiner 5 ms.
Das Versenden beginnt spätestens 140 ms nach Aktivierung des Busses, d.h. nach 'High-Signal' auf der Weckleitung. Empfangende Steuergeräte müssen schon nach 50 ms empfangsbereit sein.</P>
";
CM_ SG_ 183 TORQ_TAR_ADJR_POS_ACC "Drehmoment_Soll_Verstellbereich_Positiv_ACC
Bei inaktivem Eingriff wird der Fehlerwert 800h übertragen. Ist der Eingriff hingegen aktiv, 
so wird der Wert der Anforderung (= Drehmoment_Soll_ACC) übertragen";
CM_ SG_ 183 TORQ_TAR_ACC "Drehmoment_Soll_ACC
Hier wird das angeforderte Drehmoment übertragen. Wenn keine Momentenanforderung vorliegt, wird zur Sicherheit 
der Fehlerwert (Signal ungültig) übertragen. Bei inaktivem Eingriff wird der Fehlerwert 800h übertragen.
";
CM_ SG_ 183 ST_TORQ_TAR_ACC "Status_Drehmoment_Soll_ACC
Mit diesem Signal wird die Momentenanforderung freigegeben.

00 Keine Momentenanforderung
01 Momentenerhöhung
10 Momentenerniedrigung
11 Signal ungültig

";
CM_ SG_ 183 ST_ACC_SWO_SYS_DME "Status_ACC_Abschaltung_System_DME 
Hier wird übertragen, ob das System in Ordnung ist oder ob ein Fehler erkannt wurde, der zu einer Abschaltung des Gesamtsystems führt

00 Reserviert
01 Systemabschaltung
10 System in Ordnung
11 Signal ungültig

";
CM_ SG_ 183 ST_ACC_MOD_DME "Status_ACC_Modus_DME 
akt Regelstate des ACC Nicht  in der DME zur Plausibilisierung
000 Passiv
001 Stand by
010 Normal
011 Erhöhte Dynamik
100 Bremse aktiv
101 Fahrer übertreten
110 Reserve (gültiger ACC-Aktivzustand)
111 Signal ungültig";
CM_ SG_ 183 RQ_PREV_INFS_ACC "Anforderung_Verhinderung_Schubabschaltung_ACC 
Mit diesem Signal erfolgt eine Anforderung an die Motorsteuerung zur Verhinderung der Schubabschaltung
00 Keine Anforderung
01 Schubabschaltung verhindern
11 Signal ungültig
";
CM_ SG_ 183 CHKSM_TORQ_ACC "Checksumme Standardabsicherung";
CM_ SG_ 183 ALIV_TORQ_ACC "Alivecounter Standardabsicherung";
CM_ BO_ 182 "<P>Die Nachricht wird bei Ubatt grösser 6V gesendet.
Kein Remote-Betrieb, keine Phasenbeziehung zu einer anderen Nachricht.
Die Latenzzeit (Alter der Signale in der Nachricht) ist kleiner 5 ms.
Das Versenden beginnt spätestens 140 ms nach Aktivierung des Busses, d.h. nach 'High-Signal' auf der Weckleitung. Empfangende Steuergeräte müssen schon nach 50 ms empfangsbereit sein.</P>
";
CM_ BO_ 181 "<P>Die Nachricht wird bei Ubatt grösser 6V gesendet.
Kein Remote-Betrieb, keine Phasenbeziehung zu einer anderen Nachricht.
Die Latenzzeit (Alter der Signale in der Nachricht) ist kleiner 5 ms.
Das Versenden beginnt spätestens 140 ms nach Aktivierung des Busses, d.h. nach 'High-Signal' auf der Weckleitung. Empfangende Steuergeräte müssen schon nach 50 ms empfangsbereit sein.</P>
";
CM_ BO_ 179 "<P>Die Nachricht dient der Steuerung des Servotronic-Ventils sowie der geregelten Lenkhilfepumpe durch externe Steuergeräte.</P>
";
CM_ BO_ 174 "<P>Keine E60-Nachricht!</P>
";
CM_ BO_ 170 "<P>Hinweis: Die Aufstartzeit der DME liegt zwischen 0 und 300 ms.</P>
";
CM_ SG_ 170 TORQ_DVCH "Drehmoment_Fahrerwunsch 
Dieses Signal enthält - entsprechend dem Betriebspunkt des Motors - das aktuelle Fahrerwunschmoment";
CM_ SG_ 170 ST_CLCTR_V "Status_Regelung_Geschwindigkeit 
0000 ACC, PWG nicht getr
0001 ACC, PWG getr
0100 FGR Verzög
0101 FGR Konstantft
0110 FGR Wiederaufn
0111 FGR Beschl
1000 Keine ACC PWG nicht getr
1001 Keine ACC PWG getr
1010 ACC, PWG übertr
1011 PWG Kickdown
 ";
CM_ SG_ 170 ANG_ACPD "Winkel_Fahrpedal 
In diesem Signal wird - abhängig vom Inhalt des Signals Status_Regelung_Geschwindigkeit - entweder der 
aktuelle Wert des Pedalwertgebers (= realer Fahrpedalwinkel) oder der virtuelle Fahrpedalwinkel übertragen";
CM_ BO_ 169 "<P>Hinweis: Die Aufstartzeit der DME liegt zwischen 0 und 300 ms.</P>
";
CM_ BO_ 168 "<P>Hinweis: Die Aufstartzeit der DME liegt zwischen 0 und 300 ms.</P>
";
CM_ SG_ 168 TORQ_AVL_DMEE "Kurbelwellenmoment ohne EGS-Eingriff";
CM_ SG_ 168 TORQ_AVL "Drehmoment_Ist 
aktuelles Kurbelwellenmoment";
CM_ SG_ 168 ST_TORQ_AVL "Wie wird der Einfiffswunsch ausgeführt
0: Eingriffswunsch wird ausgeführt
1: Eingriffswunsch über Zündung kann nicht ausgefüllt werden
2: Eingriffswunsch über Füllung kann nicht ausgeführt werden
3: Notlauf des V-Motors
15: Signal ungültig";
CM_ SG_ 168 ST_SW_CLT "Status Kupplungsschalter
0: Kupplung nicht betätigt
1: Kupplung betätigt
3: Signal ungültig";
CM_ SG_ 168 ST_RTIR "Drehungleichförmigkeit

0: keine Unförmigkeit
1: Drehungleichförmigkeit durch Injektorausfall
2: Drehungleichförmigkeit ohne Injektorausfal
3: ungültig";
CM_ SG_ 168 ST_RCPT_ENG_EGS "Quttierung EGS Fehlererkennung

0: In Ordnung
1: Plausibilitäts-/Aktivitätsfehler
2 Timeout
3: ungültig";
CM_ SG_ 168 ST_RCPT_ENG_DSC "Quittierung DSC Fehlererkennung

0: In Ordnung
1: Plausibilitäts-/Aktivitätsfehler
2 Timeout
3: ungültig";
CM_ SG_ 168 ST_RCPT_ENG_ARS "Fehlererkennung

0: In Ordnung
1: Plausibilitäts-/Aktivitätsfehler
2 Timeout
3: ungültig";
CM_ SG_ 168 ST_RCPT_ENG_ACC "Plausibilitäts- und Aktivierungsfehler ACC (irreversible im Fahrzyklus)

0:In Ordnung
1: Fehler
3: ungültig";
CM_ SG_ 168 ST_OBD_CTFN_GRB "Status_OBD_Steuerfunktion_Getriebe 
";
CM_ SG_ 168 ST_DMEA_SWO "Status_DME/ACC_Abschaltung 
Abschaltung auf Grund eines motorinternen Fehlers.  (Quittierung durch das ACC-Modul)

00 In Ordnung
01 Abschaltung wegen Fehler
10 Reserve
11 Signal ungültig
";
CM_ SG_ 168 ST_CT_BRPD_DME "Bremslichtschalter

000 keine Bremse betätigt
0-1 Bremslichtschalter 1 betätigt
01- Bremslichtschalter 2 betätigt";
CM_ SG_ 168 RCPT_ACC_SWO_SYS_DME "Quitieren der ACC-Systemabschaltung

0: keine Abschaltung
1: Systemabschaltung erkannt
3 ungültig";
CM_ SG_ 168 CHKSM_TORQ_1_DME "Checksumme Standardabsicherung";
CM_ SG_ 168 ALIV_TORQ_1_DME "AliveCounter 0-14";
BA_DEF_  "BusType" STRING ;
BA_DEF_ BU_  "<NET-NODE><LONG-NAME>" STRING ;
BA_DEF_ BU_  "MCV-Nummer" STRING ;
BA_DEF_ SG_  "<NET-SIGNAL><INIT-VALUE>" STRING ;
BA_DEF_ SG_  "<NET-SIGNAL><LONG-NAME>" STRING ;
BA_DEF_ BO_  "<NET-MESSAGE><LONG-NAME>" STRING ;
BA_DEF_ BO_  "<POWERUP-RECEIVE-TIME>" STRING ;
BA_DEF_ BO_  "<POWERUP-RECEIVE-TIME><PC>" STRING ;
BA_DEF_ BO_  "<POWERUP-TRANSMIT-TIME>" STRING ;
BA_DEF_ BO_  "<POWERUP-TRANSMIT-TIME><PC>" STRING ;
BA_DEF_ BO_  "<POWERDOWN-RECEIVE-TIME>" STRING ;
BA_DEF_ BO_  "<POWERDOWN-RECEIVE-TIME><PC>" STRING ;
BA_DEF_ BO_  "<LATENCY-TIME>" STRING ;
BA_DEF_ BO_  "<LATENCY-TIME><PC>" STRING ;
BA_DEF_ BO_  "<CYCLE-TIME>" STRING ;
BA_DEF_ BO_  "<CYCLE-TIME><PC>" STRING ;
BA_DEF_ BO_  "<PHASE-RELATIONS>" STRING ;
BA_DEF_ BO_  "<PHASE-RELATIONS><PC>" STRING ;
BA_DEF_ BO_  "GenMsgSendType" ENUM  "Zyklisch ","Ereignisgesteuert ","dummy ","ZyklischImmer";
BA_DEF_ BO_  "GenMsgStartDelayTime" INT 0 1000000;
BA_DEF_ BO_  "GenMsgDelayTime" INT 0 1000000;
BA_DEF_ BO_  "GenMsgCycleTime" INT 0 1000000;
BA_DEF_ BO_  "AddRemark" STRING ;
BA_DEF_ BO_  "GenMsgSendType2" ENUM  "Zyklisch ","Ereignisgesteuert ","dummy ","ZyklischImmer";
BA_DEF_ BO_  "GenMsgStartDelayTime2" INT 0 1000000;
BA_DEF_ BO_  "GenMsgCycleTime2" INT 0 1000000;
BA_DEF_ BO_  "GenMsgDelayTime2" INT 0 1000000;
BA_DEF_ BO_  "AddRemark2" STRING ;
BA_DEF_ BO_  "GenMsgSendType3" ENUM  "Zyklisch ","Ereignisgesteuert ","dummy ","ZyklischImmer";
BA_DEF_ BO_  "GenMsgStartDelayTime3" INT 0 1000000;
BA_DEF_ BO_  "GenMsgCycleTime3" INT 0 1000000;
BA_DEF_ BO_  "GenMsgDelayTime3" INT 0 1000000;
BA_DEF_ BO_  "AddRemark3" STRING ;
BA_DEF_ BO_  "GenMsgSendType4" ENUM  "Zyklisch ","Ereignisgesteuert ","dummy ","ZyklischImmer";
BA_DEF_ BO_  "GenMsgStartDelayTime4" INT 0 1000000;
BA_DEF_ BO_  "GenMsgCycleTime4" INT 0 1000000;
BA_DEF_ BO_  "GenMsgDelayTime4" INT 0 1000000;
BA_DEF_ BO_  "AddRemark4" STRING ;
BA_DEF_ BO_  "DiagResponse" ENUM  "No","Yes";
BA_DEF_ BO_  "DiagRequest" ENUM  "No","Yes";
BA_DEF_ BU_  "NodeLayerModules" STRING ;
BA_DEF_ BU_  "MessageManagerUsed" ENUM  "No","Yes";
BA_DEF_ BU_  "DiagnoseStationsAdresse" HEX 0 255;
BA_DEF_  "Manufacturer" STRING ;
BA_DEF_ BO_  "RequestMessage" ENUM  "No","Yes";
BA_DEF_  "Manufacturer_ALT" ENUM  "DBAG","VAG","BMWAG","PAG","GM";
BA_DEF_ BO_  "NWM-Botschaft" ENUM  "No","Yes";
BA_DEF_ BU_  "NWM-Knoten" ENUM  "No","Yes";
BA_DEF_ BU_  "NWM-Stationsadresse" HEX 0 127;
BA_DEF_  "NWM-Typ" ENUM  "zentral","dezentral","keines","vagnm","bmwnm";
BA_DEF_  "NWM-Basisadresse" HEX 1152 1152;
BA_DEF_  "NWM_Basisadresse" HEX 1152 1152;
BA_DEF_ BU_  "NWM_Stationsadresse" INT 0 127;
BA_DEF_DEF_  "BusType" "";
BA_DEF_DEF_  "<NET-NODE><LONG-NAME>" "";
BA_DEF_DEF_  "MCV-Nummer" "";
BA_DEF_DEF_  "<NET-SIGNAL><INIT-VALUE>" "";
BA_DEF_DEF_  "<NET-SIGNAL><LONG-NAME>" "";
BA_DEF_DEF_  "<NET-MESSAGE><LONG-NAME>" "";
BA_DEF_DEF_  "<POWERUP-RECEIVE-TIME>" "";
BA_DEF_DEF_  "<POWERUP-RECEIVE-TIME><PC>" "";
BA_DEF_DEF_  "<POWERUP-TRANSMIT-TIME>" "";
BA_DEF_DEF_  "<POWERUP-TRANSMIT-TIME><PC>" "";
BA_DEF_DEF_  "<POWERDOWN-RECEIVE-TIME>" "";
BA_DEF_DEF_  "<POWERDOWN-RECEIVE-TIME><PC>" "";
BA_DEF_DEF_  "<LATENCY-TIME>" "";
BA_DEF_DEF_  "<LATENCY-TIME><PC>" "";
BA_DEF_DEF_  "<CYCLE-TIME>" "";
BA_DEF_DEF_  "<CYCLE-TIME><PC>" "";
BA_DEF_DEF_  "<PHASE-RELATIONS>" "";
BA_DEF_DEF_  "<PHASE-RELATIONS><PC>" "";
BA_DEF_DEF_  "GenMsgSendType" "";
BA_DEF_DEF_  "GenMsgStartDelayTime" 0;
BA_DEF_DEF_  "GenMsgDelayTime" 0;
BA_DEF_DEF_  "GenMsgCycleTime" 0;
BA_DEF_DEF_  "AddRemark" "";
BA_DEF_DEF_  "GenMsgSendType2" "";
BA_DEF_DEF_  "GenMsgStartDelayTime2" 0;
BA_DEF_DEF_  "GenMsgCycleTime2" 0;
BA_DEF_DEF_  "GenMsgDelayTime2" 0;
BA_DEF_DEF_  "AddRemark2" "";
BA_DEF_DEF_  "GenMsgSendType3" "";
BA_DEF_DEF_  "GenMsgStartDelayTime3" 0;
BA_DEF_DEF_  "GenMsgCycleTime3" 0;
BA_DEF_DEF_  "GenMsgDelayTime3" 0;
BA_DEF_DEF_  "AddRemark3" "";
BA_DEF_DEF_  "GenMsgSendType4" "";
BA_DEF_DEF_  "GenMsgStartDelayTime4" 0;
BA_DEF_DEF_  "GenMsgCycleTime4" 0;
BA_DEF_DEF_  "GenMsgDelayTime4" 0;
BA_DEF_DEF_  "AddRemark4" "";
BA_DEF_DEF_  "DiagResponse" "No";
BA_DEF_DEF_  "DiagRequest" "No";
BA_DEF_DEF_  "NodeLayerModules" "bmwnm03.dll";
BA_DEF_DEF_  "MessageManagerUsed" "No";
BA_DEF_DEF_  "DiagnoseStationsAdresse" 0;
BA_DEF_DEF_  "Manufacturer" "BMWAG";
BA_DEF_DEF_  "RequestMessage" "No";
BA_DEF_DEF_  "Manufacturer_ALT" "BMWAG";
BA_DEF_DEF_  "NWM-Botschaft" "No";
BA_DEF_DEF_  "NWM-Knoten" "Yes";
BA_DEF_DEF_  "NWM-Stationsadresse" 0;
BA_DEF_DEF_  "NWM-Typ" "bmwnm";
BA_DEF_DEF_  "NWM-Basisadresse" 1152;
BA_DEF_DEF_  "NWM_Basisadresse" 1152;
BA_DEF_DEF_  "NWM_Stationsadresse" 0;
BA_ "BusType" "CAN";
BA_ "MCV-Nummer" BU_ dummy "DummyMCV";
BA_ "<NET-NODE><LONG-NAME>" BU_ dummy "dummy";
BA_ "MCV-Nummer" BU_ ZBE "0";
BA_ "<NET-NODE><LONG-NAME>" BU_ ZBE "ZBE";
BA_ "MCV-Nummer" BU_ VVT1 "2590";
BA_ "<NET-NODE><LONG-NAME>" BU_ VVT1 "VVT1";
BA_ "NWM_Stationsadresse" BU_ VGSG 25;
BA_ "NWM-Stationsadresse" BU_ VGSG 25;
BA_ "DiagnoseStationsAdresse" BU_ VGSG 25;
BA_ "MCV-Nummer" BU_ VGSG "3120";
BA_ "<NET-NODE><LONG-NAME>" BU_ VGSG "VGSG";
BA_ "MessageManagerUsed" BU_ VGSG 1;
BA_ "MCV-Nummer" BU_ SZL_LWS "3112";
BA_ "<NET-NODE><LONG-NAME>" BU_ SZL_LWS "SZL_LWS";
BA_ "MCV-Nummer" BU_ SM_FA "3118";
BA_ "<NET-NODE><LONG-NAME>" BU_ SM_FA "SM_FA";
BA_ "MCV-Nummer" BU_ SM_BF "3117";
BA_ "<NET-NODE><LONG-NAME>" BU_ SM_BF "SM_BF";
BA_ "MCV-Nummer" BU_ SHD "0";
BA_ "<NET-NODE><LONG-NAME>" BU_ SHD "SHD";
BA_ "MCV-Nummer" BU_ RDC "3110";
BA_ "<NET-NODE><LONG-NAME>" BU_ RDC "RDC";
BA_ "MCV-Nummer" BU_ PGS "3102";
BA_ "<NET-NODE><LONG-NAME>" BU_ PGS "PGS";
BA_ "MCV-Nummer" BU_ PDC "3101";
BA_ "<NET-NODE><LONG-NAME>" BU_ PDC "PDC";
BA_ "MCV-Nummer" BU_ MRSZ "3123";
BA_ "<NET-NODE><LONG-NAME>" BU_ MRSZ "MRSZ";
BA_ "NWM_Stationsadresse" BU_ LDM 28;
BA_ "NWM-Stationsadresse" BU_ LDM 28;
BA_ "DiagnoseStationsAdresse" BU_ LDM 28;
BA_ "MCV-Nummer" BU_ LDM "3087";
BA_ "<NET-NODE><LONG-NAME>" BU_ LDM "LDM";
BA_ "MessageManagerUsed" BU_ LDM 1;
BA_ "MCV-Nummer" BU_ Kombi "3085";
BA_ "<NET-NODE><LONG-NAME>" BU_ Kombi "Kombi";
BA_ "MCV-Nummer" BU_ JBBF "3084";
BA_ "<NET-NODE><LONG-NAME>" BU_ JBBF "JBBF";
BA_ "MessageManagerUsed" BU_ JBBF 1;
BA_ "MCV-Nummer" BU_ IHx "0";
BA_ "<NET-NODE><LONG-NAME>" BU_ IHx "IHx";
BA_ "MCV-Nummer" BU_ FZD "3075";
BA_ "<NET-NODE><LONG-NAME>" BU_ FZD "FZD";
BA_ "NWM_Stationsadresse" BU_ FRMFA_ALC 114;
BA_ "NWM-Stationsadresse" BU_ FRMFA_ALC 114;
BA_ "DiagnoseStationsAdresse" BU_ FRMFA_ALC 114;
BA_ "MessageManagerUsed" BU_ FRMFA_ALC 1;
BA_ "MCV-Nummer" BU_ FRMFA_ALC "3077";
BA_ "<NET-NODE><LONG-NAME>" BU_ FRMFA_ALC "FRMFA_ALC";
BA_ "MCV-Nummer" BU_ FRMFA "3076";
BA_ "<NET-NODE><LONG-NAME>" BU_ FRMFA "FRMFA";
BA_ "NWM_Stationsadresse" BU_ FFP 29;
BA_ "NWM-Stationsadresse" BU_ FFP 29;
BA_ "DiagnoseStationsAdresse" BU_ FFP 29;
BA_ "MCV-Nummer" BU_ FFP "3074";
BA_ "<NET-NODE><LONG-NAME>" BU_ FFP "FFP";
BA_ "MessageManagerUsed" BU_ FFP 1;
BA_ "MessageManagerUsed" BU_ EPS 1;
BA_ "<NET-NODE><LONG-NAME>" BU_ EPS "EPS";
BA_ "MCV-Nummer" BU_ EPS "3071";
BA_ "DiagnoseStationsAdresse" BU_ EPS 48;
BA_ "NWM-Stationsadresse" BU_ EPS 48;
BA_ "NWM_Stationsadresse" BU_ EPS 48;
BA_ "MessageManagerUsed" BU_ EKP 1;
BA_ "<NET-NODE><LONG-NAME>" BU_ EKP "EKP";
BA_ "MCV-Nummer" BU_ EKP "3072";
BA_ "DiagnoseStationsAdresse" BU_ EKP 23;
BA_ "NWM-Stationsadresse" BU_ EKP 23;
BA_ "NWM_Stationsadresse" BU_ EKP 23;
BA_ "MCV-Nummer" BU_ EHC "3086";
BA_ "<NET-NODE><LONG-NAME>" BU_ EHC "EHC";
BA_ "NWM_Stationsadresse" BU_ EGS_SSG 24;
BA_ "NWM-Stationsadresse" BU_ EGS_SSG 24;
BA_ "DiagnoseStationsAdresse" BU_ EGS_SSG 24;
BA_ "MCV-Nummer" BU_ EGS_SSG "0";
BA_ "<NET-NODE><LONG-NAME>" BU_ EGS_SSG "ESG_SSG";
BA_ "MessageManagerUsed" BU_ EGS_SSG 1;
BA_ "MCV-Nummer" BU_ Diagnosetool_PT_CAN "2694";
BA_ "<NET-NODE><LONG-NAME>" BU_ Diagnosetool_PT_CAN "Diagnosetool_PT_CAN";
BA_ "MessageManagerUsed" BU_ Diagnosetool_PT_CAN 1;
BA_ "DiagnoseStationsAdresse" BU_ Diagnosetool_PT_CAN 125;
BA_ "NWM-Stationsadresse" BU_ Diagnosetool_PT_CAN 125;
BA_ "NWM_Stationsadresse" BU_ Diagnosetool_PT_CAN 125;
BA_ "MCV-Nummer" BU_ Diagnosetool_K_CAN_System "3065";
BA_ "<NET-NODE><LONG-NAME>" BU_ Diagnosetool_K_CAN_System "Diagnosetool_K_CAN_System";
BA_ "MCV-Nummer" BU_ DWA "3066";
BA_ "<NET-NODE><LONG-NAME>" BU_ DWA "DWA";
BA_ "NWM_Stationsadresse" BU_ DSC_DXC 41;
BA_ "NWM-Stationsadresse" BU_ DSC_DXC 41;
BA_ "DiagnoseStationsAdresse" BU_ DSC_DXC 41;
BA_ "MCV-Nummer" BU_ DSC_DXC "0";
BA_ "<NET-NODE><LONG-NAME>" BU_ DSC_DXC "DSC_DXC";
BA_ "MessageManagerUsed" BU_ DSC_DXC 1;
BA_ "NWM_Stationsadresse" BU_ DME1_DDE1 18;
BA_ "NWM-Stationsadresse" BU_ DME1_DDE1 18;
BA_ "DiagnoseStationsAdresse" BU_ DME1_DDE1 18;
BA_ "MCV-Nummer" BU_ DME1_DDE1 "0";
BA_ "<NET-NODE><LONG-NAME>" BU_ DME1_DDE1 "DME1_DDE1";
BA_ "MessageManagerUsed" BU_ DME1_DDE1 1;
BA_ "MCV-Nummer" BU_ CVM_V "3058";
BA_ "<NET-NODE><LONG-NAME>" BU_ CVM_V "CVM_V";
BA_ "MCV-Nummer" BU_ CID_V "0";
BA_ "<NET-NODE><LONG-NAME>" BU_ CID_V "CID_V";
BA_ "MCV-Nummer" BU_ CCC_MASK_RAD "0";
BA_ "<NET-NODE><LONG-NAME>" BU_ CCC_MASK_RAD "CCC_MASK_RAD";
BA_ "MCV-Nummer" BU_ CAS "3059";
BA_ "<NET-NODE><LONG-NAME>" BU_ CAS "CAS";
BA_ "MessageManagerUsed" BU_ BMW_Tester1 1;
BA_ "DiagnoseStationsAdresse" BU_ BMW_Tester1 241;
BA_ "MCV-Nummer" BU_ AHM "3054";
BA_ "<NET-NODE><LONG-NAME>" BU_ AHM "AHM";
BA_ "MCV-Nummer" BU_ AFS_RP "2929";
BA_ "<NET-NODE><LONG-NAME>" BU_ AFS_RP "AFS_RP";
BA_ "NWM_Stationsadresse" BU_ AFS 22;
BA_ "NWM-Stationsadresse" BU_ AFS 22;
BA_ "DiagnoseStationsAdresse" BU_ AFS 22;
BA_ "MCV-Nummer" BU_ AFS "3052";
BA_ "<NET-NODE><LONG-NAME>" BU_ AFS "AFS";
BA_ "MessageManagerUsed" BU_ AFS 1;
BA_ "NWM_Stationsadresse" BU_ ACC_Sensor 33;
BA_ "NWM-Stationsadresse" BU_ ACC_Sensor 33;
BA_ "DiagnoseStationsAdresse" BU_ ACC_Sensor 33;
BA_ "MCV-Nummer" BU_ ACC_Sensor "3053";
BA_ "<NET-NODE><LONG-NAME>" BU_ ACC_Sensor "ACC_Sensor";
BA_ "MessageManagerUsed" BU_ ACC_Sensor 1;
BA_ "DiagRequest" BO_ 1777 1;
BA_ "DiagResponse" BO_ 1777 1;
BA_ "DiagResponse" BO_ 1650 1;
BA_ "DiagResponse" BO_ 1584 1;
BA_ "DiagResponse" BO_ 1577 1;
BA_ "DiagResponse" BO_ 1569 1;
BA_ "DiagResponse" BO_ 1565 1;
BA_ "DiagRequest" BO_ 1565 1;
BA_ "DiagRequest" BO_ 1564 1;
BA_ "DiagResponse" BO_ 1564 1;
BA_ "DiagResponse" BO_ 1561 1;
BA_ "DiagResponse" BO_ 1560 1;
BA_ "DiagResponse" BO_ 1559 1;
BA_ "DiagResponse" BO_ 1558 1;
BA_ "DiagResponse" BO_ 1554 1;
BA_ "DiagRequest" BO_ 1536 1;
BA_ "DiagResponse" BO_ 1536 1;
BA_ "GenMsgSendType" BO_ 1504 0;
BA_ "RequestMessage" BO_ 1504 1;
BA_ "RequestMessage" BO_ 1456 1;
BA_ "RequestMessage" BO_ 1449 1;
BA_ "RequestMessage" BO_ 1441 1;
BA_ "RequestMessage" BO_ 1437 1;
BA_ "RequestMessage" BO_ 1436 1;
BA_ "RequestMessage" BO_ 1433 1;
BA_ "RequestMessage" BO_ 1432 1;
BA_ "RequestMessage" BO_ 1431 1;
BA_ "RequestMessage" BO_ 1430 1;
BA_ "RequestMessage" BO_ 1426 1;
BA_ "RequestMessage" BO_ 1408 1;
BA_ "NWM-Botschaft" BO_ 1266 1;
BA_ "NWM-Botschaft" BO_ 1200 1;
BA_ "NWM-Botschaft" BO_ 1193 1;
BA_ "NWM-Botschaft" BO_ 1185 1;
BA_ "NWM-Botschaft" BO_ 1181 1;
BA_ "NWM-Botschaft" BO_ 1180 1;
BA_ "NWM-Botschaft" BO_ 1177 1;
BA_ "NWM-Botschaft" BO_ 1176 1;
BA_ "NWM-Botschaft" BO_ 1175 1;
BA_ "NWM-Botschaft" BO_ 1174 1;
BA_ "NWM-Botschaft" BO_ 1170 1;
BA_ "NWM-Botschaft" BO_ 1152 1;
BA_ "GenMsgDelayTime" BO_ 1003 50;
BA_ "GenMsgSendType" BO_ 1003 1;
BA_ "<PHASE-RELATIONS><PC>" BO_ 1003 "empty";
BA_ "<PHASE-RELATIONS>" BO_ 1003 "empty";
BA_ "<CYCLE-TIME><PC>" BO_ 1003 "empty";
BA_ "<CYCLE-TIME>" BO_ 1003 "empty";
BA_ "<LATENCY-TIME><PC>" BO_ 1003 "empty";
BA_ "<LATENCY-TIME>" BO_ 1003 "empty";
BA_ "<POWERDOWN-RECEIVE-TIME><PC>" BO_ 1003 "empty";
BA_ "<POWERDOWN-RECEIVE-TIME>" BO_ 1003 "empty";
BA_ "<POWERUP-TRANSMIT-TIME><PC>" BO_ 1003 "empty";
BA_ "<POWERUP-TRANSMIT-TIME>" BO_ 1003 "empty";
BA_ "<POWERUP-RECEIVE-TIME><PC>" BO_ 1003 "empty";
BA_ "<POWERUP-RECEIVE-TIME>" BO_ 1003 "empty";
BA_ "GenMsgDelayTime" BO_ 1002 50;
BA_ "GenMsgSendType" BO_ 1002 1;
BA_ "<PHASE-RELATIONS><PC>" BO_ 1002 "empty";
BA_ "<PHASE-RELATIONS>" BO_ 1002 "empty";
BA_ "<CYCLE-TIME><PC>" BO_ 1002 "empty";
BA_ "<CYCLE-TIME>" BO_ 1002 "empty";
BA_ "<LATENCY-TIME><PC>" BO_ 1002 "empty";
BA_ "<LATENCY-TIME>" BO_ 1002 "empty";
BA_ "<POWERDOWN-RECEIVE-TIME><PC>" BO_ 1002 "empty";
BA_ "<POWERDOWN-RECEIVE-TIME>" BO_ 1002 "empty";
BA_ "<POWERUP-TRANSMIT-TIME><PC>" BO_ 1002 "empty";
BA_ "<POWERUP-TRANSMIT-TIME>" BO_ 1002 "empty";
BA_ "<POWERUP-RECEIVE-TIME><PC>" BO_ 1002 "empty";
BA_ "<POWERUP-RECEIVE-TIME>" BO_ 1002 "empty";
BA_ "GenMsgDelayTime" BO_ 1001 50;
BA_ "GenMsgSendType" BO_ 1001 1;
BA_ "<PHASE-RELATIONS><PC>" BO_ 1001 "empty";
BA_ "<PHASE-RELATIONS>" BO_ 1001 "empty";
BA_ "<CYCLE-TIME><PC>" BO_ 1001 "empty";
BA_ "<CYCLE-TIME>" BO_ 1001 "empty";
BA_ "<LATENCY-TIME><PC>" BO_ 1001 "empty";
BA_ "<LATENCY-TIME>" BO_ 1001 "empty";
BA_ "<POWERDOWN-RECEIVE-TIME><PC>" BO_ 1001 "empty";
BA_ "<POWERDOWN-RECEIVE-TIME>" BO_ 1001 "empty";
BA_ "<POWERUP-TRANSMIT-TIME><PC>" BO_ 1001 "empty";
BA_ "<POWERUP-TRANSMIT-TIME>" BO_ 1001 "empty";
BA_ "<POWERUP-RECEIVE-TIME><PC>" BO_ 1001 "empty";
BA_ "<POWERUP-RECEIVE-TIME>" BO_ 1001 "empty";
BA_ "GenMsgDelayTime3" BO_ 987 200;
BA_ "GenMsgSendType3" BO_ 987 1;
BA_ "GenMsgDelayTime2" BO_ 987 200;
BA_ "GenMsgSendType2" BO_ 987 1;
BA_ "GenMsgDelayTime" BO_ 987 50;
BA_ "GenMsgSendType" BO_ 987 1;
BA_ "<PHASE-RELATIONS><PC>" BO_ 987 "empty";
BA_ "<PHASE-RELATIONS>" BO_ 987 "empty";
BA_ "<CYCLE-TIME><PC>" BO_ 987 "empty";
BA_ "<CYCLE-TIME>" BO_ 987 "empty";
BA_ "<LATENCY-TIME><PC>" BO_ 987 "empty";
BA_ "<LATENCY-TIME>" BO_ 987 "empty";
BA_ "<POWERDOWN-RECEIVE-TIME><PC>" BO_ 987 "empty";
BA_ "<POWERDOWN-RECEIVE-TIME>" BO_ 987 "empty";
BA_ "<POWERUP-TRANSMIT-TIME><PC>" BO_ 987 "empty";
BA_ "<POWERUP-TRANSMIT-TIME>" BO_ 987 "empty";
BA_ "<POWERUP-RECEIVE-TIME><PC>" BO_ 987 "empty";
BA_ "<POWERUP-RECEIVE-TIME>" BO_ 987 "empty";
BA_ "GenMsgCycleTime2" BO_ 958 10000;
BA_ "GenMsgSendType2" BO_ 958 0;
BA_ "GenMsgDelayTime" BO_ 958 100;
BA_ "GenMsgSendType" BO_ 958 1;
BA_ "<PHASE-RELATIONS><PC>" BO_ 958 "empty";
BA_ "<PHASE-RELATIONS>" BO_ 958 "empty";
BA_ "<CYCLE-TIME><PC>" BO_ 958 "empty";
BA_ "<CYCLE-TIME>" BO_ 958 "empty";
BA_ "<LATENCY-TIME><PC>" BO_ 958 "empty";
BA_ "<LATENCY-TIME>" BO_ 958 "empty";
BA_ "<POWERDOWN-RECEIVE-TIME><PC>" BO_ 958 "empty";
BA_ "<POWERDOWN-RECEIVE-TIME>" BO_ 958 "empty";
BA_ "<POWERUP-TRANSMIT-TIME><PC>" BO_ 958 "empty";
BA_ "<POWERUP-TRANSMIT-TIME>" BO_ 958 "empty";
BA_ "<POWERUP-RECEIVE-TIME><PC>" BO_ 958 "empty";
BA_ "<POWERUP-RECEIVE-TIME>" BO_ 958 "empty";
BA_ "GenMsgCycleTime3" BO_ 957 5000;
BA_ "GenMsgSendType3" BO_ 957 0;
BA_ "GenMsgDelayTime2" BO_ 957 100;
BA_ "GenMsgSendType2" BO_ 957 1;
BA_ "GenMsgDelayTime" BO_ 957 1000;
BA_ "GenMsgSendType" BO_ 957 1;
BA_ "<PHASE-RELATIONS><PC>" BO_ 957 "empty";
BA_ "<PHASE-RELATIONS>" BO_ 957 "empty";
BA_ "<CYCLE-TIME><PC>" BO_ 957 "empty";
BA_ "<CYCLE-TIME>" BO_ 957 "empty";
BA_ "<LATENCY-TIME><PC>" BO_ 957 "empty";
BA_ "<LATENCY-TIME>" BO_ 957 "empty";
BA_ "<POWERDOWN-RECEIVE-TIME><PC>" BO_ 957 "empty";
BA_ "<POWERDOWN-RECEIVE-TIME>" BO_ 957 "empty";
BA_ "<POWERUP-TRANSMIT-TIME><PC>" BO_ 957 "empty";
BA_ "<POWERUP-TRANSMIT-TIME>" BO_ 957 "empty";
BA_ "<POWERUP-RECEIVE-TIME><PC>" BO_ 957 "empty";
BA_ "<POWERUP-RECEIVE-TIME>" BO_ 957 "empty";
BA_ "GenMsgDelayTime" BO_ 949 50;
BA_ "GenMsgCycleTime" BO_ 949 5000;
BA_ "GenMsgSendType" BO_ 949 0;
BA_ "<PHASE-RELATIONS><PC>" BO_ 949 "empty";
BA_ "<PHASE-RELATIONS>" BO_ 949 "empty";
BA_ "<CYCLE-TIME><PC>" BO_ 949 "empty";
BA_ "<CYCLE-TIME>" BO_ 949 "empty";
BA_ "<LATENCY-TIME><PC>" BO_ 949 "empty";
BA_ "<LATENCY-TIME>" BO_ 949 "empty";
BA_ "<POWERDOWN-RECEIVE-TIME><PC>" BO_ 949 "empty";
BA_ "<POWERDOWN-RECEIVE-TIME>" BO_ 949 "empty";
BA_ "<POWERUP-TRANSMIT-TIME><PC>" BO_ 949 "empty";
BA_ "<POWERUP-TRANSMIT-TIME>" BO_ 949 "empty";
BA_ "<POWERUP-RECEIVE-TIME><PC>" BO_ 949 "empty";
BA_ "<POWERUP-RECEIVE-TIME>" BO_ 949 "empty";
BA_ "GenMsgCycleTime3" BO_ 948 5000;
BA_ "GenMsgSendType3" BO_ 948 0;
BA_ "GenMsgDelayTime2" BO_ 948 100;
BA_ "GenMsgSendType2" BO_ 948 1;
BA_ "GenMsgDelayTime" BO_ 948 1000;
BA_ "GenMsgSendType" BO_ 948 1;
BA_ "<PHASE-RELATIONS><PC>" BO_ 948 "empty";
BA_ "<PHASE-RELATIONS>" BO_ 948 "empty";
BA_ "<CYCLE-TIME><PC>" BO_ 948 "empty";
BA_ "<CYCLE-TIME>" BO_ 948 "empty";
BA_ "<LATENCY-TIME><PC>" BO_ 948 "empty";
BA_ "<LATENCY-TIME>" BO_ 948 "empty";
BA_ "<POWERDOWN-RECEIVE-TIME><PC>" BO_ 948 "empty";
BA_ "<POWERDOWN-RECEIVE-TIME>" BO_ 948 "empty";
BA_ "<POWERUP-TRANSMIT-TIME><PC>" BO_ 948 "empty";
BA_ "<POWERUP-TRANSMIT-TIME>" BO_ 948 "empty";
BA_ "<POWERUP-RECEIVE-TIME><PC>" BO_ 948 "empty";
BA_ "<POWERUP-RECEIVE-TIME>" BO_ 948 "empty";
BA_ "GenMsgCycleTime3" BO_ 947 5000;
BA_ "GenMsgSendType3" BO_ 947 0;
BA_ "GenMsgDelayTime2" BO_ 947 100;
BA_ "GenMsgSendType2" BO_ 947 1;
BA_ "GenMsgDelayTime" BO_ 947 1000;
BA_ "GenMsgSendType" BO_ 947 1;
BA_ "<PHASE-RELATIONS><PC>" BO_ 947 "empty";
BA_ "<PHASE-RELATIONS>" BO_ 947 "empty";
BA_ "<CYCLE-TIME><PC>" BO_ 947 "empty";
BA_ "<CYCLE-TIME>" BO_ 947 "empty";
BA_ "<LATENCY-TIME><PC>" BO_ 947 "empty";
BA_ "<LATENCY-TIME>" BO_ 947 "empty";
BA_ "<POWERDOWN-RECEIVE-TIME><PC>" BO_ 947 "empty";
BA_ "<POWERDOWN-RECEIVE-TIME>" BO_ 947 "empty";
BA_ "<POWERUP-TRANSMIT-TIME><PC>" BO_ 947 "empty";
BA_ "<POWERUP-TRANSMIT-TIME>" BO_ 947 "empty";
BA_ "<POWERUP-RECEIVE-TIME><PC>" BO_ 947 "empty";
BA_ "<POWERUP-RECEIVE-TIME>" BO_ 947 "empty";
BA_ "GenMsgCycleTime2" BO_ 944 1000;
BA_ "GenMsgSendType2" BO_ 944 0;
BA_ "GenMsgDelayTime" BO_ 944 50;
BA_ "GenMsgSendType" BO_ 944 1;
BA_ "<PHASE-RELATIONS><PC>" BO_ 944 "empty";
BA_ "<PHASE-RELATIONS>" BO_ 944 "empty";
BA_ "<CYCLE-TIME><PC>" BO_ 944 "empty";
BA_ "<CYCLE-TIME>" BO_ 944 "empty";
BA_ "<LATENCY-TIME><PC>" BO_ 944 "empty";
BA_ "<LATENCY-TIME>" BO_ 944 "empty";
BA_ "<POWERDOWN-RECEIVE-TIME><PC>" BO_ 944 "empty";
BA_ "<POWERDOWN-RECEIVE-TIME>" BO_ 944 "empty";
BA_ "<POWERUP-TRANSMIT-TIME><PC>" BO_ 944 "empty";
BA_ "<POWERUP-TRANSMIT-TIME>" BO_ 944 "empty";
BA_ "<POWERUP-RECEIVE-TIME><PC>" BO_ 944 "empty";
BA_ "<POWERUP-RECEIVE-TIME>" BO_ 944 "empty";
BA_ "GenMsgDelayTime" BO_ 924 1000;
BA_ "GenMsgSendType" BO_ 924 1;
BA_ "<PHASE-RELATIONS><PC>" BO_ 924 "empty";
BA_ "<PHASE-RELATIONS>" BO_ 924 "empty";
BA_ "<CYCLE-TIME><PC>" BO_ 924 "empty";
BA_ "<CYCLE-TIME>" BO_ 924 "empty";
BA_ "<LATENCY-TIME><PC>" BO_ 924 "empty";
BA_ "<LATENCY-TIME>" BO_ 924 "empty";
BA_ "<POWERDOWN-RECEIVE-TIME><PC>" BO_ 924 "empty";
BA_ "<POWERDOWN-RECEIVE-TIME>" BO_ 924 "empty";
BA_ "<POWERUP-TRANSMIT-TIME><PC>" BO_ 924 "empty";
BA_ "<POWERUP-TRANSMIT-TIME>" BO_ 924 "empty";
BA_ "<POWERUP-RECEIVE-TIME><PC>" BO_ 924 "empty";
BA_ "<POWERUP-RECEIVE-TIME>" BO_ 924 "empty";
BA_ "GenMsgDelayTime" BO_ 920 200;
BA_ "GenMsgSendType" BO_ 920 1;
BA_ "<PHASE-RELATIONS><PC>" BO_ 920 "empty";
BA_ "<PHASE-RELATIONS>" BO_ 920 "empty";
BA_ "<CYCLE-TIME><PC>" BO_ 920 "empty";
BA_ "<CYCLE-TIME>" BO_ 920 "empty";
BA_ "<LATENCY-TIME><PC>" BO_ 920 "empty";
BA_ "<LATENCY-TIME>" BO_ 920 "empty";
BA_ "<POWERDOWN-RECEIVE-TIME><PC>" BO_ 920 "empty";
BA_ "<POWERDOWN-RECEIVE-TIME>" BO_ 920 "empty";
BA_ "<POWERUP-TRANSMIT-TIME><PC>" BO_ 920 "empty";
BA_ "<POWERUP-TRANSMIT-TIME>" BO_ 920 "empty";
BA_ "<POWERUP-RECEIVE-TIME><PC>" BO_ 920 "empty";
BA_ "<POWERUP-RECEIVE-TIME>" BO_ 920 "empty";
BA_ "GenMsgDelayTime2" BO_ 917 200;
BA_ "GenMsgSendType2" BO_ 917 1;
BA_ "GenMsgDelayTime" BO_ 917 50;
BA_ "GenMsgSendType" BO_ 917 1;
BA_ "<PHASE-RELATIONS><PC>" BO_ 917 "empty";
BA_ "<PHASE-RELATIONS>" BO_ 917 "empty";
BA_ "<CYCLE-TIME><PC>" BO_ 917 "empty";
BA_ "<CYCLE-TIME>" BO_ 917 "empty";
BA_ "<LATENCY-TIME><PC>" BO_ 917 "empty";
BA_ "<LATENCY-TIME>" BO_ 917 "empty";
BA_ "<POWERDOWN-RECEIVE-TIME><PC>" BO_ 917 "empty";
BA_ "<POWERDOWN-RECEIVE-TIME>" BO_ 917 "empty";
BA_ "<POWERUP-TRANSMIT-TIME><PC>" BO_ 917 "empty";
BA_ "<POWERUP-TRANSMIT-TIME>" BO_ 917 "empty";
BA_ "<POWERUP-RECEIVE-TIME><PC>" BO_ 917 "empty";
BA_ "<POWERUP-RECEIVE-TIME>" BO_ 917 "empty";
BA_ "GenMsgDelayTime2" BO_ 910 200;
BA_ "GenMsgSendType2" BO_ 910 1;
BA_ "GenMsgDelayTime" BO_ 910 50;
BA_ "GenMsgSendType" BO_ 910 1;
BA_ "<PHASE-RELATIONS><PC>" BO_ 910 "empty";
BA_ "<PHASE-RELATIONS>" BO_ 910 "empty";
BA_ "<CYCLE-TIME><PC>" BO_ 910 "empty";
BA_ "<CYCLE-TIME>" BO_ 910 "empty";
BA_ "<LATENCY-TIME><PC>" BO_ 910 "empty";
BA_ "<LATENCY-TIME>" BO_ 910 "empty";
BA_ "<POWERDOWN-RECEIVE-TIME><PC>" BO_ 910 "empty";
BA_ "<POWERDOWN-RECEIVE-TIME>" BO_ 910 "empty";
BA_ "<POWERUP-TRANSMIT-TIME><PC>" BO_ 910 "empty";
BA_ "<POWERUP-TRANSMIT-TIME>" BO_ 910 "empty";
BA_ "<POWERUP-RECEIVE-TIME><PC>" BO_ 910 "empty";
BA_ "<POWERUP-RECEIVE-TIME>" BO_ 910 "empty";
BA_ "GenMsgDelayTime2" BO_ 904 200;
BA_ "GenMsgSendType2" BO_ 904 1;
BA_ "GenMsgDelayTime" BO_ 904 50;
BA_ "GenMsgSendType" BO_ 904 1;
BA_ "<PHASE-RELATIONS><PC>" BO_ 904 "empty";
BA_ "<PHASE-RELATIONS>" BO_ 904 "empty";
BA_ "<CYCLE-TIME><PC>" BO_ 904 "empty";
BA_ "<CYCLE-TIME>" BO_ 904 "empty";
BA_ "<LATENCY-TIME><PC>" BO_ 904 "empty";
BA_ "<LATENCY-TIME>" BO_ 904 "empty";
BA_ "<POWERDOWN-RECEIVE-TIME><PC>" BO_ 904 "empty";
BA_ "<POWERDOWN-RECEIVE-TIME>" BO_ 904 "empty";
BA_ "<POWERUP-TRANSMIT-TIME><PC>" BO_ 904 "empty";
BA_ "<POWERUP-TRANSMIT-TIME>" BO_ 904 "empty";
BA_ "<POWERUP-RECEIVE-TIME><PC>" BO_ 904 "empty";
BA_ "<POWERUP-RECEIVE-TIME>" BO_ 904 "empty";
BA_ "GenMsgDelayTime2" BO_ 897 100;
BA_ "GenMsgSendType2" BO_ 897 1;
BA_ "GenMsgDelayTime" BO_ 897 50;
BA_ "GenMsgSendType" BO_ 897 1;
BA_ "<PHASE-RELATIONS><PC>" BO_ 897 "empty";
BA_ "<PHASE-RELATIONS>" BO_ 897 "empty";
BA_ "<CYCLE-TIME><PC>" BO_ 897 "empty";
BA_ "<CYCLE-TIME>" BO_ 897 "empty";
BA_ "<LATENCY-TIME><PC>" BO_ 897 "empty";
BA_ "<LATENCY-TIME>" BO_ 897 "empty";
BA_ "<POWERDOWN-RECEIVE-TIME><PC>" BO_ 897 "empty";
BA_ "<POWERDOWN-RECEIVE-TIME>" BO_ 897 "empty";
BA_ "<POWERUP-TRANSMIT-TIME><PC>" BO_ 897 "empty";
BA_ "<POWERUP-TRANSMIT-TIME>" BO_ 897 "empty";
BA_ "<POWERUP-RECEIVE-TIME><PC>" BO_ 897 "empty";
BA_ "<POWERUP-RECEIVE-TIME>" BO_ 897 "empty";
BA_ "GenMsgDelayTime2" BO_ 896 200;
BA_ "GenMsgSendType2" BO_ 896 1;
BA_ "GenMsgDelayTime" BO_ 896 50;
BA_ "GenMsgSendType" BO_ 896 1;
BA_ "<PHASE-RELATIONS><PC>" BO_ 896 "empty";
BA_ "<PHASE-RELATIONS>" BO_ 896 "empty";
BA_ "<CYCLE-TIME><PC>" BO_ 896 "empty";
BA_ "<CYCLE-TIME>" BO_ 896 "empty";
BA_ "<LATENCY-TIME><PC>" BO_ 896 "empty";
BA_ "<LATENCY-TIME>" BO_ 896 "empty";
BA_ "<POWERDOWN-RECEIVE-TIME><PC>" BO_ 896 "empty";
BA_ "<POWERDOWN-RECEIVE-TIME>" BO_ 896 "empty";
BA_ "<POWERUP-TRANSMIT-TIME><PC>" BO_ 896 "empty";
BA_ "<POWERUP-TRANSMIT-TIME>" BO_ 896 "empty";
BA_ "<POWERUP-RECEIVE-TIME><PC>" BO_ 896 "empty";
BA_ "<POWERUP-RECEIVE-TIME>" BO_ 896 "empty";
BA_ "GenMsgDelayTime" BO_ 886 50;
BA_ "GenMsgCycleTime" BO_ 886 1000;
BA_ "GenMsgSendType" BO_ 886 0;
BA_ "<PHASE-RELATIONS><PC>" BO_ 886 "empty";
BA_ "<PHASE-RELATIONS>" BO_ 886 "empty";
BA_ "<CYCLE-TIME><PC>" BO_ 886 "empty";
BA_ "<CYCLE-TIME>" BO_ 886 "empty";
BA_ "<LATENCY-TIME><PC>" BO_ 886 "empty";
BA_ "<LATENCY-TIME>" BO_ 886 "empty";
BA_ "<POWERDOWN-RECEIVE-TIME><PC>" BO_ 886 "empty";
BA_ "<POWERDOWN-RECEIVE-TIME>" BO_ 886 "empty";
BA_ "<POWERUP-TRANSMIT-TIME><PC>" BO_ 886 "empty";
BA_ "<POWERUP-TRANSMIT-TIME>" BO_ 886 "empty";
BA_ "<POWERUP-RECEIVE-TIME><PC>" BO_ 886 "empty";
BA_ "<POWERUP-RECEIVE-TIME>" BO_ 886 "empty";
BA_ "GenMsgDelayTime" BO_ 884 50;
BA_ "GenMsgCycleTime" BO_ 884 1000;
BA_ "GenMsgSendType" BO_ 884 0;
BA_ "<PHASE-RELATIONS><PC>" BO_ 884 "empty";
BA_ "<PHASE-RELATIONS>" BO_ 884 "empty";
BA_ "<CYCLE-TIME><PC>" BO_ 884 "empty";
BA_ "<CYCLE-TIME>" BO_ 884 "empty";
BA_ "<LATENCY-TIME><PC>" BO_ 884 "empty";
BA_ "<LATENCY-TIME>" BO_ 884 "empty";
BA_ "<POWERDOWN-RECEIVE-TIME><PC>" BO_ 884 "empty";
BA_ "<POWERDOWN-RECEIVE-TIME>" BO_ 884 "empty";
BA_ "<POWERUP-TRANSMIT-TIME><PC>" BO_ 884 "empty";
BA_ "<POWERUP-TRANSMIT-TIME>" BO_ 884 "empty";
BA_ "<POWERUP-RECEIVE-TIME><PC>" BO_ 884 "empty";
BA_ "<POWERUP-RECEIVE-TIME>" BO_ 884 "empty";
BA_ "GenMsgDelayTime2" BO_ 847 50;
BA_ "GenMsgSendType2" BO_ 847 1;
BA_ "GenMsgDelayTime" BO_ 847 50;
BA_ "GenMsgCycleTime" BO_ 847 5000;
BA_ "GenMsgSendType" BO_ 847 0;
BA_ "<PHASE-RELATIONS><PC>" BO_ 847 "empty";
BA_ "<PHASE-RELATIONS>" BO_ 847 "empty";
BA_ "<CYCLE-TIME><PC>" BO_ 847 "empty";
BA_ "<CYCLE-TIME>" BO_ 847 "empty";
BA_ "<LATENCY-TIME><PC>" BO_ 847 "empty";
BA_ "<LATENCY-TIME>" BO_ 847 "empty";
BA_ "<POWERDOWN-RECEIVE-TIME><PC>" BO_ 847 "empty";
BA_ "<POWERDOWN-RECEIVE-TIME>" BO_ 847 "empty";
BA_ "<POWERUP-TRANSMIT-TIME><PC>" BO_ 847 "empty";
BA_ "<POWERUP-TRANSMIT-TIME>" BO_ 847 "empty";
BA_ "<POWERUP-RECEIVE-TIME><PC>" BO_ 847 "empty";
BA_ "<POWERUP-RECEIVE-TIME>" BO_ 847 "empty";
BA_ "GenMsgDelayTime" BO_ 846 50;
BA_ "GenMsgCycleTime" BO_ 846 5000;
BA_ "GenMsgSendType" BO_ 846 0;
BA_ "<PHASE-RELATIONS><PC>" BO_ 846 "empty";
BA_ "<PHASE-RELATIONS>" BO_ 846 "empty";
BA_ "<CYCLE-TIME><PC>" BO_ 846 "empty";
BA_ "<CYCLE-TIME>" BO_ 846 "empty";
BA_ "<LATENCY-TIME><PC>" BO_ 846 "empty";
BA_ "<LATENCY-TIME>" BO_ 846 "empty";
BA_ "<POWERDOWN-RECEIVE-TIME><PC>" BO_ 846 "empty";
BA_ "<POWERDOWN-RECEIVE-TIME>" BO_ 846 "empty";
BA_ "<POWERUP-TRANSMIT-TIME><PC>" BO_ 846 "empty";
BA_ "<POWERUP-TRANSMIT-TIME>" BO_ 846 "empty";
BA_ "<POWERUP-RECEIVE-TIME><PC>" BO_ 846 "empty";
BA_ "<POWERUP-RECEIVE-TIME>" BO_ 846 "empty";
BA_ "GenMsgDelayTime" BO_ 844 50;
BA_ "GenMsgCycleTime" BO_ 844 1000;
BA_ "GenMsgSendType" BO_ 844 0;
BA_ "<PHASE-RELATIONS><PC>" BO_ 844 "empty";
BA_ "<PHASE-RELATIONS>" BO_ 844 "empty";
BA_ "<CYCLE-TIME><PC>" BO_ 844 "empty";
BA_ "<CYCLE-TIME>" BO_ 844 "empty";
BA_ "<LATENCY-TIME><PC>" BO_ 844 "empty";
BA_ "<LATENCY-TIME>" BO_ 844 "empty";
BA_ "<POWERDOWN-RECEIVE-TIME><PC>" BO_ 844 "empty";
BA_ "<POWERDOWN-RECEIVE-TIME>" BO_ 844 "empty";
BA_ "<POWERUP-TRANSMIT-TIME><PC>" BO_ 844 "empty";
BA_ "<POWERUP-TRANSMIT-TIME>" BO_ 844 "empty";
BA_ "<POWERUP-RECEIVE-TIME><PC>" BO_ 844 "empty";
BA_ "<POWERUP-RECEIVE-TIME>" BO_ 844 "empty";
BA_ "GenMsgDelayTime" BO_ 842 50;
BA_ "GenMsgCycleTime" BO_ 842 1000;
BA_ "GenMsgSendType" BO_ 842 0;
BA_ "<PHASE-RELATIONS><PC>" BO_ 842 "empty";
BA_ "<PHASE-RELATIONS>" BO_ 842 "empty";
BA_ "<CYCLE-TIME><PC>" BO_ 842 "empty";
BA_ "<CYCLE-TIME>" BO_ 842 "empty";
BA_ "<LATENCY-TIME><PC>" BO_ 842 "empty";
BA_ "<LATENCY-TIME>" BO_ 842 "empty";
BA_ "<POWERDOWN-RECEIVE-TIME><PC>" BO_ 842 "empty";
BA_ "<POWERDOWN-RECEIVE-TIME>" BO_ 842 "empty";
BA_ "<POWERUP-TRANSMIT-TIME><PC>" BO_ 842 "empty";
BA_ "<POWERUP-TRANSMIT-TIME>" BO_ 842 "empty";
BA_ "<POWERUP-RECEIVE-TIME><PC>" BO_ 842 "empty";
BA_ "<POWERUP-RECEIVE-TIME>" BO_ 842 "empty";
BA_ "GenMsgDelayTime" BO_ 840 50;
BA_ "GenMsgCycleTime" BO_ 840 200;
BA_ "GenMsgSendType" BO_ 840 0;
BA_ "<PHASE-RELATIONS><PC>" BO_ 840 "empty";
BA_ "<PHASE-RELATIONS>" BO_ 840 "empty";
BA_ "<CYCLE-TIME><PC>" BO_ 840 "empty";
BA_ "<CYCLE-TIME>" BO_ 840 "empty";
BA_ "<LATENCY-TIME><PC>" BO_ 840 "empty";
BA_ "<LATENCY-TIME>" BO_ 840 "empty";
BA_ "<POWERDOWN-RECEIVE-TIME><PC>" BO_ 840 "empty";
BA_ "<POWERDOWN-RECEIVE-TIME>" BO_ 840 "empty";
BA_ "<POWERUP-TRANSMIT-TIME><PC>" BO_ 840 "empty";
BA_ "<POWERUP-TRANSMIT-TIME>" BO_ 840 "empty";
BA_ "<POWERUP-RECEIVE-TIME><PC>" BO_ 840 "empty";
BA_ "<POWERUP-RECEIVE-TIME>" BO_ 840 "empty";
BA_ "GenMsgCycleTime2" BO_ 821 1000;
BA_ "GenMsgSendType2" BO_ 821 0;
BA_ "GenMsgDelayTime" BO_ 821 200;
BA_ "GenMsgSendType" BO_ 821 1;
BA_ "<PHASE-RELATIONS><PC>" BO_ 821 "empty";
BA_ "<PHASE-RELATIONS>" BO_ 821 "empty";
BA_ "<CYCLE-TIME><PC>" BO_ 821 "empty";
BA_ "<CYCLE-TIME>" BO_ 821 "empty";
BA_ "<LATENCY-TIME><PC>" BO_ 821 "empty";
BA_ "<LATENCY-TIME>" BO_ 821 "empty";
BA_ "<POWERDOWN-RECEIVE-TIME><PC>" BO_ 821 "empty";
BA_ "<POWERDOWN-RECEIVE-TIME>" BO_ 821 "empty";
BA_ "<POWERUP-TRANSMIT-TIME><PC>" BO_ 821 "empty";
BA_ "<POWERUP-TRANSMIT-TIME>" BO_ 821 "empty";
BA_ "<POWERUP-RECEIVE-TIME><PC>" BO_ 821 "empty";
BA_ "<POWERUP-RECEIVE-TIME>" BO_ 821 "empty";
BA_ "GenMsgCycleTime2" BO_ 820 1000;
BA_ "GenMsgSendType2" BO_ 820 0;
BA_ "GenMsgDelayTime" BO_ 820 200;
BA_ "GenMsgSendType" BO_ 820 1;
BA_ "<PHASE-RELATIONS><PC>" BO_ 820 "empty";
BA_ "<PHASE-RELATIONS>" BO_ 820 "empty";
BA_ "<CYCLE-TIME><PC>" BO_ 820 "empty";
BA_ "<CYCLE-TIME>" BO_ 820 "empty";
BA_ "<LATENCY-TIME><PC>" BO_ 820 "empty";
BA_ "<LATENCY-TIME>" BO_ 820 "empty";
BA_ "<POWERDOWN-RECEIVE-TIME><PC>" BO_ 820 "empty";
BA_ "<POWERDOWN-RECEIVE-TIME>" BO_ 820 "empty";
BA_ "<POWERUP-TRANSMIT-TIME><PC>" BO_ 820 "empty";
BA_ "<POWERUP-TRANSMIT-TIME>" BO_ 820 "empty";
BA_ "<POWERUP-RECEIVE-TIME><PC>" BO_ 820 "empty";
BA_ "<POWERUP-RECEIVE-TIME>" BO_ 820 "empty";
BA_ "GenMsgDelayTime" BO_ 818 500;
BA_ "GenMsgSendType" BO_ 818 1;
BA_ "<PHASE-RELATIONS><PC>" BO_ 818 "empty";
BA_ "<PHASE-RELATIONS>" BO_ 818 "empty";
BA_ "<CYCLE-TIME><PC>" BO_ 818 "empty";
BA_ "<CYCLE-TIME>" BO_ 818 "empty";
BA_ "<LATENCY-TIME><PC>" BO_ 818 "empty";
BA_ "<LATENCY-TIME>" BO_ 818 "empty";
BA_ "<POWERDOWN-RECEIVE-TIME><PC>" BO_ 818 "empty";
BA_ "<POWERDOWN-RECEIVE-TIME>" BO_ 818 "empty";
BA_ "<POWERUP-TRANSMIT-TIME><PC>" BO_ 818 "empty";
BA_ "<POWERUP-TRANSMIT-TIME>" BO_ 818 "empty";
BA_ "<POWERUP-RECEIVE-TIME><PC>" BO_ 818 "empty";
BA_ "<POWERUP-RECEIVE-TIME>" BO_ 818 "empty";
BA_ "GenMsgDelayTime" BO_ 817 200;
BA_ "GenMsgSendType" BO_ 817 1;
BA_ "<PHASE-RELATIONS><PC>" BO_ 817 "empty";
BA_ "<PHASE-RELATIONS>" BO_ 817 "empty";
BA_ "<CYCLE-TIME><PC>" BO_ 817 "empty";
BA_ "<CYCLE-TIME>" BO_ 817 "empty";
BA_ "<LATENCY-TIME><PC>" BO_ 817 "empty";
BA_ "<LATENCY-TIME>" BO_ 817 "empty";
BA_ "<POWERDOWN-RECEIVE-TIME><PC>" BO_ 817 "empty";
BA_ "<POWERDOWN-RECEIVE-TIME>" BO_ 817 "empty";
BA_ "<POWERUP-TRANSMIT-TIME><PC>" BO_ 817 "empty";
BA_ "<POWERUP-TRANSMIT-TIME>" BO_ 817 "empty";
BA_ "<POWERUP-RECEIVE-TIME><PC>" BO_ 817 "empty";
BA_ "<POWERUP-RECEIVE-TIME>" BO_ 817 "empty";
BA_ "GenMsgCycleTime2" BO_ 816 10000;
BA_ "GenMsgSendType2" BO_ 816 0;
BA_ "GenMsgDelayTime" BO_ 816 200;
BA_ "GenMsgSendType" BO_ 816 1;
BA_ "<PHASE-RELATIONS><PC>" BO_ 816 "empty";
BA_ "<PHASE-RELATIONS>" BO_ 816 "empty";
BA_ "<CYCLE-TIME><PC>" BO_ 816 "empty";
BA_ "<CYCLE-TIME>" BO_ 816 "empty";
BA_ "<LATENCY-TIME><PC>" BO_ 816 "empty";
BA_ "<LATENCY-TIME>" BO_ 816 "empty";
BA_ "<POWERDOWN-RECEIVE-TIME><PC>" BO_ 816 "empty";
BA_ "<POWERDOWN-RECEIVE-TIME>" BO_ 816 "empty";
BA_ "<POWERUP-TRANSMIT-TIME><PC>" BO_ 816 "empty";
BA_ "<POWERUP-TRANSMIT-TIME>" BO_ 816 "empty";
BA_ "<POWERUP-RECEIVE-TIME><PC>" BO_ 816 "empty";
BA_ "<POWERUP-RECEIVE-TIME>" BO_ 816 "empty";
BA_ "GenMsgCycleTime2" BO_ 813 1000;
BA_ "GenMsgSendType2" BO_ 813 0;
BA_ "GenMsgDelayTime" BO_ 813 200;
BA_ "GenMsgSendType" BO_ 813 1;
BA_ "<PHASE-RELATIONS><PC>" BO_ 813 "empty";
BA_ "<PHASE-RELATIONS>" BO_ 813 "empty";
BA_ "<CYCLE-TIME><PC>" BO_ 813 "empty";
BA_ "<CYCLE-TIME>" BO_ 813 "empty";
BA_ "<LATENCY-TIME><PC>" BO_ 813 "empty";
BA_ "<LATENCY-TIME>" BO_ 813 "empty";
BA_ "<POWERDOWN-RECEIVE-TIME><PC>" BO_ 813 "empty";
BA_ "<POWERDOWN-RECEIVE-TIME>" BO_ 813 "empty";
BA_ "<POWERUP-TRANSMIT-TIME><PC>" BO_ 813 "empty";
BA_ "<POWERUP-TRANSMIT-TIME>" BO_ 813 "empty";
BA_ "<POWERUP-RECEIVE-TIME><PC>" BO_ 813 "empty";
BA_ "<POWERUP-RECEIVE-TIME>" BO_ 813 "empty";
BA_ "GenMsgDelayTime" BO_ 806 50;
BA_ "GenMsgCycleTime" BO_ 806 200;
BA_ "GenMsgSendType" BO_ 806 0;
BA_ "<PHASE-RELATIONS><PC>" BO_ 806 "empty";
BA_ "<PHASE-RELATIONS>" BO_ 806 "empty";
BA_ "<CYCLE-TIME><PC>" BO_ 806 "empty";
BA_ "<CYCLE-TIME>" BO_ 806 "empty";
BA_ "<LATENCY-TIME><PC>" BO_ 806 "empty";
BA_ "<LATENCY-TIME>" BO_ 806 "empty";
BA_ "<POWERDOWN-RECEIVE-TIME><PC>" BO_ 806 "empty";
BA_ "<POWERDOWN-RECEIVE-TIME>" BO_ 806 "empty";
BA_ "<POWERUP-TRANSMIT-TIME><PC>" BO_ 806 "empty";
BA_ "<POWERUP-TRANSMIT-TIME>" BO_ 806 "empty";
BA_ "<POWERUP-RECEIVE-TIME><PC>" BO_ 806 "empty";
BA_ "<POWERUP-RECEIVE-TIME>" BO_ 806 "empty";
BA_ "GenMsgCycleTime2" BO_ 797 5000;
BA_ "GenMsgSendType2" BO_ 797 0;
BA_ "GenMsgDelayTime" BO_ 797 200;
BA_ "GenMsgSendType" BO_ 797 1;
BA_ "<PHASE-RELATIONS><PC>" BO_ 797 "empty";
BA_ "<PHASE-RELATIONS>" BO_ 797 "empty";
BA_ "<CYCLE-TIME><PC>" BO_ 797 "empty";
BA_ "<CYCLE-TIME>" BO_ 797 "empty";
BA_ "<LATENCY-TIME><PC>" BO_ 797 "empty";
BA_ "<LATENCY-TIME>" BO_ 797 "empty";
BA_ "<POWERDOWN-RECEIVE-TIME><PC>" BO_ 797 "empty";
BA_ "<POWERDOWN-RECEIVE-TIME>" BO_ 797 "empty";
BA_ "<POWERUP-TRANSMIT-TIME><PC>" BO_ 797 "empty";
BA_ "<POWERUP-TRANSMIT-TIME>" BO_ 797 "empty";
BA_ "<POWERUP-RECEIVE-TIME><PC>" BO_ 797 "empty";
BA_ "<POWERUP-RECEIVE-TIME>" BO_ 797 "empty";
BA_ "GenMsgDelayTime2" BO_ 794 160;
BA_ "GenMsgSendType2" BO_ 794 1;
BA_ "GenMsgDelayTime" BO_ 794 50;
BA_ "GenMsgCycleTime" BO_ 794 100;
BA_ "GenMsgSendType" BO_ 794 0;
BA_ "<PHASE-RELATIONS><PC>" BO_ 794 "empty";
BA_ "<PHASE-RELATIONS>" BO_ 794 "empty";
BA_ "<CYCLE-TIME><PC>" BO_ 794 "empty";
BA_ "<CYCLE-TIME>" BO_ 794 "empty";
BA_ "<LATENCY-TIME><PC>" BO_ 794 "empty";
BA_ "<LATENCY-TIME>" BO_ 794 "empty";
BA_ "<POWERDOWN-RECEIVE-TIME><PC>" BO_ 794 "empty";
BA_ "<POWERDOWN-RECEIVE-TIME>" BO_ 794 "empty";
BA_ "<POWERUP-TRANSMIT-TIME><PC>" BO_ 794 "empty";
BA_ "<POWERUP-TRANSMIT-TIME>" BO_ 794 "empty";
BA_ "<POWERUP-RECEIVE-TIME><PC>" BO_ 794 "empty";
BA_ "<POWERUP-RECEIVE-TIME>" BO_ 794 "empty";
BA_ "GenMsgDelayTime" BO_ 793 50;
BA_ "GenMsgSendType" BO_ 793 1;
BA_ "<PHASE-RELATIONS><PC>" BO_ 793 "empty";
BA_ "<PHASE-RELATIONS>" BO_ 793 "empty";
BA_ "<CYCLE-TIME><PC>" BO_ 793 "empty";
BA_ "<CYCLE-TIME>" BO_ 793 "empty";
BA_ "<LATENCY-TIME><PC>" BO_ 793 "empty";
BA_ "<LATENCY-TIME>" BO_ 793 "empty";
BA_ "<POWERDOWN-RECEIVE-TIME><PC>" BO_ 793 "empty";
BA_ "<POWERDOWN-RECEIVE-TIME>" BO_ 793 "empty";
BA_ "<POWERUP-TRANSMIT-TIME><PC>" BO_ 793 "empty";
BA_ "<POWERUP-TRANSMIT-TIME>" BO_ 793 "empty";
BA_ "<POWERUP-RECEIVE-TIME><PC>" BO_ 793 "empty";
BA_ "<POWERUP-RECEIVE-TIME>" BO_ 793 "empty";
BA_ "GenMsgCycleTime2" BO_ 790 100;
BA_ "GenMsgSendType2" BO_ 790 0;
BA_ "GenMsgDelayTime" BO_ 790 160;
BA_ "GenMsgSendType" BO_ 790 1;
BA_ "<PHASE-RELATIONS><PC>" BO_ 790 "empty";
BA_ "<PHASE-RELATIONS>" BO_ 790 "empty";
BA_ "<CYCLE-TIME><PC>" BO_ 790 "empty";
BA_ "<CYCLE-TIME>" BO_ 790 "empty";
BA_ "<LATENCY-TIME><PC>" BO_ 790 "empty";
BA_ "<LATENCY-TIME>" BO_ 790 "empty";
BA_ "<POWERDOWN-RECEIVE-TIME><PC>" BO_ 790 "empty";
BA_ "<POWERDOWN-RECEIVE-TIME>" BO_ 790 "empty";
BA_ "<POWERUP-TRANSMIT-TIME><PC>" BO_ 790 "empty";
BA_ "<POWERUP-TRANSMIT-TIME>" BO_ 790 "empty";
BA_ "<POWERUP-RECEIVE-TIME><PC>" BO_ 790 "empty";
BA_ "<POWERUP-RECEIVE-TIME>" BO_ 790 "empty";
BA_ "GenMsgCycleTime2" BO_ 789 10000;
BA_ "GenMsgSendType2" BO_ 789 0;
BA_ "GenMsgDelayTime" BO_ 789 100;
BA_ "GenMsgSendType" BO_ 789 1;
BA_ "<PHASE-RELATIONS><PC>" BO_ 789 "empty";
BA_ "<PHASE-RELATIONS>" BO_ 789 "empty";
BA_ "<CYCLE-TIME><PC>" BO_ 789 "empty";
BA_ "<CYCLE-TIME>" BO_ 789 "empty";
BA_ "<LATENCY-TIME><PC>" BO_ 789 "empty";
BA_ "<LATENCY-TIME>" BO_ 789 "empty";
BA_ "<POWERDOWN-RECEIVE-TIME><PC>" BO_ 789 "empty";
BA_ "<POWERDOWN-RECEIVE-TIME>" BO_ 789 "empty";
BA_ "<POWERUP-TRANSMIT-TIME><PC>" BO_ 789 "empty";
BA_ "<POWERUP-TRANSMIT-TIME>" BO_ 789 "empty";
BA_ "<POWERUP-RECEIVE-TIME><PC>" BO_ 789 "empty";
BA_ "<POWERUP-RECEIVE-TIME>" BO_ 789 "empty";
BA_ "GenMsgDelayTime" BO_ 785 200;
BA_ "GenMsgSendType" BO_ 785 1;
BA_ "<PHASE-RELATIONS><PC>" BO_ 785 "empty";
BA_ "<PHASE-RELATIONS>" BO_ 785 "empty";
BA_ "<CYCLE-TIME><PC>" BO_ 785 "empty";
BA_ "<CYCLE-TIME>" BO_ 785 "empty";
BA_ "<LATENCY-TIME><PC>" BO_ 785 "empty";
BA_ "<LATENCY-TIME>" BO_ 785 "empty";
BA_ "<POWERDOWN-RECEIVE-TIME><PC>" BO_ 785 "empty";
BA_ "<POWERDOWN-RECEIVE-TIME>" BO_ 785 "empty";
BA_ "<POWERUP-TRANSMIT-TIME><PC>" BO_ 785 "empty";
BA_ "<POWERUP-TRANSMIT-TIME>" BO_ 785 "empty";
BA_ "<POWERUP-RECEIVE-TIME><PC>" BO_ 785 "empty";
BA_ "<POWERUP-RECEIVE-TIME>" BO_ 785 "empty";
BA_ "GenMsgDelayTime2" BO_ 784 100;
BA_ "GenMsgSendType2" BO_ 784 1;
BA_ "GenMsgDelayTime" BO_ 784 50;
BA_ "GenMsgCycleTime" BO_ 784 1000;
BA_ "GenMsgSendType" BO_ 784 0;
BA_ "<PHASE-RELATIONS><PC>" BO_ 784 "empty";
BA_ "<PHASE-RELATIONS>" BO_ 784 "empty";
BA_ "<CYCLE-TIME><PC>" BO_ 784 "empty";
BA_ "<CYCLE-TIME>" BO_ 784 "empty";
BA_ "<LATENCY-TIME><PC>" BO_ 784 "empty";
BA_ "<LATENCY-TIME>" BO_ 784 "empty";
BA_ "<POWERDOWN-RECEIVE-TIME><PC>" BO_ 784 "empty";
BA_ "<POWERDOWN-RECEIVE-TIME>" BO_ 784 "empty";
BA_ "<POWERUP-TRANSMIT-TIME><PC>" BO_ 784 "empty";
BA_ "<POWERUP-TRANSMIT-TIME>" BO_ 784 "empty";
BA_ "<POWERUP-RECEIVE-TIME><PC>" BO_ 784 "empty";
BA_ "<POWERUP-RECEIVE-TIME>" BO_ 784 "empty";
BA_ "GenMsgCycleTime3" BO_ 764 5000;
BA_ "GenMsgSendType3" BO_ 764 0;
BA_ "GenMsgCycleTime2" BO_ 764 100;
BA_ "GenMsgSendType2" BO_ 764 0;
BA_ "GenMsgDelayTime" BO_ 764 100;
BA_ "GenMsgSendType" BO_ 764 1;
BA_ "<PHASE-RELATIONS><PC>" BO_ 764 "empty";
BA_ "<PHASE-RELATIONS>" BO_ 764 "empty";
BA_ "<CYCLE-TIME><PC>" BO_ 764 "empty";
BA_ "<CYCLE-TIME>" BO_ 764 "empty";
BA_ "<LATENCY-TIME><PC>" BO_ 764 "empty";
BA_ "<LATENCY-TIME>" BO_ 764 "empty";
BA_ "<POWERDOWN-RECEIVE-TIME><PC>" BO_ 764 "empty";
BA_ "<POWERDOWN-RECEIVE-TIME>" BO_ 764 "empty";
BA_ "<POWERUP-TRANSMIT-TIME><PC>" BO_ 764 "empty";
BA_ "<POWERUP-TRANSMIT-TIME>" BO_ 764 "empty";
BA_ "<POWERUP-RECEIVE-TIME><PC>" BO_ 764 "empty";
BA_ "<POWERUP-RECEIVE-TIME>" BO_ 764 "empty";
BA_ "GenMsgCycleTime2" BO_ 762 5000;
BA_ "GenMsgSendType2" BO_ 762 0;
BA_ "GenMsgDelayTime" BO_ 762 200;
BA_ "GenMsgSendType" BO_ 762 1;
BA_ "<PHASE-RELATIONS><PC>" BO_ 762 "empty";
BA_ "<PHASE-RELATIONS>" BO_ 762 "empty";
BA_ "<CYCLE-TIME><PC>" BO_ 762 "empty";
BA_ "<CYCLE-TIME>" BO_ 762 "empty";
BA_ "<LATENCY-TIME><PC>" BO_ 762 "empty";
BA_ "<LATENCY-TIME>" BO_ 762 "empty";
BA_ "<POWERDOWN-RECEIVE-TIME><PC>" BO_ 762 "empty";
BA_ "<POWERDOWN-RECEIVE-TIME>" BO_ 762 "empty";
BA_ "<POWERUP-TRANSMIT-TIME><PC>" BO_ 762 "empty";
BA_ "<POWERUP-TRANSMIT-TIME>" BO_ 762 "empty";
BA_ "<POWERUP-RECEIVE-TIME><PC>" BO_ 762 "empty";
BA_ "<POWERUP-RECEIVE-TIME>" BO_ 762 "empty";
BA_ "GenMsgDelayTime4" BO_ 760 200;
BA_ "GenMsgSendType4" BO_ 760 1;
BA_ "GenMsgCycleTime3" BO_ 760 15000;
BA_ "GenMsgSendType3" BO_ 760 0;
BA_ "GenMsgDelayTime2" BO_ 760 200;
BA_ "GenMsgSendType2" BO_ 760 1;
BA_ "GenMsgDelayTime" BO_ 760 200;
BA_ "GenMsgSendType" BO_ 760 1;
BA_ "<PHASE-RELATIONS><PC>" BO_ 760 "empty";
BA_ "<PHASE-RELATIONS>" BO_ 760 "empty";
BA_ "<CYCLE-TIME><PC>" BO_ 760 "empty";
BA_ "<CYCLE-TIME>" BO_ 760 "empty";
BA_ "<LATENCY-TIME><PC>" BO_ 760 "empty";
BA_ "<LATENCY-TIME>" BO_ 760 "empty";
BA_ "<POWERDOWN-RECEIVE-TIME><PC>" BO_ 760 "empty";
BA_ "<POWERDOWN-RECEIVE-TIME>" BO_ 760 "empty";
BA_ "<POWERUP-TRANSMIT-TIME><PC>" BO_ 760 "empty";
BA_ "<POWERUP-TRANSMIT-TIME>" BO_ 760 "empty";
BA_ "<POWERUP-RECEIVE-TIME><PC>" BO_ 760 "empty";
BA_ "<POWERUP-RECEIVE-TIME>" BO_ 760 "empty";
BA_ "GenMsgDelayTime" BO_ 758 200;
BA_ "GenMsgSendType" BO_ 758 1;
BA_ "<PHASE-RELATIONS><PC>" BO_ 758 "empty";
BA_ "<PHASE-RELATIONS>" BO_ 758 "empty";
BA_ "<CYCLE-TIME><PC>" BO_ 758 "empty";
BA_ "<CYCLE-TIME>" BO_ 758 "empty";
BA_ "<LATENCY-TIME><PC>" BO_ 758 "empty";
BA_ "<LATENCY-TIME>" BO_ 758 "empty";
BA_ "<POWERDOWN-RECEIVE-TIME><PC>" BO_ 758 "empty";
BA_ "<POWERDOWN-RECEIVE-TIME>" BO_ 758 "empty";
BA_ "<POWERUP-TRANSMIT-TIME><PC>" BO_ 758 "empty";
BA_ "<POWERUP-TRANSMIT-TIME>" BO_ 758 "empty";
BA_ "<POWERUP-RECEIVE-TIME><PC>" BO_ 758 "empty";
BA_ "<POWERUP-RECEIVE-TIME>" BO_ 758 "empty";
BA_ "GenMsgCycleTime2" BO_ 740 5000;
BA_ "GenMsgSendType2" BO_ 740 0;
BA_ "GenMsgDelayTime" BO_ 740 500;
BA_ "GenMsgSendType" BO_ 740 1;
BA_ "<PHASE-RELATIONS><PC>" BO_ 740 "empty";
BA_ "<PHASE-RELATIONS>" BO_ 740 "empty";
BA_ "<CYCLE-TIME><PC>" BO_ 740 "empty";
BA_ "<CYCLE-TIME>" BO_ 740 "empty";
BA_ "<LATENCY-TIME><PC>" BO_ 740 "empty";
BA_ "<LATENCY-TIME>" BO_ 740 "empty";
BA_ "<POWERDOWN-RECEIVE-TIME><PC>" BO_ 740 "empty";
BA_ "<POWERDOWN-RECEIVE-TIME>" BO_ 740 "empty";
BA_ "<POWERUP-TRANSMIT-TIME><PC>" BO_ 740 "empty";
BA_ "<POWERUP-TRANSMIT-TIME>" BO_ 740 "empty";
BA_ "<POWERUP-RECEIVE-TIME><PC>" BO_ 740 "empty";
BA_ "<POWERUP-RECEIVE-TIME>" BO_ 740 "empty";
BA_ "GenMsgDelayTime" BO_ 690 50;
BA_ "GenMsgCycleTime" BO_ 690 20;
BA_ "GenMsgSendType" BO_ 690 0;
BA_ "<PHASE-RELATIONS><PC>" BO_ 690 "empty";
BA_ "<PHASE-RELATIONS>" BO_ 690 "empty";
BA_ "<CYCLE-TIME><PC>" BO_ 690 "empty";
BA_ "<CYCLE-TIME>" BO_ 690 "empty";
BA_ "<LATENCY-TIME><PC>" BO_ 690 "empty";
BA_ "<LATENCY-TIME>" BO_ 690 "empty";
BA_ "<POWERDOWN-RECEIVE-TIME><PC>" BO_ 690 "empty";
BA_ "<POWERDOWN-RECEIVE-TIME>" BO_ 690 "empty";
BA_ "<POWERUP-TRANSMIT-TIME><PC>" BO_ 690 "empty";
BA_ "<POWERUP-TRANSMIT-TIME>" BO_ 690 "empty";
BA_ "<POWERUP-RECEIVE-TIME><PC>" BO_ 690 "empty";
BA_ "<POWERUP-RECEIVE-TIME>" BO_ 690 "empty";
BA_ "GenMsgCycleTime2" BO_ 678 1000;
BA_ "GenMsgSendType2" BO_ 678 0;
BA_ "GenMsgDelayTime" BO_ 678 50;
BA_ "GenMsgCycleTime" BO_ 678 100;
BA_ "GenMsgSendType" BO_ 678 0;
BA_ "<PHASE-RELATIONS><PC>" BO_ 678 "empty";
BA_ "<PHASE-RELATIONS>" BO_ 678 "empty";
BA_ "<CYCLE-TIME><PC>" BO_ 678 "empty";
BA_ "<CYCLE-TIME>" BO_ 678 "empty";
BA_ "<LATENCY-TIME><PC>" BO_ 678 "empty";
BA_ "<LATENCY-TIME>" BO_ 678 "empty";
BA_ "<POWERDOWN-RECEIVE-TIME><PC>" BO_ 678 "empty";
BA_ "<POWERDOWN-RECEIVE-TIME>" BO_ 678 "empty";
BA_ "<POWERUP-TRANSMIT-TIME><PC>" BO_ 678 "empty";
BA_ "<POWERUP-TRANSMIT-TIME>" BO_ 678 "empty";
BA_ "<POWERUP-RECEIVE-TIME><PC>" BO_ 678 "empty";
BA_ "<POWERUP-RECEIVE-TIME>" BO_ 678 "empty";
BA_ "GenMsgDelayTime" BO_ 634 100;
BA_ "GenMsgSendType" BO_ 634 1;
BA_ "<PHASE-RELATIONS><PC>" BO_ 634 "empty";
BA_ "<PHASE-RELATIONS>" BO_ 634 "empty";
BA_ "<CYCLE-TIME><PC>" BO_ 634 "empty";
BA_ "<CYCLE-TIME>" BO_ 634 "empty";
BA_ "<LATENCY-TIME><PC>" BO_ 634 "empty";
BA_ "<LATENCY-TIME>" BO_ 634 "empty";
BA_ "<POWERDOWN-RECEIVE-TIME><PC>" BO_ 634 "empty";
BA_ "<POWERDOWN-RECEIVE-TIME>" BO_ 634 "empty";
BA_ "<POWERUP-TRANSMIT-TIME><PC>" BO_ 634 "empty";
BA_ "<POWERUP-TRANSMIT-TIME>" BO_ 634 "empty";
BA_ "<POWERUP-RECEIVE-TIME><PC>" BO_ 634 "empty";
BA_ "<POWERUP-RECEIVE-TIME>" BO_ 634 "empty";
BA_ "GenMsgDelayTime" BO_ 632 100;
BA_ "GenMsgSendType" BO_ 632 1;
BA_ "<PHASE-RELATIONS><PC>" BO_ 632 "empty";
BA_ "<PHASE-RELATIONS>" BO_ 632 "empty";
BA_ "<CYCLE-TIME><PC>" BO_ 632 "empty";
BA_ "<CYCLE-TIME>" BO_ 632 "empty";
BA_ "<LATENCY-TIME><PC>" BO_ 632 "empty";
BA_ "<LATENCY-TIME>" BO_ 632 "empty";
BA_ "<POWERDOWN-RECEIVE-TIME><PC>" BO_ 632 "empty";
BA_ "<POWERDOWN-RECEIVE-TIME>" BO_ 632 "empty";
BA_ "<POWERUP-TRANSMIT-TIME><PC>" BO_ 632 "empty";
BA_ "<POWERUP-TRANSMIT-TIME>" BO_ 632 "empty";
BA_ "<POWERUP-RECEIVE-TIME><PC>" BO_ 632 "empty";
BA_ "<POWERUP-RECEIVE-TIME>" BO_ 632 "empty";
BA_ "GenMsgDelayTime3" BO_ 594 500;
BA_ "GenMsgSendType3" BO_ 594 1;
BA_ "GenMsgDelayTime2" BO_ 594 100;
BA_ "GenMsgSendType2" BO_ 594 1;
BA_ "GenMsgDelayTime" BO_ 594 50;
BA_ "GenMsgSendType" BO_ 594 1;
BA_ "<PHASE-RELATIONS><PC>" BO_ 594 "empty";
BA_ "<PHASE-RELATIONS>" BO_ 594 "empty";
BA_ "<CYCLE-TIME><PC>" BO_ 594 "empty";
BA_ "<CYCLE-TIME>" BO_ 594 "empty";
BA_ "<LATENCY-TIME><PC>" BO_ 594 "empty";
BA_ "<LATENCY-TIME>" BO_ 594 "empty";
BA_ "<POWERDOWN-RECEIVE-TIME><PC>" BO_ 594 "empty";
BA_ "<POWERDOWN-RECEIVE-TIME>" BO_ 594 "empty";
BA_ "<POWERUP-TRANSMIT-TIME><PC>" BO_ 594 "empty";
BA_ "<POWERUP-TRANSMIT-TIME>" BO_ 594 "empty";
BA_ "<POWERUP-RECEIVE-TIME><PC>" BO_ 594 "empty";
BA_ "<POWERUP-RECEIVE-TIME>" BO_ 594 "empty";
BA_ "GenMsgCycleTime2" BO_ 586 2000;
BA_ "GenMsgSendType2" BO_ 586 0;
BA_ "GenMsgDelayTime" BO_ 586 50;
BA_ "GenMsgSendType" BO_ 586 1;
BA_ "<PHASE-RELATIONS><PC>" BO_ 586 "empty";
BA_ "<PHASE-RELATIONS>" BO_ 586 "empty";
BA_ "<CYCLE-TIME><PC>" BO_ 586 "empty";
BA_ "<CYCLE-TIME>" BO_ 586 "empty";
BA_ "<LATENCY-TIME><PC>" BO_ 586 "empty";
BA_ "<LATENCY-TIME>" BO_ 586 "empty";
BA_ "<POWERDOWN-RECEIVE-TIME><PC>" BO_ 586 "empty";
BA_ "<POWERDOWN-RECEIVE-TIME>" BO_ 586 "empty";
BA_ "<POWERUP-TRANSMIT-TIME><PC>" BO_ 586 "empty";
BA_ "<POWERUP-TRANSMIT-TIME>" BO_ 586 "empty";
BA_ "<POWERUP-RECEIVE-TIME><PC>" BO_ 586 "empty";
BA_ "<POWERUP-RECEIVE-TIME>" BO_ 586 "empty";
BA_ "GenMsgDelayTime4" BO_ 570 50;
BA_ "GenMsgSendType4" BO_ 570 1;
BA_ "GenMsgCycleTime3" BO_ 570 100;
BA_ "GenMsgSendType3" BO_ 570 0;
BA_ "GenMsgDelayTime2" BO_ 570 50;
BA_ "GenMsgSendType2" BO_ 570 1;
BA_ "GenMsgDelayTime" BO_ 570 50;
BA_ "GenMsgSendType" BO_ 570 1;
BA_ "<PHASE-RELATIONS><PC>" BO_ 570 "empty";
BA_ "<PHASE-RELATIONS>" BO_ 570 "empty";
BA_ "<CYCLE-TIME><PC>" BO_ 570 "empty";
BA_ "<CYCLE-TIME>" BO_ 570 "empty";
BA_ "<LATENCY-TIME><PC>" BO_ 570 "empty";
BA_ "<LATENCY-TIME>" BO_ 570 "empty";
BA_ "<POWERDOWN-RECEIVE-TIME><PC>" BO_ 570 "empty";
BA_ "<POWERDOWN-RECEIVE-TIME>" BO_ 570 "empty";
BA_ "<POWERUP-TRANSMIT-TIME><PC>" BO_ 570 "empty";
BA_ "<POWERUP-TRANSMIT-TIME>" BO_ 570 "empty";
BA_ "<POWERUP-RECEIVE-TIME><PC>" BO_ 570 "empty";
BA_ "<POWERUP-RECEIVE-TIME>" BO_ 570 "empty";
BA_ "GenMsgCycleTime3" BO_ 550 8000;
BA_ "GenMsgSendType3" BO_ 550 0;
BA_ "GenMsgDelayTime2" BO_ 550 100;
BA_ "GenMsgSendType2" BO_ 550 1;
BA_ "GenMsgDelayTime" BO_ 550 50;
BA_ "GenMsgSendType" BO_ 550 1;
BA_ "<PHASE-RELATIONS><PC>" BO_ 550 "empty";
BA_ "<PHASE-RELATIONS>" BO_ 550 "empty";
BA_ "<CYCLE-TIME><PC>" BO_ 550 "empty";
BA_ "<CYCLE-TIME>" BO_ 550 "empty";
BA_ "<LATENCY-TIME><PC>" BO_ 550 "empty";
BA_ "<LATENCY-TIME>" BO_ 550 "empty";
BA_ "<POWERDOWN-RECEIVE-TIME><PC>" BO_ 550 "empty";
BA_ "<POWERDOWN-RECEIVE-TIME>" BO_ 550 "empty";
BA_ "<POWERUP-TRANSMIT-TIME><PC>" BO_ 550 "empty";
BA_ "<POWERUP-TRANSMIT-TIME>" BO_ 550 "empty";
BA_ "<POWERUP-RECEIVE-TIME><PC>" BO_ 550 "empty";
BA_ "<POWERUP-RECEIVE-TIME>" BO_ 550 "empty";
BA_ "GenMsgCycleTime2" BO_ 538 5000;
BA_ "GenMsgSendType2" BO_ 538 0;
BA_ "GenMsgDelayTime" BO_ 538 50;
BA_ "GenMsgSendType" BO_ 538 1;
BA_ "<PHASE-RELATIONS><PC>" BO_ 538 "empty";
BA_ "<PHASE-RELATIONS>" BO_ 538 "empty";
BA_ "<CYCLE-TIME><PC>" BO_ 538 "empty";
BA_ "<CYCLE-TIME>" BO_ 538 "empty";
BA_ "<LATENCY-TIME><PC>" BO_ 538 "empty";
BA_ "<LATENCY-TIME>" BO_ 538 "empty";
BA_ "<POWERDOWN-RECEIVE-TIME><PC>" BO_ 538 "empty";
BA_ "<POWERDOWN-RECEIVE-TIME>" BO_ 538 "empty";
BA_ "<POWERUP-TRANSMIT-TIME><PC>" BO_ 538 "empty";
BA_ "<POWERUP-TRANSMIT-TIME>" BO_ 538 "empty";
BA_ "<POWERUP-RECEIVE-TIME><PC>" BO_ 538 "empty";
BA_ "<POWERUP-RECEIVE-TIME>" BO_ 538 "empty";
BA_ "GenMsgCycleTime2" BO_ 512 200;
BA_ "GenMsgSendType2" BO_ 512 0;
BA_ "GenMsgDelayTime" BO_ 512 60;
BA_ "GenMsgSendType" BO_ 512 1;
BA_ "<PHASE-RELATIONS><PC>" BO_ 512 "empty";
BA_ "<PHASE-RELATIONS>" BO_ 512 "empty";
BA_ "<CYCLE-TIME><PC>" BO_ 512 "empty";
BA_ "<CYCLE-TIME>" BO_ 512 "empty";
BA_ "<LATENCY-TIME><PC>" BO_ 512 "empty";
BA_ "<LATENCY-TIME>" BO_ 512 "empty";
BA_ "<POWERDOWN-RECEIVE-TIME><PC>" BO_ 512 "empty";
BA_ "<POWERDOWN-RECEIVE-TIME>" BO_ 512 "empty";
BA_ "<POWERUP-TRANSMIT-TIME><PC>" BO_ 512 "empty";
BA_ "<POWERUP-TRANSMIT-TIME>" BO_ 512 "empty";
BA_ "<POWERUP-RECEIVE-TIME><PC>" BO_ 512 "empty";
BA_ "<POWERUP-RECEIVE-TIME>" BO_ 512 "empty";
BA_ "GenMsgCycleTime2" BO_ 508 200;
BA_ "GenMsgSendType2" BO_ 508 0;
BA_ "GenMsgDelayTime" BO_ 508 100;
BA_ "GenMsgSendType" BO_ 508 1;
BA_ "<PHASE-RELATIONS><PC>" BO_ 508 "empty";
BA_ "<PHASE-RELATIONS>" BO_ 508 "empty";
BA_ "<CYCLE-TIME><PC>" BO_ 508 "empty";
BA_ "<CYCLE-TIME>" BO_ 508 "empty";
BA_ "<LATENCY-TIME><PC>" BO_ 508 "empty";
BA_ "<LATENCY-TIME>" BO_ 508 "empty";
BA_ "<POWERDOWN-RECEIVE-TIME><PC>" BO_ 508 "empty";
BA_ "<POWERDOWN-RECEIVE-TIME>" BO_ 508 "empty";
BA_ "<POWERUP-TRANSMIT-TIME><PC>" BO_ 508 "empty";
BA_ "<POWERUP-TRANSMIT-TIME>" BO_ 508 "empty";
BA_ "<POWERUP-RECEIVE-TIME><PC>" BO_ 508 "empty";
BA_ "<POWERUP-RECEIVE-TIME>" BO_ 508 "empty";
BA_ "GenMsgCycleTime2" BO_ 507 200;
BA_ "GenMsgSendType2" BO_ 507 0;
BA_ "GenMsgDelayTime" BO_ 507 100;
BA_ "GenMsgSendType" BO_ 507 1;
BA_ "<PHASE-RELATIONS><PC>" BO_ 507 "empty";
BA_ "<PHASE-RELATIONS>" BO_ 507 "empty";
BA_ "<CYCLE-TIME><PC>" BO_ 507 "empty";
BA_ "<CYCLE-TIME>" BO_ 507 "empty";
BA_ "<LATENCY-TIME><PC>" BO_ 507 "empty";
BA_ "<LATENCY-TIME>" BO_ 507 "empty";
BA_ "<POWERDOWN-RECEIVE-TIME><PC>" BO_ 507 "empty";
BA_ "<POWERDOWN-RECEIVE-TIME>" BO_ 507 "empty";
BA_ "<POWERUP-TRANSMIT-TIME><PC>" BO_ 507 "empty";
BA_ "<POWERUP-TRANSMIT-TIME>" BO_ 507 "empty";
BA_ "<POWERUP-RECEIVE-TIME><PC>" BO_ 507 "empty";
BA_ "<POWERUP-RECEIVE-TIME>" BO_ 507 "empty";
BA_ "GenMsgDelayTime3" BO_ 502 50;
BA_ "GenMsgSendType3" BO_ 502 1;
BA_ "GenMsgCycleTime2" BO_ 502 640;
BA_ "GenMsgSendType2" BO_ 502 0;
BA_ "GenMsgDelayTime" BO_ 502 50;
BA_ "GenMsgCycleTime" BO_ 502 840;
BA_ "GenMsgSendType" BO_ 502 0;
BA_ "<PHASE-RELATIONS><PC>" BO_ 502 "empty";
BA_ "<PHASE-RELATIONS>" BO_ 502 "empty";
BA_ "<CYCLE-TIME><PC>" BO_ 502 "empty";
BA_ "<CYCLE-TIME>" BO_ 502 "empty";
BA_ "<LATENCY-TIME><PC>" BO_ 502 "empty";
BA_ "<LATENCY-TIME>" BO_ 502 "empty";
BA_ "<POWERDOWN-RECEIVE-TIME><PC>" BO_ 502 "empty";
BA_ "<POWERDOWN-RECEIVE-TIME>" BO_ 502 "empty";
BA_ "<POWERUP-TRANSMIT-TIME><PC>" BO_ 502 "empty";
BA_ "<POWERUP-TRANSMIT-TIME>" BO_ 502 "empty";
BA_ "<POWERUP-RECEIVE-TIME><PC>" BO_ 502 "empty";
BA_ "<POWERUP-RECEIVE-TIME>" BO_ 502 "empty";
BA_ "GenMsgCycleTime2" BO_ 470 1000;
BA_ "GenMsgSendType2" BO_ 470 0;
BA_ "GenMsgDelayTime" BO_ 470 50;
BA_ "GenMsgCycleTime" BO_ 470 100;
BA_ "GenMsgSendType" BO_ 470 0;
BA_ "<PHASE-RELATIONS><PC>" BO_ 470 "empty";
BA_ "<PHASE-RELATIONS>" BO_ 470 "empty";
BA_ "<CYCLE-TIME><PC>" BO_ 470 "empty";
BA_ "<CYCLE-TIME>" BO_ 470 "empty";
BA_ "<LATENCY-TIME><PC>" BO_ 470 "empty";
BA_ "<LATENCY-TIME>" BO_ 470 "empty";
BA_ "<POWERDOWN-RECEIVE-TIME><PC>" BO_ 470 "empty";
BA_ "<POWERDOWN-RECEIVE-TIME>" BO_ 470 "empty";
BA_ "<POWERUP-TRANSMIT-TIME><PC>" BO_ 470 "empty";
BA_ "<POWERUP-TRANSMIT-TIME>" BO_ 470 "empty";
BA_ "<POWERUP-RECEIVE-TIME><PC>" BO_ 470 "empty";
BA_ "<POWERUP-RECEIVE-TIME>" BO_ 470 "empty";
BA_ "GenMsgCycleTime3" BO_ 466 200;
BA_ "GenMsgSendType3" BO_ 466 0;
BA_ "GenMsgDelayTime2" BO_ 466 50;
BA_ "GenMsgSendType2" BO_ 466 1;
BA_ "GenMsgDelayTime" BO_ 466 50;
BA_ "GenMsgSendType" BO_ 466 1;
BA_ "<PHASE-RELATIONS><PC>" BO_ 466 "empty";
BA_ "<PHASE-RELATIONS>" BO_ 466 "empty";
BA_ "<CYCLE-TIME><PC>" BO_ 466 "empty";
BA_ "<CYCLE-TIME>" BO_ 466 "empty";
BA_ "<LATENCY-TIME><PC>" BO_ 466 "empty";
BA_ "<LATENCY-TIME>" BO_ 466 "empty";
BA_ "<POWERDOWN-RECEIVE-TIME><PC>" BO_ 466 "empty";
BA_ "<POWERDOWN-RECEIVE-TIME>" BO_ 466 "empty";
BA_ "<POWERUP-TRANSMIT-TIME><PC>" BO_ 466 "empty";
BA_ "<POWERUP-TRANSMIT-TIME>" BO_ 466 "empty";
BA_ "<POWERUP-RECEIVE-TIME><PC>" BO_ 466 "empty";
BA_ "<POWERUP-RECEIVE-TIME>" BO_ 466 "empty";
BA_ "GenMsgDelayTime" BO_ 464 50;
BA_ "GenMsgCycleTime" BO_ 464 100;
BA_ "GenMsgSendType" BO_ 464 0;
BA_ "<PHASE-RELATIONS><PC>" BO_ 464 "empty";
BA_ "<PHASE-RELATIONS>" BO_ 464 "empty";
BA_ "<CYCLE-TIME><PC>" BO_ 464 "empty";
BA_ "<CYCLE-TIME>" BO_ 464 "empty";
BA_ "<LATENCY-TIME><PC>" BO_ 464 "empty";
BA_ "<LATENCY-TIME>" BO_ 464 "empty";
BA_ "<POWERDOWN-RECEIVE-TIME><PC>" BO_ 464 "empty";
BA_ "<POWERDOWN-RECEIVE-TIME>" BO_ 464 "empty";
BA_ "<POWERUP-TRANSMIT-TIME><PC>" BO_ 464 "empty";
BA_ "<POWERUP-TRANSMIT-TIME>" BO_ 464 "empty";
BA_ "<POWERUP-RECEIVE-TIME><PC>" BO_ 464 "empty";
BA_ "<POWERUP-RECEIVE-TIME>" BO_ 464 "empty";
BA_ "GenMsgCycleTime2" BO_ 438 1000;
BA_ "GenMsgSendType2" BO_ 438 0;
BA_ "GenMsgDelayTime" BO_ 438 50;
BA_ "GenMsgSendType" BO_ 438 1;
BA_ "<PHASE-RELATIONS><PC>" BO_ 438 "empty";
BA_ "<PHASE-RELATIONS>" BO_ 438 "empty";
BA_ "<CYCLE-TIME><PC>" BO_ 438 "empty";
BA_ "<CYCLE-TIME>" BO_ 438 "empty";
BA_ "<LATENCY-TIME><PC>" BO_ 438 "empty";
BA_ "<LATENCY-TIME>" BO_ 438 "empty";
BA_ "<POWERDOWN-RECEIVE-TIME><PC>" BO_ 438 "empty";
BA_ "<POWERDOWN-RECEIVE-TIME>" BO_ 438 "empty";
BA_ "<POWERUP-TRANSMIT-TIME><PC>" BO_ 438 "empty";
BA_ "<POWERUP-TRANSMIT-TIME>" BO_ 438 "empty";
BA_ "<POWERUP-RECEIVE-TIME><PC>" BO_ 438 "empty";
BA_ "<POWERUP-RECEIVE-TIME>" BO_ 438 "empty";
BA_ "GenMsgCycleTime2" BO_ 437 1000;
BA_ "GenMsgSendType2" BO_ 437 0;
BA_ "GenMsgDelayTime" BO_ 437 50;
BA_ "GenMsgSendType" BO_ 437 1;
BA_ "<PHASE-RELATIONS><PC>" BO_ 437 "empty";
BA_ "<PHASE-RELATIONS>" BO_ 437 "empty";
BA_ "<CYCLE-TIME><PC>" BO_ 437 "empty";
BA_ "<CYCLE-TIME>" BO_ 437 "empty";
BA_ "<LATENCY-TIME><PC>" BO_ 437 "empty";
BA_ "<LATENCY-TIME>" BO_ 437 "empty";
BA_ "<POWERDOWN-RECEIVE-TIME><PC>" BO_ 437 "empty";
BA_ "<POWERDOWN-RECEIVE-TIME>" BO_ 437 "empty";
BA_ "<POWERUP-TRANSMIT-TIME><PC>" BO_ 437 "empty";
BA_ "<POWERUP-TRANSMIT-TIME>" BO_ 437 "empty";
BA_ "<POWERUP-RECEIVE-TIME><PC>" BO_ 437 "empty";
BA_ "<POWERUP-RECEIVE-TIME>" BO_ 437 "empty";
BA_ "GenMsgDelayTime" BO_ 436 50;
BA_ "GenMsgCycleTime" BO_ 436 100;
BA_ "GenMsgSendType" BO_ 436 0;
BA_ "<PHASE-RELATIONS><PC>" BO_ 436 "empty";
BA_ "<PHASE-RELATIONS>" BO_ 436 "empty";
BA_ "<CYCLE-TIME><PC>" BO_ 436 "empty";
BA_ "<CYCLE-TIME>" BO_ 436 "empty";
BA_ "<LATENCY-TIME><PC>" BO_ 436 "empty";
BA_ "<LATENCY-TIME>" BO_ 436 "empty";
BA_ "<POWERDOWN-RECEIVE-TIME><PC>" BO_ 436 "empty";
BA_ "<POWERDOWN-RECEIVE-TIME>" BO_ 436 "empty";
BA_ "<POWERUP-TRANSMIT-TIME><PC>" BO_ 436 "empty";
BA_ "<POWERUP-TRANSMIT-TIME>" BO_ 436 "empty";
BA_ "<POWERUP-RECEIVE-TIME><PC>" BO_ 436 "empty";
BA_ "<POWERUP-RECEIVE-TIME>" BO_ 436 "empty";
BA_ "GenMsgDelayTime" BO_ 431 50;
BA_ "GenMsgCycleTime" BO_ 431 20;
BA_ "GenMsgSendType" BO_ 431 0;
BA_ "<PHASE-RELATIONS><PC>" BO_ 431 "empty";
BA_ "<PHASE-RELATIONS>" BO_ 431 "empty";
BA_ "<CYCLE-TIME><PC>" BO_ 431 "empty";
BA_ "<CYCLE-TIME>" BO_ 431 "empty";
BA_ "<LATENCY-TIME><PC>" BO_ 431 "empty";
BA_ "<LATENCY-TIME>" BO_ 431 "empty";
BA_ "<POWERDOWN-RECEIVE-TIME><PC>" BO_ 431 "empty";
BA_ "<POWERDOWN-RECEIVE-TIME>" BO_ 431 "empty";
BA_ "<POWERUP-TRANSMIT-TIME><PC>" BO_ 431 "empty";
BA_ "<POWERUP-TRANSMIT-TIME>" BO_ 431 "empty";
BA_ "<POWERUP-RECEIVE-TIME><PC>" BO_ 431 "empty";
BA_ "<POWERUP-RECEIVE-TIME>" BO_ 431 "empty";
BA_ "GenMsgDelayTime" BO_ 428 50;
BA_ "GenMsgCycleTime" BO_ 428 20;
BA_ "GenMsgSendType" BO_ 428 0;
BA_ "<PHASE-RELATIONS><PC>" BO_ 428 "empty";
BA_ "<PHASE-RELATIONS>" BO_ 428 "empty";
BA_ "<CYCLE-TIME><PC>" BO_ 428 "empty";
BA_ "<CYCLE-TIME>" BO_ 428 "empty";
BA_ "<LATENCY-TIME><PC>" BO_ 428 "empty";
BA_ "<LATENCY-TIME>" BO_ 428 "empty";
BA_ "<POWERDOWN-RECEIVE-TIME><PC>" BO_ 428 "empty";
BA_ "<POWERDOWN-RECEIVE-TIME>" BO_ 428 "empty";
BA_ "<POWERUP-TRANSMIT-TIME><PC>" BO_ 428 "empty";
BA_ "<POWERUP-TRANSMIT-TIME>" BO_ 428 "empty";
BA_ "<POWERUP-RECEIVE-TIME><PC>" BO_ 428 "empty";
BA_ "<POWERUP-RECEIVE-TIME>" BO_ 428 "empty";
BA_ "GenMsgDelayTime" BO_ 422 50;
BA_ "GenMsgCycleTime" BO_ 422 100;
BA_ "GenMsgSendType" BO_ 422 0;
BA_ "<PHASE-RELATIONS><PC>" BO_ 422 "empty";
BA_ "<PHASE-RELATIONS>" BO_ 422 "empty";
BA_ "<CYCLE-TIME><PC>" BO_ 422 "empty";
BA_ "<CYCLE-TIME>" BO_ 422 "empty";
BA_ "<LATENCY-TIME><PC>" BO_ 422 "empty";
BA_ "<LATENCY-TIME>" BO_ 422 "empty";
BA_ "<POWERDOWN-RECEIVE-TIME><PC>" BO_ 422 "empty";
BA_ "<POWERDOWN-RECEIVE-TIME>" BO_ 422 "empty";
BA_ "<POWERUP-TRANSMIT-TIME><PC>" BO_ 422 "empty";
BA_ "<POWERUP-TRANSMIT-TIME>" BO_ 422 "empty";
BA_ "<POWERUP-RECEIVE-TIME><PC>" BO_ 422 "empty";
BA_ "<POWERUP-RECEIVE-TIME>" BO_ 422 "empty";
BA_ "GenMsgDelayTime" BO_ 419 50;
BA_ "GenMsgCycleTime" BO_ 419 20;
BA_ "GenMsgSendType" BO_ 419 0;
BA_ "<PHASE-RELATIONS><PC>" BO_ 419 "empty";
BA_ "<PHASE-RELATIONS>" BO_ 419 "empty";
BA_ "<CYCLE-TIME><PC>" BO_ 419 "empty";
BA_ "<CYCLE-TIME>" BO_ 419 "empty";
BA_ "<LATENCY-TIME><PC>" BO_ 419 "empty";
BA_ "<LATENCY-TIME>" BO_ 419 "empty";
BA_ "<POWERDOWN-RECEIVE-TIME><PC>" BO_ 419 "empty";
BA_ "<POWERDOWN-RECEIVE-TIME>" BO_ 419 "empty";
BA_ "<POWERUP-TRANSMIT-TIME><PC>" BO_ 419 "empty";
BA_ "<POWERUP-TRANSMIT-TIME>" BO_ 419 "empty";
BA_ "<POWERUP-RECEIVE-TIME><PC>" BO_ 419 "empty";
BA_ "<POWERUP-RECEIVE-TIME>" BO_ 419 "empty";
BA_ "GenMsgDelayTime" BO_ 418 50;
BA_ "GenMsgCycleTime" BO_ 418 20;
BA_ "GenMsgSendType" BO_ 418 0;
BA_ "<PHASE-RELATIONS><PC>" BO_ 418 "empty";
BA_ "<PHASE-RELATIONS>" BO_ 418 "empty";
BA_ "<CYCLE-TIME><PC>" BO_ 418 "empty";
BA_ "<CYCLE-TIME>" BO_ 418 "empty";
BA_ "<LATENCY-TIME><PC>" BO_ 418 "empty";
BA_ "<LATENCY-TIME>" BO_ 418 "empty";
BA_ "<POWERDOWN-RECEIVE-TIME><PC>" BO_ 418 "empty";
BA_ "<POWERDOWN-RECEIVE-TIME>" BO_ 418 "empty";
BA_ "<POWERUP-TRANSMIT-TIME><PC>" BO_ 418 "empty";
BA_ "<POWERUP-TRANSMIT-TIME>" BO_ 418 "empty";
BA_ "<POWERUP-RECEIVE-TIME><PC>" BO_ 418 "empty";
BA_ "<POWERUP-RECEIVE-TIME>" BO_ 418 "empty";
BA_ "GenMsgDelayTime" BO_ 416 50;
BA_ "GenMsgCycleTime" BO_ 416 20;
BA_ "GenMsgSendType" BO_ 416 0;
BA_ "<PHASE-RELATIONS><PC>" BO_ 416 "empty";
BA_ "<PHASE-RELATIONS>" BO_ 416 "empty";
BA_ "<CYCLE-TIME><PC>" BO_ 416 "empty";
BA_ "<CYCLE-TIME>" BO_ 416 "empty";
BA_ "<LATENCY-TIME><PC>" BO_ 416 "empty";
BA_ "<LATENCY-TIME>" BO_ 416 "empty";
BA_ "<POWERDOWN-RECEIVE-TIME><PC>" BO_ 416 "empty";
BA_ "<POWERDOWN-RECEIVE-TIME>" BO_ 416 "empty";
BA_ "<POWERUP-TRANSMIT-TIME><PC>" BO_ 416 "empty";
BA_ "<POWERUP-TRANSMIT-TIME>" BO_ 416 "empty";
BA_ "<POWERUP-RECEIVE-TIME><PC>" BO_ 416 "empty";
BA_ "<POWERUP-RECEIVE-TIME>" BO_ 416 "empty";
BA_ "GenMsgDelayTime" BO_ 414 50;
BA_ "GenMsgCycleTime" BO_ 414 20;
BA_ "GenMsgSendType" BO_ 414 0;
BA_ "<PHASE-RELATIONS><PC>" BO_ 414 "empty";
BA_ "<PHASE-RELATIONS>" BO_ 414 "empty";
BA_ "<CYCLE-TIME><PC>" BO_ 414 "empty";
BA_ "<CYCLE-TIME>" BO_ 414 "empty";
BA_ "<LATENCY-TIME><PC>" BO_ 414 "empty";
BA_ "<LATENCY-TIME>" BO_ 414 "empty";
BA_ "<POWERDOWN-RECEIVE-TIME><PC>" BO_ 414 "empty";
BA_ "<POWERDOWN-RECEIVE-TIME>" BO_ 414 "empty";
BA_ "<POWERUP-TRANSMIT-TIME><PC>" BO_ 414 "empty";
BA_ "<POWERUP-TRANSMIT-TIME>" BO_ 414 "empty";
BA_ "<POWERUP-RECEIVE-TIME><PC>" BO_ 414 "empty";
BA_ "<POWERUP-RECEIVE-TIME>" BO_ 414 "empty";
BA_ "GenMsgDelayTime" BO_ 412 50;
BA_ "GenMsgSendType" BO_ 412 1;
BA_ "<PHASE-RELATIONS><PC>" BO_ 412 "empty";
BA_ "<PHASE-RELATIONS>" BO_ 412 "empty";
BA_ "<CYCLE-TIME><PC>" BO_ 412 "empty";
BA_ "<CYCLE-TIME>" BO_ 412 "empty";
BA_ "<LATENCY-TIME><PC>" BO_ 412 "empty";
BA_ "<LATENCY-TIME>" BO_ 412 "empty";
BA_ "<POWERDOWN-RECEIVE-TIME><PC>" BO_ 412 "empty";
BA_ "<POWERDOWN-RECEIVE-TIME>" BO_ 412 "empty";
BA_ "<POWERUP-TRANSMIT-TIME><PC>" BO_ 412 "empty";
BA_ "<POWERUP-TRANSMIT-TIME>" BO_ 412 "empty";
BA_ "<POWERUP-RECEIVE-TIME><PC>" BO_ 412 "empty";
BA_ "<POWERUP-RECEIVE-TIME>" BO_ 412 "empty";
BA_ "GenMsgCycleTime2" BO_ 404 200;
BA_ "GenMsgSendType2" BO_ 404 0;
BA_ "GenMsgDelayTime" BO_ 404 50;
BA_ "GenMsgSendType" BO_ 404 1;
BA_ "<PHASE-RELATIONS><PC>" BO_ 404 "empty";
BA_ "<PHASE-RELATIONS>" BO_ 404 "empty";
BA_ "<CYCLE-TIME><PC>" BO_ 404 "empty";
BA_ "<CYCLE-TIME>" BO_ 404 "empty";
BA_ "<LATENCY-TIME><PC>" BO_ 404 "empty";
BA_ "<LATENCY-TIME>" BO_ 404 "empty";
BA_ "<POWERDOWN-RECEIVE-TIME><PC>" BO_ 404 "empty";
BA_ "<POWERDOWN-RECEIVE-TIME>" BO_ 404 "empty";
BA_ "<POWERUP-TRANSMIT-TIME><PC>" BO_ 404 "empty";
BA_ "<POWERUP-TRANSMIT-TIME>" BO_ 404 "empty";
BA_ "<POWERUP-RECEIVE-TIME><PC>" BO_ 404 "empty";
BA_ "<POWERUP-RECEIVE-TIME>" BO_ 404 "empty";
BA_ "GenMsgDelayTime" BO_ 402 50;
BA_ "GenMsgCycleTime" BO_ 402 30;
BA_ "GenMsgSendType" BO_ 402 0;
BA_ "<PHASE-RELATIONS><PC>" BO_ 402 "empty";
BA_ "<PHASE-RELATIONS>" BO_ 402 "empty";
BA_ "<CYCLE-TIME><PC>" BO_ 402 "empty";
BA_ "<CYCLE-TIME>" BO_ 402 "empty";
BA_ "<LATENCY-TIME><PC>" BO_ 402 "empty";
BA_ "<LATENCY-TIME>" BO_ 402 "empty";
BA_ "<POWERDOWN-RECEIVE-TIME><PC>" BO_ 402 "empty";
BA_ "<POWERDOWN-RECEIVE-TIME>" BO_ 402 "empty";
BA_ "<POWERUP-TRANSMIT-TIME><PC>" BO_ 402 "empty";
BA_ "<POWERUP-TRANSMIT-TIME>" BO_ 402 "empty";
BA_ "<POWERUP-RECEIVE-TIME><PC>" BO_ 402 "empty";
BA_ "<POWERUP-RECEIVE-TIME>" BO_ 402 "empty";
BA_ "GenMsgDelayTime" BO_ 400 50;
BA_ "GenMsgCycleTime" BO_ 400 100;
BA_ "GenMsgSendType" BO_ 400 0;
BA_ "<PHASE-RELATIONS><PC>" BO_ 400 "empty";
BA_ "<PHASE-RELATIONS>" BO_ 400 "empty";
BA_ "<CYCLE-TIME><PC>" BO_ 400 "empty";
BA_ "<CYCLE-TIME>" BO_ 400 "empty";
BA_ "<LATENCY-TIME><PC>" BO_ 400 "empty";
BA_ "<LATENCY-TIME>" BO_ 400 "empty";
BA_ "<POWERDOWN-RECEIVE-TIME><PC>" BO_ 400 "empty";
BA_ "<POWERDOWN-RECEIVE-TIME>" BO_ 400 "empty";
BA_ "<POWERUP-TRANSMIT-TIME><PC>" BO_ 400 "empty";
BA_ "<POWERUP-TRANSMIT-TIME>" BO_ 400 "empty";
BA_ "<POWERUP-RECEIVE-TIME><PC>" BO_ 400 "empty";
BA_ "<POWERUP-RECEIVE-TIME>" BO_ 400 "empty";
BA_ "GenMsgDelayTime" BO_ 372 50;
BA_ "GenMsgSendType" BO_ 372 1;
BA_ "<PHASE-RELATIONS><PC>" BO_ 372 "empty";
BA_ "<PHASE-RELATIONS>" BO_ 372 "empty";
BA_ "<CYCLE-TIME><PC>" BO_ 372 "empty";
BA_ "<CYCLE-TIME>" BO_ 372 "empty";
BA_ "<LATENCY-TIME><PC>" BO_ 372 "empty";
BA_ "<LATENCY-TIME>" BO_ 372 "empty";
BA_ "<POWERDOWN-RECEIVE-TIME><PC>" BO_ 372 "empty";
BA_ "<POWERDOWN-RECEIVE-TIME>" BO_ 372 "empty";
BA_ "<POWERUP-TRANSMIT-TIME><PC>" BO_ 372 "empty";
BA_ "<POWERUP-TRANSMIT-TIME>" BO_ 372 "empty";
BA_ "<POWERUP-RECEIVE-TIME><PC>" BO_ 372 "empty";
BA_ "<POWERUP-RECEIVE-TIME>" BO_ 372 "empty";
BA_ "GenMsgDelayTime" BO_ 354 50;
BA_ "GenMsgCycleTime" BO_ 354 20;
BA_ "GenMsgSendType" BO_ 354 0;
BA_ "<PHASE-RELATIONS><PC>" BO_ 354 "empty";
BA_ "<PHASE-RELATIONS>" BO_ 354 "empty";
BA_ "<CYCLE-TIME><PC>" BO_ 354 "empty";
BA_ "<CYCLE-TIME>" BO_ 354 "empty";
BA_ "<LATENCY-TIME><PC>" BO_ 354 "empty";
BA_ "<LATENCY-TIME>" BO_ 354 "empty";
BA_ "<POWERDOWN-RECEIVE-TIME><PC>" BO_ 354 "empty";
BA_ "<POWERDOWN-RECEIVE-TIME>" BO_ 354 "empty";
BA_ "<POWERUP-TRANSMIT-TIME><PC>" BO_ 354 "empty";
BA_ "<POWERUP-TRANSMIT-TIME>" BO_ 354 "empty";
BA_ "<POWERUP-RECEIVE-TIME><PC>" BO_ 354 "empty";
BA_ "<POWERUP-RECEIVE-TIME>" BO_ 354 "empty";
BA_ "GenMsgDelayTime" BO_ 351 50;
BA_ "GenMsgCycleTime" BO_ 351 20;
BA_ "GenMsgSendType" BO_ 351 0;
BA_ "<PHASE-RELATIONS><PC>" BO_ 351 "empty";
BA_ "<PHASE-RELATIONS>" BO_ 351 "empty";
BA_ "<CYCLE-TIME><PC>" BO_ 351 "empty";
BA_ "<CYCLE-TIME>" BO_ 351 "empty";
BA_ "<LATENCY-TIME><PC>" BO_ 351 "empty";
BA_ "<LATENCY-TIME>" BO_ 351 "empty";
BA_ "<POWERDOWN-RECEIVE-TIME><PC>" BO_ 351 "empty";
BA_ "<POWERDOWN-RECEIVE-TIME>" BO_ 351 "empty";
BA_ "<POWERUP-TRANSMIT-TIME><PC>" BO_ 351 "empty";
BA_ "<POWERUP-TRANSMIT-TIME>" BO_ 351 "empty";
BA_ "<POWERUP-RECEIVE-TIME><PC>" BO_ 351 "empty";
BA_ "<POWERUP-RECEIVE-TIME>" BO_ 351 "empty";
BA_ "GenMsgDelayTime" BO_ 348 50;
BA_ "GenMsgCycleTime" BO_ 348 100;
BA_ "GenMsgSendType" BO_ 348 0;
BA_ "<PHASE-RELATIONS><PC>" BO_ 348 "empty";
BA_ "<PHASE-RELATIONS>" BO_ 348 "empty";
BA_ "<CYCLE-TIME><PC>" BO_ 348 "empty";
BA_ "<CYCLE-TIME>" BO_ 348 "empty";
BA_ "<LATENCY-TIME><PC>" BO_ 348 "empty";
BA_ "<LATENCY-TIME>" BO_ 348 "empty";
BA_ "<POWERDOWN-RECEIVE-TIME><PC>" BO_ 348 "empty";
BA_ "<POWERDOWN-RECEIVE-TIME>" BO_ 348 "empty";
BA_ "<POWERUP-TRANSMIT-TIME><PC>" BO_ 348 "empty";
BA_ "<POWERUP-TRANSMIT-TIME>" BO_ 348 "empty";
BA_ "<POWERUP-RECEIVE-TIME><PC>" BO_ 348 "empty";
BA_ "<POWERUP-RECEIVE-TIME>" BO_ 348 "empty";
BA_ "GenMsgDelayTime" BO_ 345 50;
BA_ "GenMsgCycleTime" BO_ 345 100;
BA_ "GenMsgSendType" BO_ 345 0;
BA_ "<PHASE-RELATIONS><PC>" BO_ 345 "empty";
BA_ "<PHASE-RELATIONS>" BO_ 345 "empty";
BA_ "<CYCLE-TIME><PC>" BO_ 345 "empty";
BA_ "<CYCLE-TIME>" BO_ 345 "empty";
BA_ "<LATENCY-TIME><PC>" BO_ 345 "empty";
BA_ "<LATENCY-TIME>" BO_ 345 "empty";
BA_ "<POWERDOWN-RECEIVE-TIME><PC>" BO_ 345 "empty";
BA_ "<POWERDOWN-RECEIVE-TIME>" BO_ 345 "empty";
BA_ "<POWERUP-TRANSMIT-TIME><PC>" BO_ 345 "empty";
BA_ "<POWERUP-TRANSMIT-TIME>" BO_ 345 "empty";
BA_ "<POWERUP-RECEIVE-TIME><PC>" BO_ 345 "empty";
BA_ "<POWERUP-RECEIVE-TIME>" BO_ 345 "empty";
BA_ "GenMsgDelayTime" BO_ 339 50;
BA_ "GenMsgCycleTime" BO_ 339 20;
BA_ "GenMsgSendType" BO_ 339 0;
BA_ "<PHASE-RELATIONS><PC>" BO_ 339 "empty";
BA_ "<PHASE-RELATIONS>" BO_ 339 "empty";
BA_ "<CYCLE-TIME><PC>" BO_ 339 "empty";
BA_ "<CYCLE-TIME>" BO_ 339 "empty";
BA_ "<LATENCY-TIME><PC>" BO_ 339 "empty";
BA_ "<LATENCY-TIME>" BO_ 339 "empty";
BA_ "<POWERDOWN-RECEIVE-TIME><PC>" BO_ 339 "empty";
BA_ "<POWERDOWN-RECEIVE-TIME>" BO_ 339 "empty";
BA_ "<POWERUP-TRANSMIT-TIME><PC>" BO_ 339 "empty";
BA_ "<POWERUP-TRANSMIT-TIME>" BO_ 339 "empty";
BA_ "<POWERUP-RECEIVE-TIME><PC>" BO_ 339 "empty";
BA_ "<POWERUP-RECEIVE-TIME>" BO_ 339 "empty";
BA_ "GenMsgDelayTime" BO_ 336 50;
BA_ "GenMsgCycleTime" BO_ 336 20;
BA_ "GenMsgSendType" BO_ 336 0;
BA_ "<PHASE-RELATIONS><PC>" BO_ 336 "empty";
BA_ "<PHASE-RELATIONS>" BO_ 336 "empty";
BA_ "<CYCLE-TIME><PC>" BO_ 336 "empty";
BA_ "<CYCLE-TIME>" BO_ 336 "empty";
BA_ "<LATENCY-TIME><PC>" BO_ 336 "empty";
BA_ "<LATENCY-TIME>" BO_ 336 "empty";
BA_ "<POWERDOWN-RECEIVE-TIME><PC>" BO_ 336 "empty";
BA_ "<POWERDOWN-RECEIVE-TIME>" BO_ 336 "empty";
BA_ "<POWERUP-TRANSMIT-TIME><PC>" BO_ 336 "empty";
BA_ "<POWERUP-TRANSMIT-TIME>" BO_ 336 "empty";
BA_ "<POWERUP-RECEIVE-TIME><PC>" BO_ 336 "empty";
BA_ "<POWERUP-RECEIVE-TIME>" BO_ 336 "empty";
BA_ "GenMsgCycleTime2" BO_ 309 10000;
BA_ "GenMsgSendType2" BO_ 309 0;
BA_ "GenMsgDelayTime" BO_ 309 50;
BA_ "GenMsgSendType" BO_ 309 1;
BA_ "<PHASE-RELATIONS><PC>" BO_ 309 "empty";
BA_ "<PHASE-RELATIONS>" BO_ 309 "empty";
BA_ "<CYCLE-TIME><PC>" BO_ 309 "empty";
BA_ "<CYCLE-TIME>" BO_ 309 "empty";
BA_ "<LATENCY-TIME><PC>" BO_ 309 "empty";
BA_ "<LATENCY-TIME>" BO_ 309 "empty";
BA_ "<POWERDOWN-RECEIVE-TIME><PC>" BO_ 309 "empty";
BA_ "<POWERDOWN-RECEIVE-TIME>" BO_ 309 "empty";
BA_ "<POWERUP-TRANSMIT-TIME><PC>" BO_ 309 "empty";
BA_ "<POWERUP-TRANSMIT-TIME>" BO_ 309 "empty";
BA_ "<POWERUP-RECEIVE-TIME><PC>" BO_ 309 "empty";
BA_ "<POWERUP-RECEIVE-TIME>" BO_ 309 "empty";
BA_ "GenMsgCycleTime2" BO_ 304 100;
BA_ "GenMsgSendType2" BO_ 304 0;
BA_ "GenMsgDelayTime" BO_ 304 50;
BA_ "GenMsgSendType" BO_ 304 1;
BA_ "<PHASE-RELATIONS><PC>" BO_ 304 "empty";
BA_ "<PHASE-RELATIONS>" BO_ 304 "empty";
BA_ "<CYCLE-TIME><PC>" BO_ 304 "empty";
BA_ "<CYCLE-TIME>" BO_ 304 "empty";
BA_ "<LATENCY-TIME><PC>" BO_ 304 "empty";
BA_ "<LATENCY-TIME>" BO_ 304 "empty";
BA_ "<POWERDOWN-RECEIVE-TIME><PC>" BO_ 304 "empty";
BA_ "<POWERDOWN-RECEIVE-TIME>" BO_ 304 "empty";
BA_ "<POWERUP-TRANSMIT-TIME><PC>" BO_ 304 "empty";
BA_ "<POWERUP-TRANSMIT-TIME>" BO_ 304 "empty";
BA_ "<POWERUP-RECEIVE-TIME><PC>" BO_ 304 "empty";
BA_ "<POWERUP-RECEIVE-TIME>" BO_ 304 "empty";
BA_ "GenMsgDelayTime" BO_ 224 50;
BA_ "GenMsgCycleTime" BO_ 224 20;
BA_ "GenMsgSendType" BO_ 224 0;
BA_ "<PHASE-RELATIONS><PC>" BO_ 224 "empty";
BA_ "<PHASE-RELATIONS>" BO_ 224 "empty";
BA_ "<CYCLE-TIME><PC>" BO_ 224 "empty";
BA_ "<CYCLE-TIME>" BO_ 224 "empty";
BA_ "<LATENCY-TIME><PC>" BO_ 224 "empty";
BA_ "<LATENCY-TIME>" BO_ 224 "empty";
BA_ "<POWERDOWN-RECEIVE-TIME><PC>" BO_ 224 "empty";
BA_ "<POWERDOWN-RECEIVE-TIME>" BO_ 224 "empty";
BA_ "<POWERUP-TRANSMIT-TIME><PC>" BO_ 224 "empty";
BA_ "<POWERUP-TRANSMIT-TIME>" BO_ 224 "empty";
BA_ "<POWERUP-RECEIVE-TIME><PC>" BO_ 224 "empty";
BA_ "<POWERUP-RECEIVE-TIME>" BO_ 224 "empty";
BA_ "GenMsgDelayTime" BO_ 225 50;
BA_ "GenMsgCycleTime" BO_ 225 20;
BA_ "GenMsgSendType" BO_ 225 0;
BA_ "<PHASE-RELATIONS><PC>" BO_ 225 "empty";
BA_ "<PHASE-RELATIONS>" BO_ 225 "empty";
BA_ "<CYCLE-TIME><PC>" BO_ 225 "empty";
BA_ "<CYCLE-TIME>" BO_ 225 "empty";
BA_ "<LATENCY-TIME><PC>" BO_ 225 "empty";
BA_ "<LATENCY-TIME>" BO_ 225 "empty";
BA_ "<POWERDOWN-RECEIVE-TIME><PC>" BO_ 225 "empty";
BA_ "<POWERDOWN-RECEIVE-TIME>" BO_ 225 "empty";
BA_ "<POWERUP-TRANSMIT-TIME><PC>" BO_ 225 "empty";
BA_ "<POWERUP-TRANSMIT-TIME>" BO_ 225 "empty";
BA_ "<POWERUP-RECEIVE-TIME><PC>" BO_ 225 "empty";
BA_ "<POWERUP-RECEIVE-TIME>" BO_ 225 "empty";
BA_ "GenMsgDelayTime" BO_ 213 50;
BA_ "GenMsgCycleTime" BO_ 213 20;
BA_ "GenMsgSendType" BO_ 213 0;
BA_ "<PHASE-RELATIONS><PC>" BO_ 213 "empty";
BA_ "<PHASE-RELATIONS>" BO_ 213 "empty";
BA_ "<CYCLE-TIME><PC>" BO_ 213 "empty";
BA_ "<CYCLE-TIME>" BO_ 213 "empty";
BA_ "<LATENCY-TIME><PC>" BO_ 213 "empty";
BA_ "<LATENCY-TIME>" BO_ 213 "empty";
BA_ "<POWERDOWN-RECEIVE-TIME><PC>" BO_ 213 "empty";
BA_ "<POWERDOWN-RECEIVE-TIME>" BO_ 213 "empty";
BA_ "<POWERUP-TRANSMIT-TIME><PC>" BO_ 213 "empty";
BA_ "<POWERUP-TRANSMIT-TIME>" BO_ 213 "empty";
BA_ "<POWERUP-RECEIVE-TIME><PC>" BO_ 213 "empty";
BA_ "<POWERUP-RECEIVE-TIME>" BO_ 213 "empty";
BA_ "GenMsgDelayTime" BO_ 206 50;
BA_ "GenMsgCycleTime" BO_ 206 20;
BA_ "GenMsgSendType" BO_ 206 0;
BA_ "<PHASE-RELATIONS><PC>" BO_ 206 "empty";
BA_ "<PHASE-RELATIONS>" BO_ 206 "empty";
BA_ "<CYCLE-TIME><PC>" BO_ 206 "empty";
BA_ "<CYCLE-TIME>" BO_ 206 "empty";
BA_ "<LATENCY-TIME><PC>" BO_ 206 "empty";
BA_ "<LATENCY-TIME>" BO_ 206 "empty";
BA_ "<POWERDOWN-RECEIVE-TIME><PC>" BO_ 206 "empty";
BA_ "<POWERDOWN-RECEIVE-TIME>" BO_ 206 "empty";
BA_ "<POWERUP-TRANSMIT-TIME><PC>" BO_ 206 "empty";
BA_ "<POWERUP-TRANSMIT-TIME>" BO_ 206 "empty";
BA_ "<POWERUP-RECEIVE-TIME><PC>" BO_ 206 "empty";
BA_ "<POWERUP-RECEIVE-TIME>" BO_ 206 "empty";
BA_ "GenMsgDelayTime" BO_ 203 20;
BA_ "GenMsgSendType" BO_ 203 1;
BA_ "<PHASE-RELATIONS><PC>" BO_ 203 "empty";
BA_ "<PHASE-RELATIONS>" BO_ 203 "empty";
BA_ "<CYCLE-TIME><PC>" BO_ 203 "empty";
BA_ "<CYCLE-TIME>" BO_ 203 "empty";
BA_ "<LATENCY-TIME><PC>" BO_ 203 "empty";
BA_ "<LATENCY-TIME>" BO_ 203 "empty";
BA_ "<POWERDOWN-RECEIVE-TIME><PC>" BO_ 203 "empty";
BA_ "<POWERDOWN-RECEIVE-TIME>" BO_ 203 "empty";
BA_ "<POWERUP-TRANSMIT-TIME><PC>" BO_ 203 "empty";
BA_ "<POWERUP-TRANSMIT-TIME>" BO_ 203 "empty";
BA_ "<POWERUP-RECEIVE-TIME><PC>" BO_ 203 "empty";
BA_ "<POWERUP-RECEIVE-TIME>" BO_ 203 "empty";
BA_ "GenMsgDelayTime" BO_ 202 20;
BA_ "GenMsgSendType" BO_ 202 1;
BA_ "<PHASE-RELATIONS><PC>" BO_ 202 "empty";
BA_ "<PHASE-RELATIONS>" BO_ 202 "empty";
BA_ "<CYCLE-TIME><PC>" BO_ 202 "empty";
BA_ "<CYCLE-TIME>" BO_ 202 "empty";
BA_ "<LATENCY-TIME><PC>" BO_ 202 "empty";
BA_ "<LATENCY-TIME>" BO_ 202 "empty";
BA_ "<POWERDOWN-RECEIVE-TIME><PC>" BO_ 202 "empty";
BA_ "<POWERDOWN-RECEIVE-TIME>" BO_ 202 "empty";
BA_ "<POWERUP-TRANSMIT-TIME><PC>" BO_ 202 "empty";
BA_ "<POWERUP-TRANSMIT-TIME>" BO_ 202 "empty";
BA_ "<POWERUP-RECEIVE-TIME><PC>" BO_ 202 "empty";
BA_ "<POWERUP-RECEIVE-TIME>" BO_ 202 "empty";
BA_ "GenMsgDelayTime" BO_ 200 50;
BA_ "GenMsgCycleTime" BO_ 200 10;
BA_ "GenMsgSendType" BO_ 200 0;
BA_ "<PHASE-RELATIONS><PC>" BO_ 200 "empty";
BA_ "<PHASE-RELATIONS>" BO_ 200 "empty";
BA_ "<CYCLE-TIME><PC>" BO_ 200 "empty";
BA_ "<CYCLE-TIME>" BO_ 200 "empty";
BA_ "<LATENCY-TIME><PC>" BO_ 200 "empty";
BA_ "<LATENCY-TIME>" BO_ 200 "empty";
BA_ "<POWERDOWN-RECEIVE-TIME><PC>" BO_ 200 "empty";
BA_ "<POWERDOWN-RECEIVE-TIME>" BO_ 200 "empty";
BA_ "<POWERUP-TRANSMIT-TIME><PC>" BO_ 200 "empty";
BA_ "<POWERUP-TRANSMIT-TIME>" BO_ 200 "empty";
BA_ "<POWERUP-RECEIVE-TIME><PC>" BO_ 200 "empty";
BA_ "<POWERUP-RECEIVE-TIME>" BO_ 200 "empty";
BA_ "GenMsgDelayTime" BO_ 196 50;
BA_ "GenMsgCycleTime" BO_ 196 10;
BA_ "GenMsgSendType" BO_ 196 0;
BA_ "<PHASE-RELATIONS><PC>" BO_ 196 "empty";
BA_ "<PHASE-RELATIONS>" BO_ 196 "empty";
BA_ "<CYCLE-TIME><PC>" BO_ 196 "empty";
BA_ "<CYCLE-TIME>" BO_ 196 "empty";
BA_ "<LATENCY-TIME><PC>" BO_ 196 "empty";
BA_ "<LATENCY-TIME>" BO_ 196 "empty";
BA_ "<POWERDOWN-RECEIVE-TIME><PC>" BO_ 196 "empty";
BA_ "<POWERDOWN-RECEIVE-TIME>" BO_ 196 "empty";
BA_ "<POWERUP-TRANSMIT-TIME><PC>" BO_ 196 "empty";
BA_ "<POWERUP-TRANSMIT-TIME>" BO_ 196 "empty";
BA_ "<POWERUP-RECEIVE-TIME><PC>" BO_ 196 "empty";
BA_ "<POWERUP-RECEIVE-TIME>" BO_ 196 "empty";
BA_ "GenMsgDelayTime" BO_ 191 50;
BA_ "GenMsgCycleTime" BO_ 191 20;
BA_ "GenMsgSendType" BO_ 191 0;
BA_ "<PHASE-RELATIONS><PC>" BO_ 191 "empty";
BA_ "<PHASE-RELATIONS>" BO_ 191 "empty";
BA_ "<CYCLE-TIME><PC>" BO_ 191 "empty";
BA_ "<CYCLE-TIME>" BO_ 191 "empty";
BA_ "<LATENCY-TIME><PC>" BO_ 191 "empty";
BA_ "<LATENCY-TIME>" BO_ 191 "empty";
BA_ "<POWERDOWN-RECEIVE-TIME><PC>" BO_ 191 "empty";
BA_ "<POWERDOWN-RECEIVE-TIME>" BO_ 191 "empty";
BA_ "<POWERUP-TRANSMIT-TIME><PC>" BO_ 191 "empty";
BA_ "<POWERUP-TRANSMIT-TIME>" BO_ 191 "empty";
BA_ "<POWERUP-RECEIVE-TIME><PC>" BO_ 191 "empty";
BA_ "<POWERUP-RECEIVE-TIME>" BO_ 191 "empty";
BA_ "GenMsgDelayTime" BO_ 189 50;
BA_ "GenMsgCycleTime" BO_ 189 10;
BA_ "GenMsgSendType" BO_ 189 0;
BA_ "<PHASE-RELATIONS><PC>" BO_ 189 "empty";
BA_ "<PHASE-RELATIONS>" BO_ 189 "empty";
BA_ "<CYCLE-TIME><PC>" BO_ 189 "empty";
BA_ "<CYCLE-TIME>" BO_ 189 "empty";
BA_ "<LATENCY-TIME><PC>" BO_ 189 "empty";
BA_ "<LATENCY-TIME>" BO_ 189 "empty";
BA_ "<POWERDOWN-RECEIVE-TIME><PC>" BO_ 189 "empty";
BA_ "<POWERDOWN-RECEIVE-TIME>" BO_ 189 "empty";
BA_ "<POWERUP-TRANSMIT-TIME><PC>" BO_ 189 "empty";
BA_ "<POWERUP-TRANSMIT-TIME>" BO_ 189 "empty";
BA_ "<POWERUP-RECEIVE-TIME><PC>" BO_ 189 "empty";
BA_ "<POWERUP-RECEIVE-TIME>" BO_ 189 "empty";
BA_ "GenMsgCycleTime2" BO_ 188 20;
BA_ "GenMsgSendType2" BO_ 188 0;
BA_ "GenMsgDelayTime" BO_ 188 10;
BA_ "GenMsgSendType" BO_ 188 1;
BA_ "<PHASE-RELATIONS><PC>" BO_ 188 "empty";
BA_ "<PHASE-RELATIONS>" BO_ 188 "empty";
BA_ "<CYCLE-TIME><PC>" BO_ 188 "empty";
BA_ "<CYCLE-TIME>" BO_ 188 "empty";
BA_ "<LATENCY-TIME><PC>" BO_ 188 "empty";
BA_ "<LATENCY-TIME>" BO_ 188 "empty";
BA_ "<POWERDOWN-RECEIVE-TIME><PC>" BO_ 188 "empty";
BA_ "<POWERDOWN-RECEIVE-TIME>" BO_ 188 "empty";
BA_ "<POWERUP-TRANSMIT-TIME><PC>" BO_ 188 "empty";
BA_ "<POWERUP-TRANSMIT-TIME>" BO_ 188 "empty";
BA_ "<POWERUP-RECEIVE-TIME><PC>" BO_ 188 "empty";
BA_ "<POWERUP-RECEIVE-TIME>" BO_ 188 "empty";
BA_ "GenMsgDelayTime2" BO_ 187 10;
BA_ "GenMsgSendType2" BO_ 187 1;
BA_ "GenMsgDelayTime" BO_ 187 50;
BA_ "GenMsgCycleTime" BO_ 187 20;
BA_ "GenMsgSendType" BO_ 187 0;
BA_ "<PHASE-RELATIONS><PC>" BO_ 187 "empty";
BA_ "<PHASE-RELATIONS>" BO_ 187 "empty";
BA_ "<CYCLE-TIME><PC>" BO_ 187 "empty";
BA_ "<CYCLE-TIME>" BO_ 187 "empty";
BA_ "<LATENCY-TIME><PC>" BO_ 187 "empty";
BA_ "<LATENCY-TIME>" BO_ 187 "empty";
BA_ "<POWERDOWN-RECEIVE-TIME><PC>" BO_ 187 "empty";
BA_ "<POWERDOWN-RECEIVE-TIME>" BO_ 187 "empty";
BA_ "<POWERUP-TRANSMIT-TIME><PC>" BO_ 187 "empty";
BA_ "<POWERUP-TRANSMIT-TIME>" BO_ 187 "empty";
BA_ "<POWERUP-RECEIVE-TIME><PC>" BO_ 187 "empty";
BA_ "<POWERUP-RECEIVE-TIME>" BO_ 187 "empty";
BA_ "GenMsgDelayTime" BO_ 186 50;
BA_ "GenMsgCycleTime" BO_ 186 20;
BA_ "GenMsgSendType" BO_ 186 0;
BA_ "<PHASE-RELATIONS><PC>" BO_ 186 "empty";
BA_ "<PHASE-RELATIONS>" BO_ 186 "empty";
BA_ "<CYCLE-TIME><PC>" BO_ 186 "empty";
BA_ "<CYCLE-TIME>" BO_ 186 "empty";
BA_ "<LATENCY-TIME><PC>" BO_ 186 "empty";
BA_ "<LATENCY-TIME>" BO_ 186 "empty";
BA_ "<POWERDOWN-RECEIVE-TIME><PC>" BO_ 186 "empty";
BA_ "<POWERDOWN-RECEIVE-TIME>" BO_ 186 "empty";
BA_ "<POWERUP-TRANSMIT-TIME><PC>" BO_ 186 "empty";
BA_ "<POWERUP-TRANSMIT-TIME>" BO_ 186 "empty";
BA_ "<POWERUP-RECEIVE-TIME><PC>" BO_ 186 "empty";
BA_ "<POWERUP-RECEIVE-TIME>" BO_ 186 "empty";
BA_ "GenMsgDelayTime" BO_ 185 50;
BA_ "GenMsgCycleTime" BO_ 185 20;
BA_ "GenMsgSendType" BO_ 185 0;
BA_ "<PHASE-RELATIONS><PC>" BO_ 185 "empty";
BA_ "<PHASE-RELATIONS>" BO_ 185 "empty";
BA_ "<CYCLE-TIME><PC>" BO_ 185 "empty";
BA_ "<CYCLE-TIME>" BO_ 185 "empty";
BA_ "<LATENCY-TIME><PC>" BO_ 185 "empty";
BA_ "<LATENCY-TIME>" BO_ 185 "empty";
BA_ "<POWERDOWN-RECEIVE-TIME><PC>" BO_ 185 "empty";
BA_ "<POWERDOWN-RECEIVE-TIME>" BO_ 185 "empty";
BA_ "<POWERUP-TRANSMIT-TIME><PC>" BO_ 185 "empty";
BA_ "<POWERUP-TRANSMIT-TIME>" BO_ 185 "empty";
BA_ "<POWERUP-RECEIVE-TIME><PC>" BO_ 185 "empty";
BA_ "<POWERUP-RECEIVE-TIME>" BO_ 185 "empty";
BA_ "GenMsgDelayTime" BO_ 183 50;
BA_ "GenMsgCycleTime" BO_ 183 20;
BA_ "GenMsgSendType" BO_ 183 0;
BA_ "<PHASE-RELATIONS><PC>" BO_ 183 "empty";
BA_ "<PHASE-RELATIONS>" BO_ 183 "empty";
BA_ "<CYCLE-TIME><PC>" BO_ 183 "empty";
BA_ "<CYCLE-TIME>" BO_ 183 "empty";
BA_ "<LATENCY-TIME><PC>" BO_ 183 "empty";
BA_ "<LATENCY-TIME>" BO_ 183 "empty";
BA_ "<POWERDOWN-RECEIVE-TIME><PC>" BO_ 183 "empty";
BA_ "<POWERDOWN-RECEIVE-TIME>" BO_ 183 "empty";
BA_ "<POWERUP-TRANSMIT-TIME><PC>" BO_ 183 "empty";
BA_ "<POWERUP-TRANSMIT-TIME>" BO_ 183 "empty";
BA_ "<POWERUP-RECEIVE-TIME><PC>" BO_ 183 "empty";
BA_ "<POWERUP-RECEIVE-TIME>" BO_ 183 "empty";
BA_ "GenMsgDelayTime" BO_ 182 50;
BA_ "GenMsgCycleTime" BO_ 182 20;
BA_ "GenMsgSendType" BO_ 182 0;
BA_ "<PHASE-RELATIONS><PC>" BO_ 182 "empty";
BA_ "<PHASE-RELATIONS>" BO_ 182 "empty";
BA_ "<CYCLE-TIME><PC>" BO_ 182 "empty";
BA_ "<CYCLE-TIME>" BO_ 182 "empty";
BA_ "<LATENCY-TIME><PC>" BO_ 182 "empty";
BA_ "<LATENCY-TIME>" BO_ 182 "empty";
BA_ "<POWERDOWN-RECEIVE-TIME><PC>" BO_ 182 "empty";
BA_ "<POWERDOWN-RECEIVE-TIME>" BO_ 182 "empty";
BA_ "<POWERUP-TRANSMIT-TIME><PC>" BO_ 182 "empty";
BA_ "<POWERUP-TRANSMIT-TIME>" BO_ 182 "empty";
BA_ "<POWERUP-RECEIVE-TIME><PC>" BO_ 182 "empty";
BA_ "<POWERUP-RECEIVE-TIME>" BO_ 182 "empty";
BA_ "GenMsgDelayTime" BO_ 181 50;
BA_ "GenMsgCycleTime" BO_ 181 10;
BA_ "GenMsgSendType" BO_ 181 0;
BA_ "<PHASE-RELATIONS><PC>" BO_ 181 "empty";
BA_ "<PHASE-RELATIONS>" BO_ 181 "empty";
BA_ "<CYCLE-TIME><PC>" BO_ 181 "empty";
BA_ "<CYCLE-TIME>" BO_ 181 "empty";
BA_ "<LATENCY-TIME><PC>" BO_ 181 "empty";
BA_ "<LATENCY-TIME>" BO_ 181 "empty";
BA_ "<POWERDOWN-RECEIVE-TIME><PC>" BO_ 181 "empty";
BA_ "<POWERDOWN-RECEIVE-TIME>" BO_ 181 "empty";
BA_ "<POWERUP-TRANSMIT-TIME><PC>" BO_ 181 "empty";
BA_ "<POWERUP-TRANSMIT-TIME>" BO_ 181 "empty";
BA_ "<POWERUP-RECEIVE-TIME><PC>" BO_ 181 "empty";
BA_ "<POWERUP-RECEIVE-TIME>" BO_ 181 "empty";
BA_ "GenMsgDelayTime" BO_ 179 50;
BA_ "GenMsgCycleTime" BO_ 179 10;
BA_ "GenMsgSendType" BO_ 179 0;
BA_ "<PHASE-RELATIONS><PC>" BO_ 179 "empty";
BA_ "<PHASE-RELATIONS>" BO_ 179 "empty";
BA_ "<CYCLE-TIME><PC>" BO_ 179 "empty";
BA_ "<CYCLE-TIME>" BO_ 179 "empty";
BA_ "<LATENCY-TIME><PC>" BO_ 179 "empty";
BA_ "<LATENCY-TIME>" BO_ 179 "empty";
BA_ "<POWERDOWN-RECEIVE-TIME><PC>" BO_ 179 "empty";
BA_ "<POWERDOWN-RECEIVE-TIME>" BO_ 179 "empty";
BA_ "<POWERUP-TRANSMIT-TIME><PC>" BO_ 179 "empty";
BA_ "<POWERUP-TRANSMIT-TIME>" BO_ 179 "empty";
BA_ "<POWERUP-RECEIVE-TIME><PC>" BO_ 179 "empty";
BA_ "<POWERUP-RECEIVE-TIME>" BO_ 179 "empty";
BA_ "GenMsgDelayTime" BO_ 174 50;
BA_ "GenMsgCycleTime" BO_ 174 20;
BA_ "GenMsgSendType" BO_ 174 0;
BA_ "<PHASE-RELATIONS><PC>" BO_ 174 "empty";
BA_ "<PHASE-RELATIONS>" BO_ 174 "empty";
BA_ "<CYCLE-TIME><PC>" BO_ 174 "empty";
BA_ "<CYCLE-TIME>" BO_ 174 "empty";
BA_ "<LATENCY-TIME><PC>" BO_ 174 "empty";
BA_ "<LATENCY-TIME>" BO_ 174 "empty";
BA_ "<POWERDOWN-RECEIVE-TIME><PC>" BO_ 174 "empty";
BA_ "<POWERDOWN-RECEIVE-TIME>" BO_ 174 "empty";
BA_ "<POWERUP-TRANSMIT-TIME><PC>" BO_ 174 "empty";
BA_ "<POWERUP-TRANSMIT-TIME>" BO_ 174 "empty";
BA_ "<POWERUP-RECEIVE-TIME><PC>" BO_ 174 "empty";
BA_ "<POWERUP-RECEIVE-TIME>" BO_ 174 "empty";
BA_ "GenMsgDelayTime" BO_ 173 50;
BA_ "GenMsgCycleTime" BO_ 173 20;
BA_ "GenMsgSendType" BO_ 173 0;
BA_ "<PHASE-RELATIONS><PC>" BO_ 173 "empty";
BA_ "<PHASE-RELATIONS>" BO_ 173 "empty";
BA_ "<CYCLE-TIME><PC>" BO_ 173 "empty";
BA_ "<CYCLE-TIME>" BO_ 173 "empty";
BA_ "<LATENCY-TIME><PC>" BO_ 173 "empty";
BA_ "<LATENCY-TIME>" BO_ 173 "empty";
BA_ "<POWERDOWN-RECEIVE-TIME><PC>" BO_ 173 "empty";
BA_ "<POWERDOWN-RECEIVE-TIME>" BO_ 173 "empty";
BA_ "<POWERUP-TRANSMIT-TIME><PC>" BO_ 173 "empty";
BA_ "<POWERUP-TRANSMIT-TIME>" BO_ 173 "empty";
BA_ "<POWERUP-RECEIVE-TIME><PC>" BO_ 173 "empty";
BA_ "<POWERUP-RECEIVE-TIME>" BO_ 173 "empty";
BA_ "GenMsgDelayTime" BO_ 172 50;
BA_ "GenMsgCycleTime" BO_ 172 20;
BA_ "GenMsgSendType" BO_ 172 0;
BA_ "<PHASE-RELATIONS><PC>" BO_ 172 "empty";
BA_ "<PHASE-RELATIONS>" BO_ 172 "empty";
BA_ "<CYCLE-TIME><PC>" BO_ 172 "empty";
BA_ "<CYCLE-TIME>" BO_ 172 "empty";
BA_ "<LATENCY-TIME><PC>" BO_ 172 "empty";
BA_ "<LATENCY-TIME>" BO_ 172 "empty";
BA_ "<POWERDOWN-RECEIVE-TIME><PC>" BO_ 172 "empty";
BA_ "<POWERDOWN-RECEIVE-TIME>" BO_ 172 "empty";
BA_ "<POWERUP-TRANSMIT-TIME><PC>" BO_ 172 "empty";
BA_ "<POWERUP-TRANSMIT-TIME>" BO_ 172 "empty";
BA_ "<POWERUP-RECEIVE-TIME><PC>" BO_ 172 "empty";
BA_ "<POWERUP-RECEIVE-TIME>" BO_ 172 "empty";
BA_ "GenMsgDelayTime" BO_ 171 50;
BA_ "GenMsgCycleTime" BO_ 171 20;
BA_ "GenMsgSendType" BO_ 171 0;
BA_ "<PHASE-RELATIONS><PC>" BO_ 171 "empty";
BA_ "<PHASE-RELATIONS>" BO_ 171 "empty";
BA_ "<CYCLE-TIME><PC>" BO_ 171 "empty";
BA_ "<CYCLE-TIME>" BO_ 171 "empty";
BA_ "<LATENCY-TIME><PC>" BO_ 171 "empty";
BA_ "<LATENCY-TIME>" BO_ 171 "empty";
BA_ "<POWERDOWN-RECEIVE-TIME><PC>" BO_ 171 "empty";
BA_ "<POWERDOWN-RECEIVE-TIME>" BO_ 171 "empty";
BA_ "<POWERUP-TRANSMIT-TIME><PC>" BO_ 171 "empty";
BA_ "<POWERUP-TRANSMIT-TIME>" BO_ 171 "empty";
BA_ "<POWERUP-RECEIVE-TIME><PC>" BO_ 171 "empty";
BA_ "<POWERUP-RECEIVE-TIME>" BO_ 171 "empty";
BA_ "GenMsgDelayTime" BO_ 170 50;
BA_ "GenMsgCycleTime" BO_ 170 10;
BA_ "GenMsgSendType" BO_ 170 0;
BA_ "<PHASE-RELATIONS><PC>" BO_ 170 "empty";
BA_ "<PHASE-RELATIONS>" BO_ 170 "empty";
BA_ "<CYCLE-TIME><PC>" BO_ 170 "empty";
BA_ "<CYCLE-TIME>" BO_ 170 "empty";
BA_ "<LATENCY-TIME><PC>" BO_ 170 "empty";
BA_ "<LATENCY-TIME>" BO_ 170 "empty";
BA_ "<POWERDOWN-RECEIVE-TIME><PC>" BO_ 170 "empty";
BA_ "<POWERDOWN-RECEIVE-TIME>" BO_ 170 "empty";
BA_ "<POWERUP-TRANSMIT-TIME><PC>" BO_ 170 "empty";
BA_ "<POWERUP-TRANSMIT-TIME>" BO_ 170 "empty";
BA_ "<POWERUP-RECEIVE-TIME><PC>" BO_ 170 "empty";
BA_ "<POWERUP-RECEIVE-TIME>" BO_ 170 "empty";
BA_ "GenMsgDelayTime" BO_ 169 50;
BA_ "GenMsgCycleTime" BO_ 169 10;
BA_ "GenMsgSendType" BO_ 169 0;
BA_ "<PHASE-RELATIONS><PC>" BO_ 169 "empty";
BA_ "<PHASE-RELATIONS>" BO_ 169 "empty";
BA_ "<CYCLE-TIME><PC>" BO_ 169 "empty";
BA_ "<CYCLE-TIME>" BO_ 169 "empty";
BA_ "<LATENCY-TIME><PC>" BO_ 169 "empty";
BA_ "<LATENCY-TIME>" BO_ 169 "empty";
BA_ "<POWERDOWN-RECEIVE-TIME><PC>" BO_ 169 "empty";
BA_ "<POWERDOWN-RECEIVE-TIME>" BO_ 169 "empty";
BA_ "<POWERUP-TRANSMIT-TIME><PC>" BO_ 169 "empty";
BA_ "<POWERUP-TRANSMIT-TIME>" BO_ 169 "empty";
BA_ "<POWERUP-RECEIVE-TIME><PC>" BO_ 169 "empty";
BA_ "<POWERUP-RECEIVE-TIME>" BO_ 169 "empty";
BA_ "GenMsgDelayTime" BO_ 168 50;
BA_ "GenMsgCycleTime" BO_ 168 10;
BA_ "GenMsgSendType" BO_ 168 0;
BA_ "<PHASE-RELATIONS><PC>" BO_ 168 "empty";
BA_ "<PHASE-RELATIONS>" BO_ 168 "empty";
BA_ "<CYCLE-TIME><PC>" BO_ 168 "empty";
BA_ "<CYCLE-TIME>" BO_ 168 "empty";
BA_ "<LATENCY-TIME><PC>" BO_ 168 "empty";
BA_ "<LATENCY-TIME>" BO_ 168 "empty";
BA_ "<POWERDOWN-RECEIVE-TIME><PC>" BO_ 168 "empty";
BA_ "<POWERDOWN-RECEIVE-TIME>" BO_ 168 "empty";
BA_ "<POWERUP-TRANSMIT-TIME><PC>" BO_ 168 "empty";
BA_ "<POWERUP-TRANSMIT-TIME>" BO_ 168 "empty";
BA_ "<POWERUP-RECEIVE-TIME><PC>" BO_ 168 "empty";
BA_ "<POWERUP-RECEIVE-TIME>" BO_ 168 "empty";
VAL_ 403 ALIV_COU_ACC_DCC 15 "Signal ungültig" ;
VAL_ 403 DISP_RQSP_DR 255 "Signal ungültig" 254 "Keine Setzgeschwindigkeit" ;
VAL_ 403 UN_DISP_RQSP_DR 3 "Signal ungültig" 1 "Einheit mph" 0 "Einheit km/h" ;
VAL_ 403 ST_RQSP_DR 3 "Signal ungültig" 1 "Geschwindigkeitsregelung aktiv" 0 "Geschwindigkeitsregelung nicht a" ;
VAL_ 403 ST_SAFG_IDLN_DV 3 "Signal ungültig" 2 "Stillstandsabsicherung durch Fah" 0 "keine Stillstandsabsicherung dur" ;
VAL_ 403 ST_ACC_DCC_CTRL_INFO 255 "Signal ungültig" ;
VAL_ 403 ST_DVOR 7 "Signal ungültig" 2 "Fahrerübernahme 2" 1 "Fahrerübernahme 1" 0 "keine Fahrerübernahme" ;
VAL_ 403 GAPC_DR 7 "Signal ungültig" 5 "Abstandsstufe 4" 4 "Abstandsstufe 3" 3 "Abstandsstufe 2" 2 "Abstandsstufe 1" 0 "kein Abstand aktiv" ;
VAL_ 403 ST_ACC_DCC_MOD 7 "Signal ungültig" 5 "Fehler" 4 "Aktiv Brake only" 3 "Aktiv normal" 2 "Standby" 1 "Standby Silent" 0 "Passiv" ;
VAL_ 403 CTR_DISP_ACC_DCC 3 "Signal ungültig" 1 "Anzeigeaufforderung ACC_DCC" 0 "Keine Anzeigeanforderung" ;
VAL_ 403 OP_ACC_DCC 255 "Signal ungültig" ;
VAL_ 403 AVL_GAP_TARO 255 "Siganl ungültig" 254 "keine Anzeige" ;
VAL_ 186 ST_GR_GRB 12 "8. Gang" 11 "7. Gang" 10 "6. Gang" 9 "5. Gang" 8 "4. Gang" 7 "3. Gang" 6 "2. Gang" 5 "1. Gang" 4 "Reserve" 3 "P" 2 "R" 1 "N" 0 "Reserve" ;
